VERSION ""

NS_ :

BS_:

BU_: Airbag Allrad EPS Teves_MK60_ESP LWS LWR Teves_MK70_MABS Waehlhebel EPB TRW_ESP ACC_Radar AFS Magne_Ride RKA_Plus Selespeed Waehlhebel_Sele PDC_PLA Lenkhilfe_APA VAQ Daempfer Hybrid_BMS Hybrid_PWR Hybrid_DQ200 EKlimakomp SWA HCA ACC_Lidar Lenkhilfe_ZF_3G FLA AG6 DQ Hybrid_MSG Diesel Otto Gateway_PQ35_A Gateway_PQ46_A Vector_XXX Fzg_CAN

BO_ 648 mMotor_2: 8 Hybrid_MSG
 SG_ MO2_CAN_Vers m0 : 0|6@1+ (1,0) [0|63] ""  AG6,Gateway_PQ46_A,DQ,TRW_ESP,ACC_Radar,Gateway_PQ35_A,Hybrid_DQ200,Selespeed,ACC_Lidar
 SG_ MO2_Mp_Code M : 6|2@1+ (1,0) [0|3] ""  AG6,Gateway_PQ46_A,Allrad,Teves_MK60_ESP,Teves_MK70_MABS,DQ,TRW_ESP,ACC_Radar,Gateway_PQ35_A,RKA_Plus,Hybrid_DQ200,Selespeed,EPB,ACC_Lidar
 SG_ MO2_Kuehlm_T : 8|8@1+ (0.75,-48) [-47.25|142.5] "°C"  AG6,Gateway_PQ46_A,DQ,TRW_ESP,Gateway_PQ35_A,Magne_Ride,RKA_Plus,Hybrid_DQ200,Selespeed,Hybrid_PWR
 SG_ MO2_BTS : 17|1@1+ (1,0) [0|1] ""  AG6,Gateway_PQ46_A,Allrad,DQ,EPB,TRW_ESP,ACC_Radar,Gateway_PQ35_A,Magne_Ride,Hybrid_DQ200,Selespeed,ACC_Lidar
 SG_ MO2_BLS : 16|1@1+ (1,0) [0|1] ""  AG6,Gateway_PQ46_A,Allrad,DQ,EPB,TRW_ESP,ACC_Radar,Gateway_PQ35_A,Magne_Ride,Daempfer,Hybrid_DQ200,Selespeed,ACC_Lidar
 SG_ MO2_Sta_No_Bet : 20|1@1+ (1,0) [0|1] ""  Gateway_PQ46_A,Teves_MK60_ESP,Teves_MK70_MABS,TRW_ESP,Gateway_PQ35_A
 SG_ MO2_Sta_Klima : 19|1@1+ (1,0) [0|1] ""  AG6,Gateway_PQ46_A,DQ,TRW_ESP,Gateway_PQ35_A,Hybrid_DQ200
 SG_ MO2_Status_TSK : 21|1@1+ (1,0) [0|1] ""  Gateway_PQ46_A,TRW_ESP,Gateway_PQ35_A,ACC_Radar,ACC_Lidar
 SG_ MO2_Sta_GRA : 22|2@1+ (1,0) [0|3] ""  AG6,Gateway_PQ46_A,DQ,TRW_ESP,ACC_Radar,Gateway_PQ35_A,RKA_Plus,Hybrid_DQ200,Selespeed,ACC_Lidar
 SG_ MO2_Sta_Kuehlm : 18|1@1+ (1,0) [0|1] ""  AG6,Gateway_PQ46_A,DQ,TRW_ESP,Gateway_PQ35_A,Hybrid_DQ200,Hybrid_PWR
 SG_ MO2_LL_Solldz : 40|8@1+ (10,0) [0|2540] "1/min"  AG6,Gateway_PQ46_A,DQ,TRW_ESP,Gateway_PQ35_A,Hybrid_DQ200,Selespeed
 SG_ MO2_Sport_Error : 27|1@1+ (1,0) [0|1] ""  Gateway_PQ46_A,Gateway_PQ35_A,TRW_ESP
 SG_ MO2_Motor_Code m1 : 0|6@1+ (1,0) [0|63] ""  AG6,Gateway_PQ46_A,DQ,TRW_ESP,ACC_Radar,Gateway_PQ35_A,Hybrid_DQ200,Selespeed,EPB,ACC_Lidar,Teves_MK60_ESP,Teves_MK70_MABS
 SG_ MO2_Mo_ZWR : 56|8@1+ (0.39,0) [0|99.06] "%MDI"  AG6,Gateway_PQ46_A,DQ,TRW_ESP,Gateway_PQ35_A,Hybrid_DQ200
 SG_ MO2_Begr_Mo : 48|8@1+ (0.39,0) [0|99.06] "%MDI"  AG6,Gateway_PQ46_A,DQ,TRW_ESP,Gateway_PQ35_A,Hybrid_DQ200
 SG_ MO2_Getr_Code m2 : 0|6@1+ (1,0) [0|63] ""  AG6,Gateway_PQ46_A,Teves_MK60_ESP,Teves_MK70_MABS,DQ,TRW_ESP,Gateway_PQ35_A,RKA_Plus,Hybrid_DQ200,Selespeed,EPB
 SG_ MO2_max_Mo m3 : 0|6@1+ (10,0) [0|630] "Nm"  AG6,Gateway_PQ46_A,Allrad,DQ,TRW_ESP,Gateway_PQ35_A,RKA_Plus,Hybrid_DQ200,Selespeed,EPB
 SG_ MO2_Sta_Limiter : 24|2@1+ (1,0) [0|3] ""  Gateway_PQ46_A,Gateway_PQ35_A,TRW_ESP
 SG_ MO2_RME_Gehalt : 29|3@1+ (12.5,0) [0|75] "%"  Gateway_PQ46_A,Gateway_PQ35_A,TRW_ESP
 SG_ MO2_GRAregelt : 26|1@1+ (1,0) [0|1] ""  Gateway_PQ46_A,DQ,TRW_ESP,Gateway_PQ35_A,Hybrid_DQ200
 SG_ MO2_OffRoad : 28|1@1+ (1,0) [0|1] ""  AG6,Gateway_PQ46_A,TRW_ESP,Gateway_PQ35_A
 SG_ MO2_GRA_Soll : 32|8@1+ (1.28,0) [0|325.12] "km/h"  AG6,Gateway_PQ46_A,DQ,TRW_ESP,Gateway_PQ35_A,Hybrid_DQ200

BO_ 1416 mMotor_7: 8 Hybrid_MSG
 SG_ MO7_Sta_VBegr : 2|1@1+ (1,0) [0|1] ""  Gateway_PQ46_A,Gateway_PQ35_A
 SG_ MO7_Fehlereintr : 3|1@1+ (1,0) [0|1] ""  Gateway_PQ46_A,Gateway_PQ35_A
 SG_ MO7_DFM : 8|8@1+ (0.4,0) [0|101.6] "%"  Gateway_PQ46_A,Gateway_PQ35_A
 SG_ MO7_Sta_PTC : 5|3@1+ (1,0) [0|7] ""  Gateway_PQ46_A,Gateway_PQ35_A
 SG_ MO7_Fehler_VBegr : 1|1@1+ (1,0) [0|1] ""  Gateway_PQ46_A,Gateway_PQ35_A
 SG_ MO7_StaOeltemp : 4|1@1+ (1,0) [0|1] ""  Gateway_PQ46_A,Gateway_PQ35_A
 SG_ MO7_LL_Solldz : 0|1@1+ (1,0) [0|1] ""  Gateway_PQ46_A,Gateway_PQ35_A
 SG_ MO7_Gradient_Dz : 24|7@1+ (1,0) [0|126] "1/min"  Gateway_PQ46_A,Gateway_PQ35_A
 SG_ MO7_GradientVorz : 31|1@1+ (1,0) [0|1] ""  Gateway_PQ46_A,Gateway_PQ35_A
 SG_ MO7_Hoeheninfo : 16|8@1+ (0.0078125,0) [0|1.984375] ""  Gateway_PQ46_A,DQ,Gateway_PQ35_A,Selespeed,Teves_MK60_ESP,Teves_MK70_MABS,TRW_ESP
 SG_ MO7_RueckLLDz : 47|1@1+ (1,0) [0|1] ""  Gateway_PQ46_A,Gateway_PQ35_A
 SG_ MO7_Oeltemp : 56|8@1+ (1,-60) [-58|194] "°C"  Gateway_PQ46_A,Gateway_PQ35_A,Selespeed
 SG_ MO7_PTC_bereit : 42|2@1+ (1,0) [0|3] ""  Gateway_PQ46_A,Gateway_PQ35_A
 SG_ MO7_Gen_ein : 50|1@1+ (1,0) [0|1] ""  Gateway_PQ46_A,Gateway_PQ35_A
 SG_ MO7_Lastabwurf : 48|2@1+ (1,0) [0|3] ""  Gateway_PQ46_A,Gateway_PQ35_A
 SG_ MO7_StaGluehk : 52|4@1+ (8,0) [0|112] "%"  Gateway_PQ46_A,Gateway_PQ35_A
 SG_ MO7_Lastabw_Heiz : 51|1@1+ (1,0) [0|1] ""  Gateway_PQ46_A,Gateway_PQ35_A
 SG_ MO7_GenLdResp : 40|2@1+ (3,0) [0|9] "s"  Gateway_PQ46_A,Gateway_PQ35_A
 SG_ MO7_SleepInd : 46|1@1+ (1,0) [0|1] ""  Gateway_PQ46_A,Gateway_PQ35_A
 SG_ MO7_Zus_Kuehl : 45|1@1+ (1,0) [0|1] ""  Gateway_PQ46_A,Gateway_PQ35_A
 SG_ MO7_Mot_weckfaehig : 44|1@1+ (1,0) [0|1] ""  Gateway_PQ46_A,Gateway_PQ35_A
 SG_ MO7_Ladedruckneu : 32|8@1+ (0.02,0) [0|5.08] "bar"  Gateway_PQ35_A,Gateway_PQ46_A

BO_ 1408 mMotor_Flexia_neu: 8 Hybrid_MSG
 SG_ MFN_Offset_Nachf m1 : 52|6@1+ (10,0) [0|630] "ml"  Gateway_PQ46_A,Gateway_PQ35_A,TRW_ESP
 SG_ MFN_Ansaugsys m0 : 63|1@1+ (1,0) [0|1] ""  Gateway_PQ46_A,TRW_ESP,Gateway_PQ35_A
 SG_ MFN_Tol_Oelwarn m1 : 58|6@1+ (10,0) [0|630] "ml"  Gateway_PQ46_A,Gateway_PQ35_A,TRW_ESP
 SG_ MFN_AnzMitOel m1 : 40|4@1+ (100,0) [0|1500] ""  Gateway_PQ46_A,Gateway_PQ35_A,TRW_ESP
 SG_ MFN_max_Moment m0 : 32|8@1+ (10,0) [0|2550] "Nm"  Gateway_PQ46_A,Gateway_PQ35_A,TRW_ESP
 SG_ MFN_Motorleistung m0 : 40|9@1+ (1,0) [0|511] "kW"  Gateway_PQ46_A,TRW_ESP,ACC_Radar,Gateway_PQ35_A,EPB,ACC_Lidar
 SG_ MFN_Drz_max_Mo m0 : 24|8@1+ (100,0) [0|25500] "1/min"  Gateway_PQ46_A,Gateway_PQ35_A,TRW_ESP
 SG_ MFN_Hubraum m0 : 56|7@1+ (0.1,0) [0|12.7] "l"  Gateway_PQ46_A,TRW_ESP,Gateway_PQ35_A,EPB
 SG_ MFN_Max_Offset m1 : 44|4@1+ (50,0) [0|750] "ml"  Gateway_PQ46_A,Gateway_PQ35_A,TRW_ESP
 SG_ MFN_KurzzeitMW m1 : 24|8@1+ (15,-1905) [-1890|1905] "ml"  Gateway_PQ46_A,Gateway_PQ35_A,TRW_ESP
 SG_ MFN_Russindex m0 : 8|16@1+ (2E-008,0) [0|0.00131068] ""  Gateway_PQ46_A,Gateway_PQ35_A,TRW_ESP
 SG_ MFN_NormedTrip : 6|1@1+ (1,0) [0|1] ""  Gateway_PQ46_A,Gateway_PQ35_A,TRW_ESP,AG6,DQ
 SG_ MFN_Oelstand m1 : 32|6@1+ (1,0) [0|63] ""  Gateway_PQ46_A,Gateway_PQ35_A,TRW_ESP
 SG_ MFN_Zylinder m0 : 52|4@1+ (1,0) [0|15] ""  Gateway_PQ46_A,Gateway_PQ35_A,TRW_ESP
 SG_ MFN_Zaehler M : 0|2@1+ (1,0) [0|3] ""  Gateway_PQ46_A,TRW_ESP,ACC_Radar,Gateway_PQ35_A,EPB,ACC_Lidar
 SG_ MFN_Verbrenn_Typ : 7|1@1+ (1,0) [0|1] ""  Gateway_PQ46_A,TRW_ESP,Gateway_PQ35_A,EPB
 SG_ MFN_Warmup_Cycle : 5|1@1+ (1,0) [0|1] ""  Gateway_PQ46_A,TRW_ESP,Gateway_PQ35_A,Selespeed,AG6,DQ,Hybrid_BMS,Hybrid_PWR
 SG_ MFN_Verschl m1 : 8|16@1+ (2E-008,0) [0|0.00131068] ""  Gateway_PQ46_A,Gateway_PQ35_A,TRW_ESP
 SG_ MFN_Ventile m0 : 49|3@1+ (1,0) [0|7] ""  Gateway_PQ46_A,Gateway_PQ35_A,TRW_ESP
 SG_ MFN_Drive_Cycle : 4|1@1+ (1,0) [0|1] ""  Gateway_PQ46_A,Gateway_PQ35_A,TRW_ESP,AG6,DQ,Selespeed,Hybrid_BMS,Hybrid_PWR
 SG_ MFN_Anz_Mittel m3 : 44|4@1+ (500,0) [500|7500] ""  Gateway_PQ46_A,Gateway_PQ35_A,TRW_ESP
 SG_ MFN_Oelwarnung m1 : 38|1@1+ (1,0) [0|1] ""  Gateway_PQ46_A,Gateway_PQ35_A,TRW_ESP
 SG_ MFN_Interv_tmax m3 : 54|6@1+ (1,0) [0|63] "Monate"  Gateway_PQ46_A,Gateway_PQ35_A,TRW_ESP
 SG_ MFN_Interv_Wmax m3 : 32|7@1+ (1000,0) [0|127000] "km"  Gateway_PQ46_A,Gateway_PQ35_A,TRW_ESP
 SG_ MFN_Sensorwarn m1 : 39|1@1+ (1,0) [0|1] ""  Gateway_PQ46_A,Gateway_PQ35_A,TRW_ESP
 SG_ MFN_MaxOelst m3 : 39|5@1+ (100,0) [0|3100] "ml"  Gateway_PQ46_A,Gateway_PQ35_A,TRW_ESP
 SG_ MFN_Interv_Wmin m3 : 24|7@1+ (1000,0) [0|127000] "km"  Gateway_PQ46_A,Gateway_PQ35_A,TRW_ESP
 SG_ MFN_Drz_max_Mo_ m2 : 24|8@1+ (100,0) [0|25500] "1/min"  Gateway_PQ46_A,Gateway_PQ35_A,TRW_ESP
 SG_ MFN_Interv_tmin m3 : 48|6@1+ (1,0) [0|63] "Monate"  Gateway_PQ46_A,Gateway_PQ35_A,TRW_ESP
 SG_ MFN_Str_Mittel m3 : 60|4@1+ (25,0) [25|375] "km"  Gateway_PQ46_A,Gateway_PQ35_A,TRW_ESP
 SG_ MFN_Fuell_Erk m3 : 31|1@1+ (1,0) [0|1] ""  Gateway_PQ46_A,Gateway_PQ35_A,TRW_ESP
 SG_ MFN_Hubraum_ m2 : 56|7@1+ (0.1,0) [0|12.7] "l"  Gateway_PQ46_A,TRW_ESP,Gateway_PQ35_A,EPB
 SG_ MFN_Ansaugsys_ m2 : 63|1@1+ (1,0) [0|1] ""  Gateway_PQ46_A,TRW_ESP,Gateway_PQ35_A
 SG_ MFN_max_Moment_ m2 : 32|8@1+ (10,0) [0|2550] "Nm"  Gateway_PQ46_A,Gateway_PQ35_A,TRW_ESP
 SG_ MFN_Motorleistung_ m2 : 40|9@1+ (1,0) [0|511] "kW"  Gateway_PQ46_A,TRW_ESP,ACC_Radar,Gateway_PQ35_A,EPB,ACC_Lidar
 SG_ MFN_Zylinder_ m2 : 52|4@1+ (1,0) [0|15] ""  Gateway_PQ46_A,Gateway_PQ35_A,TRW_ESP
 SG_ MFN_Ventile_ m2 : 49|3@1+ (1,0) [0|7] ""  Gateway_PQ46_A,Gateway_PQ35_A,TRW_ESP
 SG_ MFN_Russindex_ m2 : 8|16@1+ (2E-008,0) [0|0.00131068] ""  Gateway_PQ46_A,Gateway_PQ35_A,TRW_ESP
 SG_ MFN_Fuell_Hyst m1 : 48|4@1+ (50,0) [0|750] "ml"  Gateway_PQ46_A,Gateway_PQ35_A,TRW_ESP
 SG_ MFN_Zaehler_ : 2|2@1+ (1,0) [0|3] ""  Gateway_PQ46_A,TRW_ESP,Gateway_PQ35_A,EPB
 SG_ MFN_Verschl_ m3 : 8|16@1+ (2E-008,0) [0|0.00131068] ""  Gateway_PQ46_A,Gateway_PQ35_A,TRW_ESP

BO_ 1160 mMotor_6: 8 Hybrid_MSG
 SG_ MO6_Hoeheninfo : 24|8@1+ (0.0078125,0) [0|1.984375] ""  DQ,Hybrid_DQ200
 SG_ MO6_SollM_Getr : 8|8@1+ (0.39,0) [0|99.06] "%MDI"  Selespeed
 SG_ MO6_Checksum : 0|8@1+ (1,0) [0|255] "" Vector__XXX
 SG_ MO6_GRA_Soll : 32|8@1+ (0.024,-3.984) [-3.984|2.112] "m/s²"  AG6,DQ,Hybrid_DQ200
 SG_ MO6_MomIntGeEing : 40|8@1+ (0.39215686275,0) [0|100] "%"  DQ,Hybrid_DQ200
 SG_ MO6_Freigabe_GRA : 56|1@1+ (1,0) [0|1] "" Vector__XXX
 SG_ MO6_Schutz_Toel : 57|1@1+ (1,0) [0|1] "" Vector__XXX
 SG_ MO6_Ist_Moment : 16|8@1+ (0.39,0) [0|99.06] "%MDI"  AG6,DQ,Hybrid_DQ200,Selespeed,Gateway_PQ35_A,Gateway_PQ46_A
 SG_ MO6_RegPartikel : 59|1@1+ (1,0) [0|1] ""  AG6,DQ,Hybrid_DQ200
 SG_ MO6_Luftpfad_akt : 58|1@1+ (1,0) [0|1] "" Vector__XXX
 SG_ MO6_FF_Mux00 m0 : 48|8@1+ (0.39215686275,0) [0|100] "%"  Selespeed,Hybrid_PWR
 SG_ MO6_FF_Mux01 m1 : 48|8@1+ (0.39215686275,0) [0|100] "%"  Selespeed,Hybrid_PWR
 SG_ MO6_FF_Mux02 m2 : 48|8@1+ (1,-40) [-40|215] "°C"  Selespeed,Hybrid_PWR
 SG_ MO6_FF_Mux03 m3 : 48|8@1+ (3.137254902,0) [0|800] "%"  Selespeed,Hybrid_PWR
 SG_ MO6_Zaehler M : 60|4@1+ (1,0) [0|15] ""  DQ,Hybrid_DQ200,Selespeed,Hybrid_PWR
 SG_ MO6_FF_Mux05 m5 : 48|8@1+ (1,0) [0|255] ""  Selespeed
 SG_ MO6_FF_Mux06 m6 : 48|8@1+ (1,0) [0|255] ""  Selespeed
 SG_ MO6_FF_Mux04 m4 : 48|8@1+ (0.39215686275,0) [0|100] "%"  Selespeed,Hybrid_PWR
 SG_ MO6_FF_Mux08 m8 : 48|8@1+ (1,0) [0|255] ""  Selespeed
 SG_ MO6_FF_Mux07 m7 : 48|8@1+ (1,0) [0|255] ""  Selespeed
 SG_ MO6_FF_Mux09 m9 : 48|8@1+ (1,0) [0|255] ""  Selespeed
 SG_ MO6_FF_Mux10 m10 : 48|8@1+ (1,0) [0|255] ""  Selespeed
 SG_ MO6_FF_Mux11 m11 : 48|8@1+ (1,0) [0|255] ""  Selespeed
 SG_ MO6_FF_Mux12 m12 : 48|8@1+ (1,0) [0|255] ""  Selespeed
 SG_ MO6_FF_Mux14 m14 : 48|8@1+ (1,0) [0|255] ""  Selespeed
 SG_ MO6_FF_Mux13 m13 : 48|8@1+ (1,0) [0|255] ""  Selespeed
 SG_ MO6_FF_Mux15 m15 : 48|8@1+ (1,0) [0|255] ""  Selespeed

BO_ 1152 mMotor_5: 8 Hybrid_MSG
 SG_ MO5_max_Moment m0 : 0|6@1+ (10,0) [0|630] "Nm"  Gateway_PQ46_A,Gateway_PQ35_A,Teves_MK60_ESP,Teves_MK70_MABS
 SG_ MO5_res_08 : 8|1@1+ (1,0) [0|1] ""  Gateway_PQ46_A,Gateway_PQ35_A,Teves_MK70_MABS,Teves_MK60_ESP
 SG_ MO5_Mp_Code M : 6|2@1+ (1,0) [0|3] ""  Gateway_PQ46_A,Allrad,Teves_MK60_ESP,Gateway_PQ35_A,Teves_MK70_MABS
 SG_ MO5_Vorgluehen : 9|1@1+ (1,0) [0|1] ""  Gateway_PQ46_A,Gateway_PQ35_A,Teves_MK60_ESP,Teves_MK70_MABS
 SG_ MO5_E_Gas : 10|1@1+ (1,0) [0|1] ""  Gateway_PQ46_A,Gateway_PQ35_A,Teves_MK60_ESP,Teves_MK70_MABS
 SG_ MO5_OBD_2 : 11|1@1+ (1,0) [0|1] ""  Gateway_PQ46_A,Gateway_PQ35_A,Teves_MK60_ESP,Teves_MK70_MABS
 SG_ MO5_KliKo_Red : 15|1@1+ (1,0) [0|1] ""  Gateway_PQ46_A,Gateway_PQ35_A,Teves_MK60_ESP,Teves_MK70_MABS
 SG_ MO5_Heissl : 12|1@1+ (1,0) [0|1] ""  Gateway_PQ46_A,Gateway_PQ35_A,Teves_MK60_ESP,Teves_MK70_MABS
 SG_ MO5_KlimaKompr : 13|1@1+ (1,0) [0|1] ""  Gateway_PQ46_A,Gateway_PQ35_A,Teves_MK60_ESP,Teves_MK70_MABS,EKlimakomp
 SG_ MO5_Feld_kuehl : 14|1@1+ (1,0) [0|1] ""  Gateway_PQ46_A,Gateway_PQ35_A,Teves_MK60_ESP,Teves_MK70_MABS
 SG_ MO5_Verbrauch : 16|15@1+ (1,0) [0|32767] "µl"  Gateway_PQ46_A,Gateway_PQ35_A,Teves_MK60_ESP,Teves_MK70_MABS
 SG_ MO5_UeberlVerb : 31|1@1+ (1,0) [0|1] ""  Gateway_PQ46_A,Gateway_PQ35_A,Teves_MK60_ESP,Teves_MK70_MABS
 SG_ MO5_Momente : 51|1@1+ (1,0) [0|1] ""  AG6,Gateway_PQ46_A,Teves_MK60_ESP,Teves_MK70_MABS,Gateway_PQ35_A,Selespeed,RKA_Plus,DQ
 SG_ MO5_Luefter : 32|8@1+ (0.4,0) [0|101.6] "%"  Gateway_PQ46_A,Gateway_PQ35_A,Teves_MK60_ESP,Teves_MK70_MABS,DQ
 SG_ MO5_Checksumme : 56|8@1+ (1,0) [0|255] ""  Gateway_PQ46_A,Gateway_PQ35_A,Teves_MK60_ESP,Teves_MK70_MABS
 SG_ MO5_Start : 48|1@1+ (1,0) [0|1] ""  Gateway_PQ46_A,Gateway_PQ35_A,Teves_MK60_ESP,Teves_MK70_MABS
 SG_ MO5_HLeuchte : 40|1@1+ (1,0) [0|1] ""  Gateway_PQ46_A,Gateway_PQ35_A,Teves_MK60_ESP,Teves_MK70_MABS
 SG_ MO5_Anlasser : 49|1@1+ (1,0) [0|1] ""  Gateway_PQ46_A,Gateway_PQ35_A,Teves_MK60_ESP,Teves_MK70_MABS
 SG_ MO5_Motortext1 : 52|1@1+ (1,0) [0|1] ""  Gateway_PQ46_A,Gateway_PQ35_A,Teves_MK60_ESP,Teves_MK70_MABS
 SG_ MO5_GRA_Hauptsch : 50|1@1+ (1,0) [0|1] ""  Gateway_PQ46_A,ACC_Radar,Gateway_PQ35_A,ACC_Lidar,Teves_MK60_ESP,Teves_MK70_MABS
 SG_ MO5_Interlock : 47|1@1+ (1,0) [0|1] ""  Gateway_PQ46_A,Gateway_PQ35_A,Teves_MK60_ESP,Teves_MK70_MABS
 SG_ MO5_Motortyp m2 : 0|6@1+ (1,0) [0|63] ""  Gateway_PQ46_A,Allrad,Gateway_PQ35_A,Teves_MK60_ESP,Teves_MK70_MABS
 SG_ MO5_Sta_BKU : 42|1@1+ (1,0) [0|1] ""  Gateway_PQ46_A,Gateway_PQ35_A,Teves_MK70_MABS,Teves_MK60_ESP
 SG_ MO5_Drehzahl m1 : 0|6@1+ (100,0) [0|6300] "1/min"  Gateway_PQ46_A,Gateway_PQ35_A,Teves_MK60_ESP,Teves_MK70_MABS
 SG_ MO5_TypStartSteu : 43|1@1+ (1,0) [0|1] ""  Gateway_PQ46_A,Gateway_PQ35_A,Teves_MK60_ESP,Teves_MK70_MABS
 SG_ MO5_PartikelLamp : 41|1@1+ (1,0) [0|1] ""  Gateway_PQ46_A,Gateway_PQ35_A,Teves_MK60_ESP,Teves_MK70_MABS
 SG_ MO5_Motortext4 : 55|1@1+ (1,0) [0|1] ""  Gateway_PQ46_A,Gateway_PQ35_A,Teves_MK60_ESP,Teves_MK70_MABS
 SG_ MO5_TDE_Text : 45|1@1+ (1,0) [0|1] ""  Gateway_PQ46_A,Gateway_PQ35_A,Teves_MK60_ESP,Teves_MK70_MABS
 SG_ MO5_Motortext3 : 54|1@1+ (1,0) [0|1] ""  Gateway_PQ46_A,Gateway_PQ35_A,Teves_MK60_ESP,Teves_MK70_MABS
 SG_ MO5_Motortext2 : 53|1@1+ (1,0) [0|1] ""  Gateway_PQ46_A,Gateway_PQ35_A,Teves_MK70_MABS,Teves_MK60_ESP
 SG_ MO5_Abgastyp2 m3 : 1|1@1+ (1,0) [0|1] ""  Gateway_PQ46_A,Gateway_PQ35_A,Teves_MK60_ESP,Teves_MK70_MABS
 SG_ MO5_TDE_Lampe : 44|1@1+ (1,0) [0|1] ""  Gateway_PQ46_A,Gateway_PQ35_A,Teves_MK60_ESP,Teves_MK70_MABS
 SG_ MO5_Abgastyp m3 : 0|1@1+ (1,0) [0|1] ""  Gateway_PQ46_A,Gateway_PQ35_A
 SG_ MO5_DZM_Daempf : 46|1@1+ (1,0) [0|1] ""  Gateway_PQ46_A,Gateway_PQ35_A,Teves_MK60_ESP,Teves_MK70_MABS
 SG_ MO5_Abgastyp3 m3 : 2|1@1+ (1,0) [0|1] ""  Gateway_PQ35_A,Gateway_PQ46_A,Teves_MK60_ESP,Teves_MK70_MABS
 SG_ MO5_DPF_reg m3 : 5|1@1+ (1,0) [0|1] ""  Gateway_PQ35_A,Gateway_PQ46_A,Teves_MK60_ESP,Teves_MK70_MABS

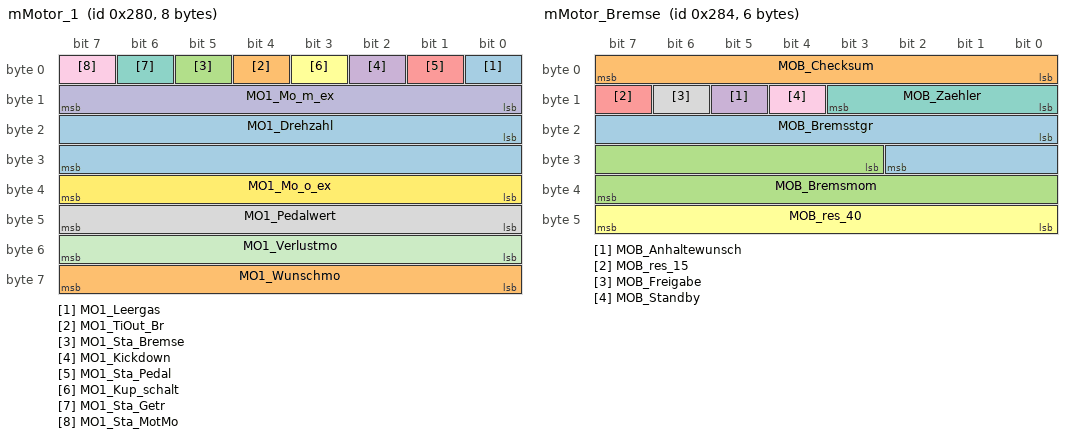
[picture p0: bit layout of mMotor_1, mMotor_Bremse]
BO_ 640 mMotor_1: 8 Hybrid_MSG
 SG_ MO1_Leergas : 0|1@1+ (1,0) [0|1] ""  AG6,Gateway_PQ46_A,Teves_MK60_ESP,Teves_MK70_MABS,DQ,TRW_ESP,Gateway_PQ35_A,Hybrid_DQ200
 SG_ MO1_TiOut_Br : 4|1@1+ (1,0) [0|1] ""  Gateway_PQ46_A,Gateway_PQ35_A,TRW_ESP
 SG_ MO1_Sta_Bremse : 5|1@1+ (1,0) [0|1] ""  Gateway_PQ46_A,Teves_MK60_ESP,Teves_MK70_MABS,TRW_ESP,Gateway_PQ35_A,EPB
 SG_ MO1_Kickdown : 2|1@1+ (1,0) [0|1] ""  AG6,Gateway_PQ46_A,DQ,TRW_ESP,Gateway_PQ35_A,Hybrid_DQ200,Selespeed
 SG_ MO1_Sta_Pedal : 1|1@1+ (1,0) [0|1] ""  AG6,Gateway_PQ46_A,Teves_MK60_ESP,Teves_MK70_MABS,TRW_ESP,Gateway_PQ35_A,Lenkhilfe_APA
 SG_ MO1_Kup_schalt : 3|1@1+ (1,0) [0|1] ""  Gateway_PQ46_A,Allrad,Teves_MK60_ESP,Teves_MK70_MABS,EPB,TRW_ESP,ACC_Radar,Gateway_PQ35_A,RKA_Plus,ACC_Lidar
 SG_ MO1_Sta_Getr : 6|1@1+ (1,0) [0|1] ""  AG6,Gateway_PQ46_A,DQ,TRW_ESP,Gateway_PQ35_A,Hybrid_DQ200
 SG_ MO1_Pedalwert : 40|8@1+ (0.4,0) [0|101.6] "%"  AG6,Gateway_PQ46_A,Allrad,Teves_MK60_ESP,LWR,Teves_MK70_MABS,DQ,TRW_ESP,ACC_Radar,AFS,Gateway_PQ35_A,Hybrid_DQ200,Selespeed,ACC_Lidar,Lenkhilfe_APA,Lenkhilfe_ZF_3G,EPS
 SG_ MO1_Sta_MotMo : 7|1@1+ (1,0) [0|1] ""  AG6,Gateway_PQ46_A,Teves_MK60_ESP,Teves_MK70_MABS,DQ,TRW_ESP,Gateway_PQ35_A,RKA_Plus,Hybrid_DQ200,Selespeed
 SG_ MO1_Mo_m_ex : 8|8@1+ (0.39,0) [0|99.06] "%MDI"  AG6,Gateway_PQ46_A,Allrad,Teves_MK60_ESP,Teves_MK70_MABS,DQ,TRW_ESP,Gateway_PQ35_A,Magne_Ride,RKA_Plus,Hybrid_DQ200,Selespeed
 SG_ MO1_Verlustmo : 48|8@1+ (0.39,0) [0|99.06] "%MDI"  AG6,Gateway_PQ46_A,Allrad,Teves_MK60_ESP,Teves_MK70_MABS,DQ,TRW_ESP,Gateway_PQ35_A,Magne_Ride,RKA_Plus,Hybrid_DQ200,Selespeed
 SG_ MO1_Mo_o_ex : 32|8@1+ (0.39,0) [0|99.06] "%MDI"  AG6,Gateway_PQ46_A,Teves_MK60_ESP,Teves_MK70_MABS,DQ,TRW_ESP,Gateway_PQ35_A,Hybrid_DQ200
 SG_ MO1_Drehzahl : 16|16@1+ (0.25,0) [0|16256] "1/min"  AG6,Gateway_PQ46_A,Allrad,EPS,Teves_MK60_ESP,LWR,Teves_MK70_MABS,DQ,EPB,TRW_ESP,ACC_Radar,AFS,Gateway_PQ35_A,Magne_Ride,RKA_Plus,Lenkhilfe_APA,Hybrid_DQ200,HCA,Selespeed,ACC_Lidar,Lenkhilfe_ZF_3G,Hybrid_PWR,Airbag
 SG_ MO1_Wunschmo : 56|8@1+ (0.39,0) [0|99.06] "%MDI"  Gateway_PQ46_A,Teves_MK60_ESP,Teves_MK70_MABS,DQ,TRW_ESP,Gateway_PQ35_A,Magne_Ride,Daempfer,Hybrid_DQ200,Selespeed,Allrad

BO_ 1154 mMotor_Hybrid_1: 8 Hybrid_MSG
 SG_ MH1_VM_Mom_oE : 0|8@1+ (0.8,-100) [-100|103.2] "%MDI"  Hybrid_DQ200
 SG_ MH1_IstStatusK0 : 8|2@1+ (1,0) [0|3] ""  Hybrid_DQ200
 SG_ MH1_Startmodus_PQ35 : 10|1@1+ (1,0) [0|1] ""  Hybrid_DQ200
 SG_ MH1_VM_aktiv : 11|1@1+ (1,0) [0|1] ""  Hybrid_DQ200
 SG_ MH1_Zielzustand_Hybrid : 12|3@1+ (1,0) [0|7] ""  Hybrid_DQ200
 SG_ MH1_VerlParam_Msum m1 : 16|2@1+ (1,0) [0|3] ""  Hybrid_DQ200
 SG_ MH1_E_Faktor m0 : 20|4@1+ (1,0) [0|15] ""  Hybrid_DQ200
 SG_ MH1_Drehzahl_VM : 24|16@1+ (0.25,0) [0|16256] "1/min"  Hybrid_DQ200
 SG_ MH1_Schaltverh : 15|1@1+ (1,0) [0|1] ""  Hybrid_DQ200
 SG_ MH1_max_ind_VM_Mom : 40|8@1+ (0.39,0) [0|99.06] "%MDI" Vector__XXX
 SG_ MH1_Startmodus_PL71 : 48|3@1+ (1,0) [0|7] "" Vector__XXX
 SG_ MH1_ACCGRA_aktiv M : 52|1@1+ (1,0) [0|1] ""  Hybrid_DQ200
 SG_ MH1_LowSpeedModus : 51|1@1+ (1,0) [0|1] ""  Hybrid_DQ200
 SG_ MH1_Bremspedalwert : 56|8@1+ (0.4,0) [0|100] "%" Vector__XXX
 SG_ MH1_QB_Bremspedalwert : 55|1@1+ (1,0) [0|1] "" Vector__XXX
 SG_ MH1_res_52 : 53|2@1+ (1,0) [0|3] "" Vector__XXX
 SG_ MH1_MomVerlauf_EM m1 : 18|6@1+ (5,0) [0|315] "Nm"  Hybrid_DQ200

BO_ 1657 BAP_HYB: 8 Hybrid_MSG
 SG_ BAP_Data_HYB : 0|16@1+ (1,0) [0|65535] ""  Gateway_PQ46_A,Gateway_PQ35_A
 SG_ BAP_var_HYB : 16|48@1+ (1,0) [0|2.8147497671E+014] ""  Gateway_PQ46_A,Gateway_PQ35_A

BO_ 2024 ISO_MO_01_Resp: 8 Hybrid_MSG
 SG_ ISO_MO_01_Resp_Data : 0|64@1+ (1,0) [0|1.8446744074E+019] ""  Gateway_PQ35_A,Gateway_PQ46_A

BO_ 644 mMotor_Bremse: 6 Diesel
 SG_ MOB_Bremsstgr : 16|11@1+ (0.048851978505,0) [0|100] "%"  TRW_ESP,Teves_MK60_ESP
 SG_ MOB_Checksum : 0|8@1+ (1,0) [0|255] ""  TRW_ESP,Teves_MK60_ESP
 SG_ MOB_Bremsmom : 27|13@1+ (4,0) [0|32760] "Nm"  TRW_ESP,Teves_MK60_ESP
 SG_ MOB_Anhaltewunsch : 13|1@1+ (1,0) [0|1] ""  TRW_ESP,Teves_MK60_ESP,DQ
 SG_ MOB_res_15 : 15|1@1+ (1,0) [0|1] ""  TRW_ESP,Teves_MK60_ESP
 SG_ MOB_res_40 : 40|8@1+ (1,0) [0|255] ""  TRW_ESP,Teves_MK60_ESP
 SG_ MOB_Zaehler : 8|4@1+ (1,0) [0|15] ""  TRW_ESP,Teves_MK60_ESP
 SG_ MOB_Freigabe : 14|1@1+ (1,0) [0|1] ""  Gateway_PQ46_A,TRW_ESP,Gateway_PQ35_A,Teves_MK60_ESP
 SG_ MOB_Standby : 12|1@1+ (1,0) [0|1] ""  TRW_ESP,Teves_MK60_ESP

BO_ 1162 mMotor_8: 8 Diesel
 SG_ MO8_LampeDZBegr : 24|1@1+ (1,0) [0|1] ""  Gateway_PQ35_A
 SG_ MO8_Zaehler : 60|4@1+ (1,0) [0|15] ""  Gateway_PQ35_A,Magne_Ride
 SG_ MO8_Checksumme : 0|8@1+ (1,0) [0|255] ""  Gateway_PQ35_A,Magne_Ride
 SG_ MO8_res_20 : 20|1@1+ (1,0) [0|1] ""  Gateway_PQ35_A
 SG_ MO8_Spoiler_ausf : 22|1@1+ (1,0) [0|1] ""  Gateway_PQ35_A
 SG_ MO8_AnzeigeDZ : 8|12@1+ (3,0) [0|12282] "rpm"  Gateway_PQ35_A
 SG_ MO8_SGT_Soundakt : 21|1@1+ (1,0) [0|1] ""  Gateway_PQ35_A
 SG_ MO8_Enable_Oeldr_Motor : 25|1@1+ (1,0) [0|1] ""  Gateway_PQ35_A
 SG_ MO8_Sportschalter : 23|1@1+ (1,0) [0|1] ""  Gateway_PQ35_A,Selespeed,Magne_Ride
 SG_ MO8_res_30 : 30|1@1+ (1,0) [0|1] ""  Gateway_PQ35_A
 SG_ MO8_Oeldr_Warn_Motor : 26|1@1+ (1,0) [0|1] ""  Gateway_PQ35_A
 SG_ MO8_res_29 : 29|1@1+ (1,0) [0|1] ""  Gateway_PQ35_A
 SG_ MO8_GRA_v_Wunsch : 32|9@1+ (1,0) [0|511] "km/h"  Gateway_PQ35_A
 SG_ MO8_Avus_Motorschutz : 27|2@1+ (1,0) [0|1] ""  Gateway_PQ35_A
 SG_ MO8_Nachlauf_ZWP : 42|6@1+ (15,0) [0|945] "s"  Gateway_PQ35_A
 SG_ MO8_res_41 : 41|1@1+ (1,0) [0|1] ""  Gateway_PQ35_A
 SG_ MO8_res_31 : 31|1@1+ (1,0) [0|1] ""  Gateway_PQ35_A
 SG_ MO8_res_48 : 48|8@1+ (1,0) [0|255] ""  Gateway_PQ35_A
 SG_ MO8_res_56 : 56|1@1+ (1,0) [0|1] ""  Gateway_PQ35_A
 SG_ MO8_res_58 : 58|1@1+ (1,0) [0|1] ""  Gateway_PQ35_A
 SG_ MO8_res_57 : 57|1@1+ (1,0) [0|1] ""  Gateway_PQ35_A
 SG_ MO8_res_59 : 59|1@1+ (1,0) [0|1] ""  Gateway_PQ35_A

BO_TX_BU_ 648 : Otto,Diesel,Hybrid_MSG;
BO_TX_BU_ 1416 : Otto,Diesel,Hybrid_MSG;
BO_TX_BU_ 1408 : Otto,Diesel,Hybrid_MSG;
BO_TX_BU_ 1160 : Otto,Diesel,Hybrid_MSG;
BO_TX_BU_ 1152 : Otto,Diesel,Hybrid_MSG;
BO_TX_BU_ 640 : Otto,Diesel,Hybrid_MSG;
BO_TX_BU_ 2024 : Otto,Diesel,Hybrid_MSG;
BO_TX_BU_ 644 : Otto,Diesel;
BO_TX_BU_ 1162 : Otto,Diesel;
CM_ SG_ 648 MO2_CAN_Vers "Multiplex-Info (CAN-Version)
CAN-Version";
CM_ SG_ 648 MO2_Mp_Code "Multiplex-Code
Multiplex-Code und Multiplex-Info sind verkettet; der Multiplex-Code wird nach 4 Übertragungen weitergeschaltet; dieser Mechanismus wiederholt sich somit nach 4 x 4 = 16 Umlaufzeiten;";
CM_ SG_ 648 MO2_Kuehlm_T "Kühlmitteltemperatur (Motor 2)
Motor-Kühlmitteltemperatur oder ErsatzwertInitwert 0 ist außerhalb des Wertebereichs";
CM_ SG_ 648 MO2_BTS "Bremstestschalter
Ein Empfänger kann BLS und BTS miteinander plausibilisieren (0 für nicht verbaut)Fzg. ohne BTS (z.B. PQ46): Bit aus Bremse 1, Byte 2, Bit 3 Bremsdruckschwelle überschritten wird gespiegeltTouareg GP: siehe ´Spezifikation Schnittstelle und Verhalten bei Fahrerbremsung für Motorsteuergerät und Bremsensteuergerät im Touareg GP´, Autor M. Williges";
CM_ SG_ 648 MO2_BLS "Bremslichtschalter
Ungefiltertes Rohsignal (Fzg. ohne BLS (z. B. Touareg GP): siehe ´Spezifikation Schnittstelle und Verhalten bei Fahrerbremsung für Motorsteuergerät und Bremsensteuergerät im Touareg GP´, Autor M. Williges)";
CM_ SG_ 648 MO2_Sta_No_Bet "Status Normalbetrieb
Normalbetrieb steht für Klemme 15 ein, Initialisierungsphase abgeschlossen und kein Motorstartvorgang (aus Sicht des Motorsteuergerätes)";
CM_ SG_ 648 MO2_Sta_Klima "Ansteuerung Klima
Zustand des Klimakompressors, d.h. Rückmeldung der bidirektionalen Schnittstelle (konventionell Oder CAN)";
CM_ SG_ 648 MO2_Status_TSK "Status Triebstrangkoordinator
Status Triebstrangkoordinator (gültig ab Antrieb-CAN-Version 5.1.x)(Info: war OBD2 freeze frame)";
CM_ SG_ 648 MO2_Sta_GRA "GRA-Status
00 steht auch für nicht verbaut und ADR nicht zulässig; 01 bedeutet eingeschaltet, GRA vom Fahrer aktiviert und z.Zt. im Regelbetrieb oder ADR erlaubt; 10 Fahrer gibt mehr Gas als der Regler; 11 Fehler in Motorsteuerung  oder Time out oder CS-Fehler in Botschaft ADR1  oder Anforderung des ADR trotz 00 in diesen beiden Bits ";
CM_ SG_ 648 MO2_Sta_Kuehlm "Fehlerstatus Kühlmitteltemperatur (Motor 2)
n i.O. steht für Ersatzwert oder Fehlerwert in Byte 2";
CM_ SG_ 648 MO2_LL_Solldz "Leerlaufsolldrehzahl (Motor 2)
statischer Vorgabewert für CVT GetriebeHybrid PQ35 und Hybrid PL71:Verbrennungsmotor-LL-Soll-DZ soll bei KL15 ein immer gesendet werden.";
CM_ SG_ 648 MO2_Sport_Error "Sport Error
Bit wird gesetzt, wenn die Funktion ´Sport´ durch das Motor SG nicht realisiert werden kann (nur Otto im Porsche Cayenne)(Info: Byte 4 war Fahrzeuggeschwindigkeit teilw. noch im PQ24,T5GP)";
CM_ SG_ 648 MO2_Motor_Code "Multiplex-Info (Motor-Kodierinfo)
Motor-Kodierinfo";
CM_ SG_ 648 MO2_Mo_ZWR "Min. Motormoment bei Zündwinkelrücknahme
nur bei Otto-Motoren (Diesel setzt Byte auf 0)Hybrid:Ist ein indiziertes Moment.Eingriffe auf das Kurbelwellenmoment sind auch mittels E-Maschine möglich, jedoch nur im Rahmen des ind. Momentes oE aus Motor_1, => Größe kann nur >=0 sein.";
CM_ SG_ 648 MO2_Begr_Mo "Begrenzungsmoment
inneres maximal mögliches Moment bei einer Drehzahl (z.B. Rauch-begrenzung oder Fehlerfall)Hybrid (Signal Max. mögl. ind. Moment):Ist ein indiziertes Moment.Max. mögliches positives E-Maschinen-Moment muss hier aufaddiert werden.Größe kann nur >= 0 sein.";
CM_ SG_ 648 MO2_Getr_Code "Multiplex-Info (Getriebe-Kodierinfo)
Getriebe-Kodierinfo";
CM_ SG_ 648 MO2_max_Mo "Multiplex-Info (maximales Moment)
maximales Moment (Normierwert MDI)";
CM_ SG_ 648 MO2_Sta_Limiter "Status Speedlimiter
Kombi schaltet bei <>0 auf Limiter-Anzeige um (z. Zt. kein Einsatz geplant)(Info: Byte 4 war Fahrzeuggeschwindigkeit teilw. noch im PQ25,T5GP)";
CM_ SG_ 648 MO2_RME_Gehalt "RME-Gehalt
Rapsölmethylester-Gehalt (Diesel) (wird z. Zt. nicht bedient)(Info: Byte 4 war Fahrzeuggeschwindigkeit teilw. noch im PQ25,T5GP)";
CM_ SG_ 648 MO2_GRAregelt "GRA regelt auf angezeigte Geschwindigkeit
GRA regelt auf die im Kombi angezeigte Geschwindigkeit: 'GRA High Funktion' (z.Zt. nur in Fahrzeugen mit neuer Konzern-GRA, z.B. PQ46)(Info: Byte 4 war Fahrzeuggeschwindigkeit teilw. noch im PQ25,T5GP)";
CM_ SG_ 648 MO2_OffRoad "OffRoad-Modus aktiv
OffRoad-Modus aktiv (nur VW416)Zuschaltung folgender Funktionen: Anfahrhilfe, flache Fahrpedalkennung, AQ Gangstufenvorwahl, Hill Descent Control(Info: Byte 4 war Fahrzeuggeschwindigkeit teilw. noch im PQ25,T5GP)";
CM_ SG_ 648 MO2_GRA_Soll "Soll-Geschwindigkeit bei GRA-Betrieb
eingestellte GRA-SollgeschwindigkeitAchtung: Nicht für neue Projekte verwenden, nachdem neue GRA implementiert ist!Entfall/Umdefinition geplant. Alternative Größe in Botschaft ACC_GRA_Anzeige.";
CM_ SG_ 1416 MO7_Sta_VBegr "Statusbit Geschwindigkeitsbegrenzung aktiv
Motor begrenzt aktuell die Geschwindigkeit des Fahrzeugs; Reaktion auf externe oder interne Anforderung";
CM_ SG_ 1416 MO7_Fehlereintr "Fehlerspeichereintrag (Motor 7)
Bei gesetztem Bit ist mindestens ein Kundendienstfehler eingetragen";
CM_ SG_ 1416 MO7_DFM "Klemme_DFM
Meßwert Tastverhältnis DFM-Signal (Nicht Audi D3 / C6!) (bei umgesetzter neuer Generatorschnittstelle wird das Signal im Colorado GP, D1GP/BY61x und Phaeton ab MJ07 nicht mehr bedient (abhängig vom Motor-Projekt))";
CM_ SG_ 1416 MO7_Sta_PTC "PTC/Glühstifte ausgeschaltet
Rückmeldung für das Lastmanagement, daß die PTC / Glühstifte ausgeschaltet wurden; z. Zt nur beim Diesel gefordert  (nur VW)";
CM_ SG_ 1416 MO7_Fehler_VBegr "Geschwindigkeitsbegrenzung aktivierbar
Fehlerbit wird vom Motor-SG gesetzt, wenn dieses nicht in die Geschwindigkeits-begrenzung gehen kann, ein Fehler während der v-Begrenzung auftritt oder v > v(begr.) - v(delta)";
CM_ SG_ 1416 MO7_StaOeltemp "Fehlerstatus Öltemperatur
n.i.O. steht für Fehlerwert, außerhalb des Meßbereichs (ungenau), nicht verbaut oder noch kein aktueller Wert; Info aus Aufbereitung der TOG-Botschaft (nicht VW D1/Colorado, aber im Touareg GP/ D1 GP)* Initwert 1 bei nicht verbautem Sensor oder nicht verfügbarer Sensorinformation aus TOG-Botschaft";
CM_ SG_ 1416 MO7_LL_Solldz "Rückmeldung Leerlauf-Solldrehzahl 1 für Lastmanagement
Leerlauf-Solldrehzahl wurde angehoben, weil BSG_Last, Byte 2, Bit 0 oder Energiemananager 1, Byte 1, Bit 0 gesetzt war oder eine Klimaanforderung vorlag";
CM_ SG_ 1416 MO7_Gradient_Dz "Motordrehzahlgradient
Differenz der Motordrehzahlen n(t) - n(t-20msec) aus der CAN-Botschaft 'Motor 1'";
CM_ SG_ 1416 MO7_GradientVorz "Vorzeichen Motordrehzahlgradient
Positiv steht für steigende Drehzahl; Negativ für fallende Drehzahl";
CM_ SG_ 1416 MO7_Hoeheninfo "Höheninfo (Motor 7)
Korrekturfaktor Höhe (1 entspricht 1013 mbar; 0,9 entspricht 1000m; 0,8 entspricht 2000m; 1,1 entspricht 1000m), verlegt aus Motor 6 Botschaft!";
CM_ SG_ 1416 MO7_RueckLLDz "Rueckmeldung_Leerlauf-Solldrehzahl 2
Leerlauf-Solldrehzahl wurde aufgrund einer Lastmanagement-Anforderung (BSG_Last Byte 1, Bit 5 oder Energiemanager 1, Byte 1, Bit 1) auf die zweite Stufe angehoben(nicht VW D1/Colorado)";
CM_ SG_ 1416 MO7_Oeltemp "Öltemperatur
realer Meßbereich ca. -40..150 Grad; 0 für nicht verbaut;Info aus Aufbereitung der TOG-Botschaft(nicht VW D1/Colorado, aber im Touareg GP/D1 GP)";
CM_ SG_ 1416 MO7_PTC_bereit "Bereitschaft PTC-Heizung
Bereitschaft dreistufiges PTC !!! (im AU716 und C6 ab 22/08)";
CM_ SG_ 1416 MO7_Gen_ein "Einschalten-Generator
Einschalten des Generators nach Motorstart. Einschalten evtl. mit Load-Response.Anmerkung: Solange der Generator ausgeschaltet ist, bleiben auch die Hochleistungsheizsysteme deaktiviert. Spätestens 5 s nach Motorstart wird der Generator  zugeschaltet unabhängig vom Einschaltsignal!(im AU716 und C6 ab 22/08, nicht VW D1/Colorado außer V6 TDI, nicht PQ35/46)";
CM_ SG_ 1416 MO7_Lastabwurf "Lastabwurf (nur Generatorspannung)
Anforderung eines Lastabwurfs (für Notlauf):Stufe 0: Keine Reduktion der GeneratorspannungStufe 1: Generatorspannung = 13,3VStufe 2: Generatorspannung = 12,6VStufe 3: Generatorspannung = 11,8VAnmerkung: Stufe 3 nur für äußersten Notfall!Schaltaktionen erfolgen seitens BEM mit Load-Response.Solange die Generatorspannung reduziert ist, bleiben auch die Hochleistungsheizsysteme (Frontscheiben-heizung und PTC-Heizung) ausgeschaltet. Die Reduktion der Generatorspannung auf St";
CM_ SG_ 1416 MO7_StaGluehk "Gluehkerzen_Brennraum
Einschaltzustand der Gluehkerzenheizung in Prozent (nicht VW D1/Colorado)";
CM_ SG_ 1416 MO7_Lastabw_Heiz "Lastabwurf-Heizsysteme
Lastabwurf der Hochleistungsheizsysteme (z.B. Abschaltung von Frontscheibenheizung, PTC-Heizung und Heckscheibenheizung nach Motorstart und im Notfall). Anmerkung: Der Lastabwurf der Hochleistungs-heizsysteme wird auch bei reduzierter Generator-spannung durchgeführt (siehe Byte 7 Bit 1,0).(nicht VW D1/Colorado, außer V6 TDI, nicht PQ35/46)";
CM_ SG_ 1416 MO7_GenLdResp "Generator_Load_Response_Motor
Dient der Vermeidung der vom Generator erzeugten, mechanischen Lastsprüngen und Leerlauf-schwankungen durch trägere Ausregelung. Diese Massnahme darf nur kurzfristig bzw. als Notlauf wirksam sein (nicht VW D1/Colorado und PQ35/46).";
CM_ SG_ 1416 MO7_SleepInd "Sleep Indication
Die Sleep-Bereitschaft wird nach Klemme 15 aus durch Setzen dieses Bits signalisiertNMHigh-Teilnehmer der PQ35/46 müssen das Signal nach Kl.-15 aus weiterhin bedienen oder dauerhaft auf 1 = Sleep bereit setzen!";
CM_ SG_ 1416 MO7_Zus_Kuehl "Zusätzliche Kühlung
Zur Unterstützung der Motorkühlung fordert Motor von Klima oder Zusatzheizung die Schaltung des Heizwasserkreislauf-Bypasses an (z. Zt. nur im Colorado V10 TDI)";
CM_ SG_ 1416 MO7_Mot_weckfaehig "Motor weckfähig über CAN
Anhand dieses Signals lernt das BSG, ob es zukünftig bei bestimmten Ereignissen (Türkontakt, Anforderung Standheizung) über das Gateway das Wecken des Antriebs-CANs initieren soll. (nicht Audi)";
CM_ SG_ 1416 MO7_Ladedruckneu "Ladedruck
Zur Anzeige im Kombi (z.Zt. nur Porsche Colorado, PQ35 Bi-Turbo, Audi RS6)Kombi im PQ35-Bi-Turbo und Audi RS6 interpretiert die normierten CAN-Werte (0-254) als 0-100% der Anzeigeskala(Änderung Wertebereich für PQ35/46 mit V5.1.6 und Neuprojekte ohne Empfänger)";
CM_ SG_ 1408 MFN_Offset_Nachf "Ölwarnschwellen-Offset
Byte 1 Bit 0 = 1 und Bit 1 = 0, d.h. bei Zählerstand 1,5,9,13 Wiederholrate 4 sec    Offset für Nachfüllerkennung";
CM_ SG_ 1408 MFN_Ansaugsys "Ansaugsystem
Byte 1 Bit 0 = 0, d.h. bei Zählerstand 0,2,4,6,8,10,12,14 Wiederholrate 2 sec  Ansaugsystem";
CM_ SG_ 1408 MFN_Tol_Oelwarn "Ölwarnschwellen-Toleranz
Byte 1 Bit 0 = 1 und Bit 1 = 0, d.h. bei Zählerstand 1,5,9,13 Wiederholrate 4 sec    Toleranz für Ölwarnschwelle bei geringer Restlaufstrecke ";
CM_ SG_ 1408 MFN_AnzMitOel "Anzahl Mittelung schneller Ölstands-Mittelwert
Byte 1 Bit 0 = 1 und Bit 1 = 0, d.h. bei Zählerstand 1,5,9,13 Wiederholrate 4 sec  Geforderte Anzahl Ölstandsdifferenzen für die Auswertung des schnellen Ölfüllstandsmittelwertes (nur für WIV 3.1 im Audi C6)";
CM_ SG_ 1408 MFN_max_Moment "Max_Drehmoment
Byte 1 Bit 0 = 0, d.h. bei Zählerstand 0,2,4,6,8,10,12,14 Wiederholrate 2 sec  Maximales Drehmoment";
CM_ SG_ 1408 MFN_Motorleistung "Motorleistung
Byte 1 Bit 0 = 0, d.h. bei Zählerstand 0,2,4,6,8,10,12,14 Wiederholrate 2 sec  maximale Motorleistung (Byte 6 + MSB in Byte 7 Bit 0)";
CM_ SG_ 1408 MFN_Drz_max_Mo "Drehzahl_MaxMom
Byte 1 Bit 0 = 0, d.h. bei Zählerstand 0,2,4,6,8,10,12,14 Wiederholrate 2 sec  Drehzahl für maximales Moment";
CM_ SG_ 1408 MFN_Hubraum "Hubraum
Byte 1 Bit 0 = 0, d.h. bei Zählerstand 0,2,4,6,8,10,12,14 Wiederholrate 2 sec  Hubraum";
CM_ SG_ 1408 MFN_Max_Offset "Maximum-Offset
Byte 1 Bit 0 = 1 und Bit 1 = 0, d.h. bei Zählerstand 1,5,9,13 Wiederholrate 4 sec  Offset auf den Maximum-Ölstand, ab dem Überfüllung erkannt werden soll (nur für WIV 3.1 im Audi C6)";
CM_ SG_ 1408 MFN_KurzzeitMW "Kurzzeitmittelwert
Byte 1 Bit 0 = 1 und Bit 1 = 0, d.h. bei Zählerstand 1,5,9,13 Wiederholrate 4 sec   gemittelte Ölstandsdifferenz (Differenz aus aktuellen Füllstandswerte und kompensierter Ölniveauschwelle) bezogen auf Ölwarnschwelle";
CM_ SG_ 1408 MFN_Russindex "Rußäquivalent
Byte 1 Bit 0 = 0, d.h. bei Zählerstand 0,2,4,6,8,10,12,14 Wiederholrate 2 sec  Ist beim Dieselmotor ein von Motordrehzahl und der Einspritzmenge abhängiger Rußwert, beim Ottomotor ist der Wert 00000H    Motor ausFFFFH .. unplausibler/fehlerhafter Wert";
CM_ SG_ 1408 MFN_NormedTrip "Normed Trip
gesetzlich definierte 'Normed Condition' erfüllt; 'General Denominator' darf erhöht werden";
CM_ SG_ 1408 MFN_Oelstand "Ölstandszähler
Byte 1 Bit 0 = 1 und Bit 1 = 0, d.h. bei Zählerstand 1,5,9,13 Wiederholrate 4 sec   Anzahl der in die gemittelte Ölstandsdifferenz eingeflossenen Differenzen";
CM_ SG_ 1408 MFN_Zylinder "Anzahl Zylinder
Byte 1 Bit 0 = 0, d.h. bei Zählerstand 0,2,4,6,8,10,12,14 Wiederholrate 2 sec  Anzahl der Zylinder (1xWert bis 12 Zyl.,13 = 15 Zyl., 14 = 16 Zyl., 15 = 18 Zyl.)";
CM_ SG_ 1408 MFN_Zaehler "Zähler (Motor_Flexia)
überlaufender Botschaftszähler, die Bits 0 und 1 werden zum Multiplexen der Bytes 2..8 benutzt(Hinweis: Im dbc-File nur wg. Nutzung als Multiplexor auf zwei Signale aufgetrennt, Bit 3..0 ist aber als ein Signal (Zähler) umzusetzen)";
CM_ SG_ 1408 MFN_Verbrenn_Typ "Verbrennungsart
Unterscheidung otto oder dieselspezifische Größen";
CM_ SG_ 1408 MFN_Warmup_Cycle "Warm up Cycle
Mit dem WarmUp Cycle wird der Verlernzähler im Gateway inkrementiert";
CM_ SG_ 1408 MFN_Verschl "Verschleiß- bzw. Verbrauchsäquivalent
Byte 1 Bit 0 = 1, d.h. bei Zählerstand 1,3,5,7,9,11,13,15 Wiederholrate 2 sec  Ist beim Dieselmotor ein von der Motordrehzahl und der Öltemperatur abhängiger Verschleißwert, beim  Ottomotor ein Verbrauchsäquivalent , das von der Öltemperatur, dem Füllstand und dem Verbrauch abhängt0000H    Motor ausFFFFH . unplausibler/fehlerhafter Wert";
CM_ SG_ 1408 MFN_Ventile "Anzahl Ventile
Byte 1 Bit 0 = 0, d.h. bei Zählerstand 0,2,4,6,8,10,12,14 Wiederholrate 2 sec  Anzahl der Ventile pro Zylinder";
CM_ SG_ 1408 MFN_Drive_Cycle "Driving Cycle
 ";
CM_ SG_ 1408 MFN_Anz_Mittel "Anzahl Mittelung / Anzahl Mittelung genauer Ölstandsmittelwert
Byte 1 Bit 0 = 1 und Bit 1 = 1, d.h. bei Zählerstand 3,7,11,15 Wiederholrate 4 sec   Minimale geforderte Anzahl der Ölstandsdifferenzen für Auswertung";
CM_ SG_ 1408 MFN_Oelwarnung "Ölwarnung
Byte 1 Bit 0 = 1 und Bit 1 = 0, d.h. bei Zählerstand 1,5,9,13 Wiederholrate 4 sec   aktive Warnmöglichkeit vom Motor (Vorhalt)";
CM_ SG_ 1408 MFN_Interv_tmax "Intervall tmax
Byte 1 Bit 0 = 1 und Bit 1 = 1, d.h. bei Zählerstand 3,7,11,15 Wiederholrate 4 sec   Maximales Zeitintervall bis zum Service";
CM_ SG_ 1408 MFN_Interv_Wmax "Intervall Wmax
Byte 1 Bit 0 = 1 und Bit 1 = 1, d.h. bei Zählerstand 3,7,11,15 Wiederholrate 4 sec   Maximale Kilometeranzahl bis zum Service";
CM_ SG_ 1408 MFN_Sensorwarn "Sensorwarnung
Byte 1 Bit 0 = 1 und Bit 1 = 0, d.h. bei Zählerstand 1,5,9,13 Wiederholrate 4 sec   Sensorwarnung bei unplausiblen oder fehlendem Signal";
CM_ SG_ 1408 MFN_MaxOelst "Schwellwert für Maximum-Ölstand
Byte 1 Bit 0 = 1 und Bit 1 = 1, d.h. bei Zählerstand 3,7,11,15 Wiederholrate 4 sec   Schwellwert für Maximum-Ölstand (entspricht der oberen Markierung am Peilstab) (nur für WIV 3.1 im Audi C6)";
CM_ SG_ 1408 MFN_Interv_Wmin "Intervall Wmin
Byte 1 Bit 0 = 1 und Bit 1 = 1, d.h. bei Zählerstand 3,7,11,15 Wiederholrate 4 sec   Minimale Kilometeranzahl bis zum Service";
CM_ SG_ 1408 MFN_Drz_max_Mo_ "Drehzahl_MaxMom
Byte 1 Bit 0 = 0, d.h. bei Zählerstand 0,2,4,6,8,10,12,14 Wiederholrate 2 sec  Drehzahl für maximales Moment";
CM_ SG_ 1408 MFN_Interv_tmin "Intervall tmin
Byte 1 Bit 0 = 1 und Bit 1 = 1, d.h. bei Zählerstand 3,7,11,15 Wiederholrate 4 sec   Minimales Zeitintervall bis zum Service";
CM_ SG_ 1408 MFN_Str_Mittel "Strecke Mittelung
Byte 1 Bit 0 = 1 und Bit 1 = 1, d.h. bei Zählerstand 3,7,11,15 Wiederholrate 4 sec   Minimal geforderte Fahrstrecke für Ölstandsauswertung";
CM_ SG_ 1408 MFN_Fuell_Erk "Überfüllungserkennung aktiv
Überfüllungserkennung aktiviert nur für WIV 3.1 im Audi C6";
CM_ SG_ 1408 MFN_Hubraum_ "Hubraum
Byte 1 Bit 0 = 0, d.h. bei Zählerstand 0,2,4,6,8,10,12,14 Wiederholrate 2 sec  Hubraum";
CM_ SG_ 1408 MFN_Ansaugsys_ "Ansaugsystem
Byte 1 Bit 0 = 0, d.h. bei Zählerstand 0,2,4,6,8,10,12,14 Wiederholrate 2 sec  Ansaugsystem";
CM_ SG_ 1408 MFN_max_Moment_ "Max_Drehmoment
Byte 1 Bit 0 = 0, d.h. bei Zählerstand 0,2,4,6,8,10,12,14 Wiederholrate 2 sec  Maximales Drehmoment";
CM_ SG_ 1408 MFN_Motorleistung_ "Motorleistung
Byte 1 Bit 0 = 0, d.h. bei Zählerstand 0,2,4,6,8,10,12,14 Wiederholrate 2 sec  maximale Motorleistung (Byte 6 + MSB in Byte 7 Bit 0)";
CM_ SG_ 1408 MFN_Zylinder_ "Anzahl Zylinder
Byte 1 Bit 0 = 0, d.h. bei Zählerstand 0,2,4,6,8,10,12,14 Wiederholrate 2 sec  Anzahl der Zylinder (1xWert bis 12 Zyl.,13 = 15 Zyl., 14 = 16 Zyl., 15 = 18 Zyl.)";
CM_ SG_ 1408 MFN_Ventile_ "Anzahl Ventile
Byte 1 Bit 0 = 0, d.h. bei Zählerstand 0,2,4,6,8,10,12,14 Wiederholrate 2 sec  Anzahl der Ventile pro Zylinder";
CM_ SG_ 1408 MFN_Russindex_ "Rußäquivalent
Byte 1 Bit 0 = 0, d.h. bei Zählerstand 0,2,4,6,8,10,12,14 Wiederholrate 2 sec  Ist beim Dieselmotor ein von Motordrehzahl und der Einspritzmenge abhängiger Rußwert, beim Ottomotor ist der Wert 00000H    Motor ausFFFFH .. unplausibler/fehlerhafter Wert";
CM_ SG_ 1408 MFN_Fuell_Hyst "Überfüllungsschwellen-Hysterese
Byte 1 Bit 0 = 1 und Bit 1 = 0, d.h. bei Zählerstand 1,5,9,13 Wiederholrate 4 sec  Nach erfolgter Überfüllungserkennung muß der nachfolgende Ölstand-Kurzzeitmittelwert  diese Hysterese unterschreiten, damit das Überfüllungsbit zurückgesetzt wird (nur für WIV 3.1 im Audi C6)";
CM_ SG_ 1408 MFN_Zaehler_ "Zähler (Motor_Flexia)
überlaufender Botschaftszähler, die Bits 0 und 1 werden zum Multiplexen der Bytes 2..8 benutzt(Hinweis: Im dbc-File nur wg. Nutzung als Multiplexor auf zwei Signale aufgetrennt, Bit 3..0 ist aber als ein Signal (Zähler) umzusetzen)";
CM_ SG_ 1408 MFN_Verschl_ "Verschleiß- bzw. Verbrauchsäquivalent
Byte 1 Bit 0 = 1, d.h. bei Zählerstand 1,3,5,7,9,11,13,15 Wiederholrate 2 sec  Ist beim Dieselmotor ein von der Motordrehzahl und der Öltemperatur abhängiger Verschleißwert, beim  Ottomotor ein Verbrauchsäquivalent , das von der Öltemperatur, dem Füllstand und dem Verbrauch abhängt0000H    Motor ausFFFFH . unplausibler/fehlerhafter Wert";
CM_ SG_ 1160 MO6_Hoeheninfo "Höheninfo (Motor 6)
Korrekturfaktor Höhe (1 entspricht 1013 mbar)";
CM_ SG_ 1160 MO6_SollM_Getr "Sollmoment für Getriebe
Sollmoment ohne P und D Anteil des Leerlaufreglers, ohne Antiruckelfunktion und ohne Getriebeeingriff(nicht PL71-Hybrid)";
CM_ SG_ 1160 MO6_Checksum "Checksumme (Motor 6)
Prüfsumme, Definition im CAN-Lastenheft";
CM_ SG_ 1160 MO6_GRA_Soll "GRA Sollbeschleunigung
Die im Motor-SG integrierte GRA gibt hier eine 'gesteuerte' Soll-Beschleunigung ausFEH = GRA ausFFH = nicht erlaubt";
CM_ SG_ 1160 MO6_MomIntGeEing "Rückmeldung Momentenintegral Getriebeeingriff
Nur für Getriebe mit 'alter' Momentenschnittstelle:100 %  entspricht volle Verfügbarkeit aktuell vorhanden.0 % entspricht Integral bis Limit gefüllt, erhöhender Eingriff kann aktuell nicht berücksichtigt werden oder erhöhender Eingriff ist in diesem Projekt nicht möglich (applikativ deaktiviert) oder aufgrund eines Fehlers nicht verfügbar.Hybrid:Überwachungsfunktion (E-Gassicherheit) muß um E-Maschinenanteile erweitert werden. Getriebe soll nur eine Tasse Die";
CM_ SG_ 1160 MO6_Freigabe_GRA "GRA-Bremseingriff-Freigabe
Sollbeschleunigung bzw. Bremseeingriff in Byte 5 freigegeben (zukünftig Entfall geplant)";
CM_ SG_ 1160 MO6_Schutz_Toel "Öltemperaturschutz / Übertemperaturschutz
Bei einer Töl > 150°C wird das Übertemperaturschutzbit dann gesetzt und das Getriebe schaltet vom 4. Gang in den 5. Gang bei Vmax. Bei einer Töl < 125°C wird dieses Bit zurück gesetzt und das Getriebe schaltet dann bei Vmax vom 5. Gang wieder in den 4. Gang zurück. (nur D2GP mit 2 MSG-Konzept)Bei einer Überschreitung der Kühlmitteltemperaturschwelle wird das Übertemperaturschutz-Bit als Hochschaltaufforderung an das Getriebe gesetzt(neu im D1/Colorado und PQ35/46)";
CM_ SG_ 1160 MO6_Ist_Moment "Istmoment für Getriebe
Istmoment ohne P und D Anteil des Leerlaufreglers, ohne Antiruckelfunktion und ohne GetriebeeingriffHybrid:EM-Momente müssen berücksichtigt werden. Soll bei kleiner Dynamik und Abwesenheit langfristiger Eingriffe identisch sein zu innerem Moment oE (Motor 1).Unterschiede existieren je nach Motorstand, ob langfristige Eingriffe enthalten sind";
CM_ SG_ 1160 MO6_RegPartikel "Getriebeeingriff Partikelfilterregeneration
Für die Partikelfilterregeneration wird das Getriebe aufgefordert, ein drehzahlintensiveres Schaltprogramm zu aktivieren (Nur EDC16C Audi D3 / Audi C6!) / VW D1/Colorado/ PQ35/46)(Z. Zt.: Mindestdrehzahl im Getriebe appliziert;Zuk. geplant: Übertragung der Mindestdrehzahl in Motor 3, Byte 7)";
CM_ SG_ 1160 MO6_Luftpfad_akt "Luftpfad aktiv
Getriebeeingriff wird zusätzlich zum Zündungspfad auch über den Luftpfad umgesetzt (nur VW D1)";
CM_ SG_ 1160 MO6_FF_Mux00 "Calculated Load Value (PID $04)
Übertragung von Meßgrößen an das Getriebesteuergerät für Freeze Frame Abspeicherung bei Getriebefehlern (nur NAR)";
CM_ SG_ 1160 MO6_FF_Mux01 "Absolute Throttle Position (PID $11)
Übertragung von Meßgrößen an das Getriebesteuergerät für Freeze Frame Abspeicherung bei Getriebefehlern (nur NAR)";
CM_ SG_ 1160 MO6_FF_Mux02 "Engine Coolant Temperature (PID $05)
Übertragung von Meßgrößen an das Getriebesteuergerät für Freeze Frame Abspeicherung bei Getriebefehlern (nur NAR)";
CM_ SG_ 1160 MO6_FF_Mux03 "Absolute Load Value (PID $43)
Übertragung von Meßgrößen an das Getriebesteuergerät für Freeze Frame Abspeicherung bei Getriebefehlern (nur NAR)";
CM_ SG_ 1160 MO6_Zaehler "Botschaftszähler (Motor 6)
Botschaftszähler zur Erkennung fehlender und veraltetet Botschaften, Definition im CAN-Lastenheft";
CM_ SG_ 1160 MO6_FF_Mux05 " 
Übertragung von Meßgrößen an das Getriebesteuergerät für Freeze Frame Abspeicherung bei Getriebefehlern (nur NAR)";
CM_ SG_ 1160 MO6_FF_Mux06 " 
Übertragung von Meßgrößen an das Getriebesteuergerät für Freeze Frame Abspeicherung bei Getriebefehlern (nur NAR)";
CM_ SG_ 1160 MO6_FF_Mux04 "Accelerator Pedal Position D (PID $49)
Übertragung von Meßgrößen an das Getriebesteuergerät für Freeze Frame Abspeicherung bei Getriebefehlern (nur NAR)";
CM_ SG_ 1160 MO6_FF_Mux08 " 
Übertragung von Meßgrößen an das Getriebesteuergerät für Freeze Frame Abspeicherung bei Getriebefehlern (nur NAR)";
CM_ SG_ 1160 MO6_FF_Mux07 " 
Übertragung von Meßgrößen an das Getriebesteuergerät für Freeze Frame Abspeicherung bei Getriebefehlern (nur NAR)";
CM_ SG_ 1160 MO6_FF_Mux09 " 
Übertragung von Meßgrößen an das Getriebesteuergerät für Freeze Frame Abspeicherung bei Getriebefehlern (nur NAR)";
CM_ SG_ 1160 MO6_FF_Mux10 " 
Übertragung von Meßgrößen an das Getriebesteuergerät für Freeze Frame Abspeicherung bei Getriebefehlern (nur NAR)";
CM_ SG_ 1160 MO6_FF_Mux11 " 
Übertragung von Meßgrößen an das Getriebesteuergerät für Freeze Frame Abspeicherung bei Getriebefehlern (nur NAR)";
CM_ SG_ 1160 MO6_FF_Mux12 " 
Übertragung von Meßgrößen an das Getriebesteuergerät für Freeze Frame Abspeicherung bei Getriebefehlern (nur NAR)";
CM_ SG_ 1160 MO6_FF_Mux14 " 
Übertragung von Meßgrößen an das Getriebesteuergerät für Freeze Frame Abspeicherung bei Getriebefehlern (nur NAR)";
CM_ SG_ 1160 MO6_FF_Mux13 " 
Übertragung von Meßgrößen an das Getriebesteuergerät für Freeze Frame Abspeicherung bei Getriebefehlern (nur NAR)";
CM_ SG_ 1160 MO6_FF_Mux15 " 
Übertragung von Meßgrößen an das Getriebesteuergerät für Freeze Frame Abspeicherung bei Getriebefehlern (nur NAR)";
CM_ SG_ 1152 MO5_max_Moment "Motor Multiplex-Info (maximales Drehmoment)
Maximales Drehmoment (Code 00)";
CM_ SG_ 1152 MO5_res_08 " 
(war Generator-Ladekontroll-Lampe)";
CM_ SG_ 1152 MO5_Mp_Code "Motor Multiplex-Code
Motor Multiplex-Code und Multiplex-Info sind verkettet; der Multiplex-Code wird nach 4 Übertragungen weitergeschaltet; dieser Mechanismus wiederholt sich somit nach 4 x 4 = 16 Umlaufzeiten";
CM_ SG_ 1152 MO5_Vorgluehen "Vorglühlampe (Motor 5)
Diesel-Vorglühlampe und Diesel-Systemlampe";
CM_ SG_ 1152 MO5_E_Gas "E-Gas-Lampe
E-Gas Systemlampe (z.Zt. nur Otto-Motoren)";
CM_ SG_ 1152 MO5_OBD_2 "OBD2 Lampe
OBD bzw MIL Lampe wird vom Motorsteuergerät angesteuert, die Information in der Getriebe 1 Botschaft (Byte 6, Bit 7..4) wird vom Motorsteuergerät an das Kombi weitergereicht";
CM_ SG_ 1152 MO5_KliKo_Red "Klimakompressor Leistungsreduzierung
Klimakompressor-Leistungsreduzierung (im PQ35/46 z. Zt. nicht genutzt)";
CM_ SG_ 1152 MO5_Heissl "Heißleuchte
Ansteuerung der Kühlwassertemperatur-Heißleuchte (Sensor nur noch am Motorsteuergerät): Temperatur-Schaltschwellen mit Hysterese (bei VW D1/Colorado Kombi derzeit noch nicht genutzt)";
CM_ SG_ 1152 MO5_KlimaKompr "Klimakompressor aus (Motor 5)
Motor-Steuergerät schaltet Klimakompressor aus";
CM_ SG_ 1152 MO5_Feld_kuehl "Kennfeldkühlung
Die Kennfeldkühlung ist in diesem Fahrzeug verbaut und hat keinen Systemfehler";
CM_ SG_ 1152 MO5_Verbrauch "Kraftstoff-Verbrauchssignal
Low Byte 3; High Byte 4; Motor-Steuergerät interner Verbrauchszähler, der vom Kombi zyklisch ausgelesen wird, um die Einspritzmenge zur Verbrauchsberechnung aufzusummieren; aus diesem Zählerstand werden Momentan- und Durchschnitts-verbrauch berechnet; das Überlauf-Bit (Byte 4, Bit 7) ist zu berücksichtigenHinweis Erdgas-Projekt: Bei Erdgasbetrieb wird die Gas-Verbrauchsmenge in Einheit mg ausgegeben.";
CM_ SG_ 1152 MO5_UeberlVerb "Verbrauch-Überlauf
Der Motor-Steuergerät interne Verbrauchszähler ist mindestens einmal übergelaufen. Dieses Bit wird genutzt, um erkennen zu können, das das Motorsteuergerät aus dem Reset-Zustand hochläuft";
CM_ SG_ 1152 MO5_Momente "Doppelte Momente
Normwert MDI wird verdoppelt";
CM_ SG_ 1152 MO5_Luefter "Kühlerlüfteransteuerung (Motor 5)
Istzustand der Kühlerlüfteransteuerung über die PWM Schnittstelle; Lüfterstufen (z.B. 14) werden in Prozente umgerechnet; Werte > 100% sind unzulässig (Mittelwert bei zwei Lüftern)";
CM_ SG_ 1152 MO5_Checksumme "Checksumme (Motor 5)
Prüfsumme, Definition im CAN-Lastenheft";
CM_ SG_ 1152 MO5_Start "Anlasser Freigabe
Bit wird gesetzt, wenn der Motor beim Automatikstart (nur im VW D1/Colorado Otto; nicht bei sonstigen Audi) gestartet werden darf (Motorstillstand, Emissionsmaßnahmen sind erfüllt,..)";
CM_ SG_ 1152 MO5_HLeuchte "Heißleuchtenvorwarnung
Klimaanlage mußte aufgrund einer Übertemperaturerkennung abgeschaltet werden (Schwelle entspricht der Heißleuchtenvorwarnschwelle)";
CM_ SG_ 1152 MO5_Anlasser "Anlasser Ausspuren
Bit wird gesetzt, wenn der Motorhochlauf ohne Anlasserunterstützung beendet werden kann oder ein Start-Time Out erreicht wurde (nur im VW D1/Colorado Otto und PQ35/46; nicht bei sonstigen Audi)";
CM_ SG_ 1152 MO5_Motortext1 "Motortext 1
Text 1: Motorstrg Werkstatt";
CM_ SG_ 1152 MO5_GRA_Hauptsch "GRA-Hauptschalter/ GRA-Bereitschaft
z.Zt. bei VW (nicht bei Audi): Schalter gerastet ein (bei Taster der Ausgang des Status Flipflops)Porsche: Anforderungen GRA-Bereitschafts-Lampe an/aus";
CM_ SG_ 1152 MO5_Interlock "Interlock-Schalter
Interlockschalter muß beim Handschalter betätigt sein, damit ein Motorstart erlaubt ist (z.Zt. bei Audi-Handschalter mit Automatikstart und VW mit Automatikstart)Bei Stufenautomaten (Audi) wird pauschal der Initwert gesendet.Bei Stufenautomaten (VW) wird Bit abhängig von PN gesetzt.";
CM_ SG_ 1152 MO5_Motortyp "Motor Multiplex-Info (Motortyp)
Tabelle der Motortypen (Code 10)Bit 3...0: Zweizylinder 2 Dreizylinder 3 Vierzylinder 4 Fuenfzylinder 5 Sechszylinder 6 Achtzylinder 8 Zehnzylnder 10 Zwoelfzylinder 12 Fuenfzehnzylinder 13 Sechzehnzylinder 14 Achtzehnzylinder 15Bit 4: Turbo_Motor 0 Saug_Motor 1Bit 5: Otto_Motor 0 Diesel_Motor 1";
CM_ SG_ 1152 MO5_Sta_BKU "Fehlerstatus Bremskraftunterstützungspumpe
Der Defekt der elektrischen Pumpe zur Verbesserung der Unterdruckversorgung wird angezeigt (nur Porsche Colorado)";
CM_ SG_ 1152 MO5_Drehzahl "Motor Multiplex-Info (Drehzahl bei max. Drehmoment)
Drehzahl bei maximalem Drehmoment (Code 01)";
CM_ SG_ 1152 MO5_TypStartSteu "Typ Startersteuerung
Automatikstart wird gesetzt, wenn das Motorsteuergerät den  Motorstart automatisch steuert";
CM_ SG_ 1152 MO5_PartikelLamp "Partikelfilter Lampe
Partikelfilter-Lampe wird eingeschaltet";
CM_ SG_ 1152 MO5_Motortext4 "Motortext 4
Text 4: Partikelfilter benötigt Regeneration";
CM_ SG_ 1152 MO5_TDE_Text "Motortext-Bit Tankdeckelwarnung
Anzeige im Kombiinstrument, dass Tankdeckel offen sein könnte (nur Ottomotoren)";
CM_ SG_ 1152 MO5_Motortext3 "Motortext 3
Text 3: Fehler im Kraftstoffsystem";
CM_ SG_ 1152 MO5_Motortext2 "Motortext 2
Text 2: Abgas Werkstatt (wg. Gesetzesbestimmungen nicht mehr verwenden)";
CM_ SG_ 1152 MO5_Abgastyp2 "Motor Multiplex-Info (Abgastyp)
Tabelle Abgastyp (Code 11)(Info: war normierter Verbrauch teilw. noch im PQ25, T5GP)";
CM_ SG_ 1152 MO5_TDE_Lampe "Lampe Tankdeckelwarnung
Ansteuerung Tankdeckel-Warnlampe Kombiinstrument (nur Ottomotoren)";
CM_ SG_ 1152 MO5_Abgastyp "Motor Multiplex-Info (Abgastyp)
Tabelle Abgastyp (Code 11)(Info: war normierter Verbrauch teilw. noch im PQ25, T5GP)";
CM_ SG_ 1152 MO5_DZM_Daempf "Drehzahlmesserdämpfung
Dämpfungskonstanten des Drehzahlmessers im Kombi können umgeschaltet werden";
CM_ SG_ 1152 MO5_Abgastyp3 "Motor Multiplex-Info (Abgastyp)
Tabelle Abgastyp (Code 11)(Info: war normierter Verbrauch teilw. noch im PQ25, T5GP)";
CM_ SG_ 1152 MO5_DPF_reg "Motor Multiplex-Info (Abgastyp)
Tabelle Abgastyp (Code 11)(Info: war normierter Verbrauch teilw. noch im PQ25, T5GP)";
CM_ SG_ 640 MO1_Leergas "Leergasinformation
Fahrpedal-Leergasschalter, Leergasinfo aus Fahrpedalwert oder Leerlaufschalter bei Drosselklappe (wird zur Freigabe der MSR-Funktion im ABS verwendet)";
CM_ SG_ 640 MO1_TiOut_Br "Time Out Bremsen-Botschaft
500 msec Time Out auf Bremsen-Botschaft ist >= 1 mal aufgelaufen, Löschen des Bits nach Neustart (Kl.15)";
CM_ SG_ 640 MO1_Sta_Bremse "Fehlerstatus Brems-Momenteneingriff
Eingriffswunsch (ASR oder MSR) vom Bremsen-Steuergerät (ABS) kann nicht ausgeführt werden, weil im Motorsteuergerät ein statischer Fehler vorliegt oder die Funktion durch die Applikation abgeschaltet ist";
CM_ SG_ 640 MO1_Kickdown "Kickdownschalter
0 kann für nicht verbaut stehen, bei Doppelanalogpedalwertgeber ggfs. errechneter Wert";
CM_ SG_ 640 MO1_Sta_Pedal "Fahrpedalwert ungenau (Motor 1)
Ersatzwert aus Modellrechnung oder Fehlerwert in Byte 6, Leergas- oder Kickdown-Info können betroffen sein";
CM_ SG_ 640 MO1_Kup_schalt "Kupplungsschalter
nur Handschalter; aktiv, wenn Schalter verbaut; sonst konstant auf 0 gesetzt; Bit wird gesetzt, wenn Kupplungspedal nicht betätigt wird (Kupplungsschalter hoch), Triebstrang kann noch eingekuppelt sein";
CM_ SG_ 640 MO1_Sta_Getr "Fehlerstatus Getriebe-Momenteneingriff
Eingriffswunsch vom Getriebe-Steuergerät kann ggfs. nicht oder nicht vollständig ausgeführt werden, weil entweder im Motorsteuergerät ein statischer (!) Fehler vorliegt oder die Momentenanforderung des Getriebe-Steuergerätes aus Sicht des Motorsteuergerätes nicht erfüllt werden darf (z. B. Leerlaufregler fordert höheres Moment) (im Colorado) (im PQ35/46 für alle Getriebe)";
CM_ SG_ 640 MO1_Pedalwert "Fahrpedalwert oder Drosselklappenpoti
Bei E-Gas wird hier der Fahrpedalwert ausgegeben; Maximum aus Rohsignal, gefiltertem Wert (TDI) und virtuellem Wert aus Kennfeld (bei aktiver integrierter GRA), Wert wird bei Doppelpotis auch bei einer defekten Poti-Spur ausgegeben, genutzter Wertebereich 0..100%Bei aktivem Winterfahrprogramm wird das Signal nach unten Korrigiert und entspricht dann nicht mehr dem physikalischen Wert.";
CM_ SG_ 640 MO1_Sta_MotMo "Momentenangaben ungenau
ungenaue Momentenangaben, weil die Momente aus Ersatzwerten berechnet wurden (z.B. HFM ausgefallen)";
CM_ SG_ 640 MO1_Mo_m_ex "inneres Motor-Moment
indiziertes Motormoment, d.h. idealisiertes berechnetes Moment ohne mechanische Verluste, aber mit externen EingriffenHybrid:Es sind drei Fälle zu unterscheiden:1. offene K0: von positiven EM-Momenten (egal ob Eingriffs- oder Fahrmoment) werden negative EM-Eingriffsmomente abgezogen.2. schlupfende K0: von positiven EM-Momenten (egal ob Eingriffs- oder Fahrmoment) werden negative EM-Eingriffsmomente abgezogen; zusätzlich wird, falls das Vorzeichen der DZ-Differenz von VM und EM posit";
CM_ SG_ 640 MO1_Verlustmo "mechanisches Motor-Verlustmoment
beinhaltet z. Zt Reibung vom Motor und Klimakompressor, beim TDI z.T. auch die GeneratorverlusteHybrid (Signal Summe negative Momente):negative Fahr-EM-Momente (Rekuperationsanteil) sowie ein negativer Momentenbeitrag durch negativ schlupfende K0 (s.o.) werden hier addiert.Diese Zeile ändert sich bei Momenteneingriffen nicht, so dass sie gleichermaßen für die Berechnung von mE- und oE - Kurbelwellenmomenten nutzbar ist.";
CM_ SG_ 640 MO1_Mo_o_ex "inneres Motor-Moment ohne externe Eingriffe
indiziertes Motormoment ohne externe Eingriffe (ASR, MSR, Getriebe,..), aber inklusive integrierter GRAHybrid:Es sind drei Fälle zu unterscheiden:1. offene K0: positive EM-Momente (nur Fahrmomente)2. schlupfende K0: zu positiven EM-Momenten (nur Fahrmomente) wird, falls das Vorzeichen der DZ-Differenz von VM und EM positiv ist, die momentane Kapazität der K0 addiert.3. geschlossene K0: Zum indizierten VM-Moment oE wird ein positives EM-Moment (nur Fahrmoment) ad";
CM_ SG_ 640 MO1_Drehzahl "Motordrehzahl
Low Byte 3, High Byte 4; es wird der letzte aktuelle Meßwert gesendet, d.h. die Zeit für das letzte Arbeitsspiel (180 Grad KW beim 4 Zylinder) wird herangezogen; der Fehlerwert wird gesendet, wenn das Motor-steuergerät keine plausible Drehzahlinformation hat, aber trotzdem noch funktionsfähig ist. 0xFF in Byte 4: FehlerHybrid (Signal E-Motordrehzahl):E-Maschinendrehzahl, Verwendung als Antriebs-DZ in GSG.";
CM_ SG_ 640 MO1_Wunschmo "Fahrerwunschmoment
Moment vor Filter, nutzbar zur Zug- / Schuberkennung beim Getriebe (beim Diesel identisch mit innerem Moment, ohne externe Eingriffe)Hybrid:Moment vor Filter inkl. K0-Beitrag bei negativ schlupfender K0.Zur Verwendung in Schaltstrategie: Fahrerwunsch sollte nicht durch zB Rauchkennfeld (Diesel) o.Ä. begrenzt werden.";
CM_ SG_ 1154 MH1_VM_Mom_oE "Verbrenner-Moment ohne Eingriff
Verbrenner-Fahrmoment abzüglich Verbrenner-Verlustmoment. Vorzeichenbehaftet.Für Benutzung in Getriebe-Schaltstrategie";
CM_ SG_ 1154 MH1_IstStatusK0 "Ist-Status K0
Status 'offen' muss eine voll geöffnete Kupplung sicherstellen.";
CM_ SG_ 1154 MH1_Startmodus_PQ35 "Startmodus Impuls / Direkt PQ35
Hybridsteuerung (MSG) zeigt an, auf welche Weise gestartet werden soll (nur PQ35 Hybrid)";
CM_ SG_ 1154 MH1_VM_aktiv "Verbrennungsmotor aktiv
0 = VMotor wird nicht aktiv gehalten (nVM < n_min und keine LL-Regelung aktiv)1 = VMotor aktiv (ab der ersten Einspritzung; gilt auch für Schubbetrieb, wenn VMotor spätestens durch LL-Regelung befeuert würde)Verwendung zur Bestimmung des Ist-Zustandes";
CM_ SG_ 1154 MH1_Zielzustand_Hybrid "Zielzustand Hybrid
Ziel - Hybrid-Betriebszustände";
CM_ SG_ 1154 MH1_VerlParam_Msum "Selektor Momentenverlauf EM
Wenn Byte 7, Bit 4 = 1 (GRA/ACC aktiv), erhalten in Abhängigkeit von den Bits 1, 0 (Byte 3) die Bits 7..2 (Byte 3) folgende Bedeutung:Bit 1,0 =00: max. umsetzbares langfr. Rekup-MomentBit 1,0 =01: Knickdrehzahl d. langfr. Rekup-KurveBit 1,0 =10: max. verfügbares langfr. pos. EM-MomentBit 1,0 =11: Knickdrehzahl d. langfristigen pos. EM-Kurve";
CM_ SG_ 1154 MH1_E_Faktor "E-Faktor
Wenn Byte 7, Bit 4 = 0 (GRA/ACC nicht aktiv): E-Faktor.Signed Nibble (Zweierkomplement),verwendet vom GSG zur Interpolation zwischen VM-Kennfeld und dem Rekuperations-Grenzkennfeld (negative Werte des E-Faktors) bzw. dem Boost-Grenzkennfeld(positive Werte des E-Faktors).0000 = VM-Kennfeld (keine Interpolation)0001..0111 = dez +1..+7 Interpolation zwischen VM-Kennfeld und Boost-Kennfeld1000..1111 = dez -8..-1 Interpolation zwischen VM-Kennfeld und Rekup.-Kennfeld";
CM_ SG_ 1154 MH1_Drehzahl_VM "Drehzahl Verbrennungsmotor
für OBD freeze frame";
CM_ SG_ 1154 MH1_Schaltverh "Schaltverhinderung
Schaltungen werden an den DZ-Grenzen (Nullgas-Schaltdrehzahl und Kickdown-Schaltdrehzahl) ausgeführt";
CM_ SG_ 1154 MH1_max_ind_VM_Mom "Max. mögliches indiziertes VM-Moment
inneres maximal mögliches VM-Moment bei einer Drehzahl (z. B. Rauchbegrenzung oder Fehlerfall).Verwendet von GSG bei GRA/ACC-Betrieb";
CM_ SG_ 1154 MH1_Startmodus_PL71 "Startmodus PL71
Hybridsteuerung (MSG) zeigt an, auf welche Weise gestartet werden soll. (nur PL71 Hybrid)";
CM_ SG_ 1154 MH1_ACCGRA_aktiv "GRA/ACC aktiv
Zeigt an, ob GRA/ACC aktiv ist.Wird zusammen mit Byte 3 / Bits 1..0 als Selektor für die Bedeutung der Bits 7..2 (Byte 3) benutzt";
CM_ SG_ 1154 MH1_LowSpeedModus "Low-Speed-Modus
MSG legt fest:0 = klassisches Ausrollen/Anfahren mit N_mot >= N_Leerlauf_VM1 = elektr. Ausrollen/Anfahren mit geschl. Triebstrang mit N_mot < N_Leerlauf_VM";
CM_ SG_ 1154 MH1_Bremspedalwert "Bremspedalwert
Bremspedalwegsensor vom Motor eingelesen (Vorhalt für ACC nur im Q7)";
CM_ SG_ 1154 MH1_QB_Bremspedalwert "Qualifizierungsbit Bremspedalwert
Qualifizierungsbit nach CAN-LH";
CM_ SG_ 1154 MH1_res_52 " 
Reservebits: Vorhalt für Status schneller Eingriff EM und Soft-Stop vs Dynamik-Stop";
CM_ SG_ 1154 MH1_MomVerlauf_EM "Momentenverlauf EM
Wenn Byte 7, Bit 4 = 1 (GRA/ACC aktiv):MomentenverlaufsinformationUmrechnung:M = 315/63 * i Nm (i = unsigned int der 6 Bits), wenn Byte 3, Bit 1,0 = 0 oder 2N = 3150/63 * i min-1 (i = unsigned int der 6 Bits) , wenn Byte 3, Bit 1,0 = 1 oder 3";
CM_ SG_ 1657 BAP_Data_HYB " 
 ";
CM_ SG_ 1657 BAP_var_HYB " 
 ";
CM_ SG_ 2024 ISO_MO_01_Resp_Data "ISO Response Kanal
 ";
CM_ SG_ 644 MOB_Bremsstgr "Anforderung Bremsstellgröße
Byte 3 LSB, Byte 4(2..0) MSB ; Angeforderte (normierte) radbremsmomenten-proportionale Stellgröße (im PQ46)";
CM_ SG_ 644 MOB_Checksum "Checksumme (Motor_Bremse)
Prüfsumme, Definition im CAN Lastenheft";
CM_ SG_ 644 MOB_Bremsmom "Anforderung Summenradbremsmoment
13 Bit, in Byte 4 stehen die niederwertigsten 5 Bit, in Byte 5 die höherwertigen BitsAlternativ zu Bremsdruckanforderung. Ältere Systeme hören nur auf Bremsdruck, neue Systeme auf Radbremsmoment (im Touareg GP, D1GP, Golf GP, T5GP)";
CM_ SG_ 644 MOB_Anhaltewunsch "Anhaltewunsch
Erweiterung für ACC Follow to Stop";
CM_ SG_ 644 MOB_res_15 " 
 ";
CM_ SG_ 644 MOB_res_40 " 
 ";
CM_ SG_ 644 MOB_Zaehler "Zähler (Motor_Bremse)
Freilaufender Botschaftszähler gem. CAN-Lastenheft";
CM_ SG_ 644 MOB_Freigabe "Freigabe Bremsanforderung
Anforderung Bremsstellgröße (Byte 4,3) bzw. Summenradbremsmoment (Byte 5,4) wird freigegeben (Vorhalt)Bremslicht wird angesteuert";
CM_ SG_ 644 MOB_Standby "Standby
Veranlaßt Bremsbooster / die Bremse den Leerweg zu überfahren, bevor Bremsdruck erzeugt wird.";
CM_ SG_ 1162 MO8_LampeDZBegr "Lampe Drehzahlbegrenzung
Im Audi RS/4 und AU714";
CM_ SG_ 1162 MO8_Zaehler "Botschaftszähler
Definition nach CAN-Lastenheft";
CM_ SG_ 1162 MO8_Checksumme "Checksumme
Definition nach CAN-Lastenheft";
CM_ SG_ 1162 MO8_res_20 " 
 ";
CM_ SG_ 1162 MO8_Spoiler_ausf "Spoiler ausfahren
Spoiler ausfahren";
CM_ SG_ 1162 MO8_AnzeigeDZ "Optimierte Anzeigedrehzahl
 ";
CM_ SG_ 1162 MO8_SGT_Soundakt "Stellgliedtest Soundaktuator
Ansteuerung des Stellgliedtest Soundaktuator (AU716, TTNF)";
CM_ SG_ 1162 MO8_Enable_Oeldr_Motor "Enable_Oeldr_Motor
Schaltet die interne Öldruckauswertung im Kombiinstrument ab und aktiviert die Auswertung des Bits ´Oeldr_Warn_Motor´ (Audi C6, D3, AU716, AU350, TTNF, AU714, Touareg GP)";
CM_ SG_ 1162 MO8_Sportschalter "Sportschalter
nur AU714";
CM_ SG_ 1162 MO8_res_30 " 
 ";
CM_ SG_ 1162 MO8_Oeldr_Warn_Motor "Oeldr_Warn_Motor
Löst im Kombiinstrument die rote Prio1-Öldruckwarnung (inkl. 3xBeep) aus; die Warnauslösung erfolgt nur bei gleichzeitig gesetztem ´Enable_Oeldr_Motor´ (Audi C6, D3, AU716, AU350, TTNF, AU714, Touareg GP)";
CM_ SG_ 1162 MO8_res_29 " 
 ";
CM_ SG_ 1162 MO8_GRA_v_Wunsch "GRA Wunschgeschwindigkeit
Wunschgeschwindigkeit GRA vom Motor an Kombi zur Anzeige im Mitteldisplay (nicht AU714)";
CM_ SG_ 1162 MO8_Avus_Motorschutz "Avus_Motorschutz
Warntexte zum Kombi für den Fall des Avus-Notlauf. Priowarnung, kann parallel mit anderen Warnungen im Mitteldisplay angezeigt werden. (Audi C6, D3, AU716, AU350, TTNF, AU714, Touareg GP)";
CM_ SG_ 1162 MO8_Nachlauf_ZWP "Nachlauf Zusatzwasserpumpe
Die Zusatzwasserpumpe soll bei Kl. 15 aus (Nachlauf) die erhöhte Temperatur im Motorraum bei Bedarf noch abführen können. (nur Audi)";
CM_ SG_ 1162 MO8_res_41 " 
 ";
CM_ SG_ 1162 MO8_res_31 " 
 ";
CM_ SG_ 1162 MO8_res_48 " 
reserviert für Öldruckanzeige Lamborghini";
CM_ SG_ 1162 MO8_res_56 " 
 ";
CM_ SG_ 1162 MO8_res_58 " 
 ";
CM_ SG_ 1162 MO8_res_57 " 
 ";
CM_ SG_ 1162 MO8_res_59 " 
 ";
BA_DEF_ BO_  "VAGTP20_API" HEX 0 255;
BA_DEF_ BO_  "VAGTP20_StatConnection" ENUM  "No","Yes";
BA_DEF_ BO_  "VAGTP20_DynConnection" ENUM  "No","Yes";
BA_DEF_ BO_  "VAGTP20_DynSetup" ENUM  "No","Yes";
BA_DEF_ BO_  "NmMessage" ENUM  "No","Yes";
BA_DEF_ BO_  "NmhMessage" ENUM  "No","Yes";
BA_DEF_ BO_  "GenMsgCycleTime" INT 0 65535;
BA_DEF_ BO_  "GenMsgSendType" ENUM  "cyclicX","spontanX","cyclicIfActiveX","spontanWithDelay","cyclicAndSpontanX","cyclicAndSpontanWithDelay","spontanWithRepitition","cyclicIfActiveAndSpontanWD","NoMsgSendType","cyclicWithRepeatOnDemand";
BA_DEF_ BO_  "GenMsgCycleTimeFast" INT 0 65535;
BA_DEF_ BO_  "GenMsgNrOfRepetition" INT 0 255;
BA_DEF_ BO_  "GenMsgDelayTime" INT 0 100000;
BA_DEF_ BO_  "GenMsgILSupport" ENUM  "No","Yes";
BA_DEF_ BO_  "GenMsgTimeoutTime" INT 0 100000;
BA_DEF_ BO_  "GenMsgAutoGenDsp" ENUM  "No","Yes";
BA_DEF_ BO_  "GenMsgAutoGenSnd" ENUM  "No","Yes";
BA_DEF_ BO_  "DiagRequest" ENUM  "No","Yes";
BA_DEF_ BO_  "DiagResponse" ENUM  "No","Yes";
BA_DEF_ BO_  "DiagState" ENUM  "No","Yes";
BA_DEF_ SG_  "GenSigSendType" ENUM  "Cyclic","OnWrite","OnWriteWithRepetition","OnChange","OnChangeWithRepetition","IfActive","IfActiveWithRepetition","NoSigSendType";
BA_DEF_ SG_  "GenSigStartValue" INT 0 4294967295;
BA_DEF_ SG_  "GenSigInactiveValue" INT 0 2147483647;
BA_DEF_ SG_  "GenSigAutoGenDsp" ENUM  "No","Yes";
BA_DEF_ SG_  "GenSigAutoGenSnd" ENUM  "No","Yes";
BA_DEF_ SG_  "GenSigEnvVarType" STRING ;
BA_DEF_ SG_  "GenSigFuncType" ENUM  "NoFunction","MsgCounter","CRC-8","XOR","XOR-2","DatedBit","SW-Kl15","CHK","Constant","Protokoll";
BA_DEF_ SG_  "NWM-WakeUpAllowed" ENUM  "No","Yes";
BA_DEF_ SG_  "INIT" STRING ;
BA_DEF_ SG_  "GenSigTimeoutMsg_Airbag" HEX 0 2047;
BA_DEF_ SG_  "GenSigTimeoutTime_Airbag" INT 0 65535;
BA_DEF_ SG_  "GenSigTimeoutMsg_Allrad" HEX 0 2047;
BA_DEF_ SG_  "GenSigTimeoutTime_Allrad" INT 0 65535;
BA_DEF_ SG_  "GenSigTimeoutMsg_Lenkhilfe_ZF_2" HEX 0 2047;
BA_DEF_ SG_  "GenSigTimeoutTime_Lenkhilfe_ZF_2" INT 0 65535;
BA_DEF_ SG_  "GenSigTimeoutMsg_Teves_MK60_ESP" HEX 0 2047;
BA_DEF_ SG_  "GenSigTimeoutTime_Teves_MK60_ESP" INT 0 65535;
BA_DEF_ SG_  "GenSigTimeoutMsg_LWS" HEX 0 2047;
BA_DEF_ SG_  "GenSigTimeoutTime_LWS" INT 0 65535;
BA_DEF_ SG_  "GenSigTimeoutMsg_LWR" HEX 0 2047;
BA_DEF_ SG_  "GenSigTimeoutTime_LWR" INT 0 65535;
BA_DEF_ SG_  "GenSigTimeoutMsg_Teves_MK70_MAB" HEX 0 2047;
BA_DEF_ SG_  "GenSigTimeoutTime_Teves_MK70_MAB" INT 0 65535;
BA_DEF_ SG_  "GenSigTimeoutMsg_Waehlhebel" HEX 0 2047;
BA_DEF_ SG_  "GenSigTimeoutTime_Waehlhebel" INT 0 65535;
BA_DEF_ SG_  "GenSigTimeoutMsg_EPB" HEX 0 2047;
BA_DEF_ SG_  "GenSigTimeoutTime_EPB" INT 0 65535;
BA_DEF_ SG_  "GenSigTimeoutMsg_TRW_ESP" HEX 0 2047;
BA_DEF_ SG_  "GenSigTimeoutTime_TRW_ESP" INT 0 65535;
BA_DEF_ SG_  "GenSigTimeoutMsg_ACC_Radar" HEX 0 2047;
BA_DEF_ SG_  "GenSigTimeoutTime_ACC_Radar" INT 0 65535;
BA_DEF_ SG_  "GenSigTimeoutMsg_AFS" HEX 0 2047;
BA_DEF_ SG_  "GenSigTimeoutTime_AFS" INT 0 65535;
BA_DEF_ SG_  "GenSigTimeoutMsg_Magne_Ride" HEX 0 2047;
BA_DEF_ SG_  "GenSigTimeoutTime_Magne_Ride" INT 0 65535;
BA_DEF_ SG_  "GenSigTimeoutMsg_RKA_Plus" HEX 0 2047;
BA_DEF_ SG_  "GenSigTimeoutTime_RKA_Plus" INT 0 65535;
BA_DEF_ SG_  "GenSigTimeoutMsg_Selespeed" HEX 0 2047;
BA_DEF_ SG_  "GenSigTimeoutTime_Selespeed" INT 0 65535;
BA_DEF_ SG_  "GenSigTimeoutMsg_Waehlhebel_Sel" HEX 0 2047;
BA_DEF_ SG_  "GenSigTimeoutTime_Waehlhebel_Sel" INT 0 65535;
BA_DEF_ SG_  "GenSigTimeoutMsg_PDC_PLA" HEX 0 2047;
BA_DEF_ SG_  "GenSigTimeoutTime_PDC_PLA" INT 0 65535;
BA_DEF_ SG_  "GenSigTimeoutMsg_Lenkhilfe_APA" HEX 0 2047;
BA_DEF_ SG_  "GenSigTimeoutTime_Lenkhilfe_APA" INT 0 65535;
BA_DEF_ SG_  "GenSigTimeoutMsg_VAQ" HEX 0 2047;
BA_DEF_ SG_  "GenSigTimeoutTime_VAQ" INT 0 65535;
BA_DEF_ SG_  "GenSigTimeoutMsg_Daempfer" HEX 0 2047;
BA_DEF_ SG_  "GenSigTimeoutTime_Daempfer" INT 0 65535;
BA_DEF_ SG_  "GenSigTimeoutMsg_Hybrid_BMS" HEX 0 2047;
BA_DEF_ SG_  "GenSigTimeoutTime_Hybrid_BMS" INT 0 65535;
BA_DEF_ SG_  "GenSigTimeoutMsg_Hybrid_PWR" HEX 0 2047;
BA_DEF_ SG_  "GenSigTimeoutTime_Hybrid_PWR" INT 0 65535;
BA_DEF_ SG_  "GenSigTimeoutMsg_Hybrid_DQ200" HEX 0 2047;
BA_DEF_ SG_  "GenSigTimeoutTime_Hybrid_DQ200" INT 0 65535;
BA_DEF_ SG_  "GenSigTimeoutMsg_EKlimakomp" HEX 0 2047;
BA_DEF_ SG_  "GenSigTimeoutTime_EKlimakomp" INT 0 65535;
BA_DEF_ SG_  "GenSigTimeoutMsg_SWA" HEX 0 2047;
BA_DEF_ SG_  "GenSigTimeoutTime_SWA" INT 0 65535;
BA_DEF_ SG_  "GenSigTimeoutMsg_HCA" HEX 0 2047;
BA_DEF_ SG_  "GenSigTimeoutTime_HCA" INT 0 65535;
BA_DEF_ SG_  "GenSigTimeoutMsg_ACC_Lidar" HEX 0 2047;
BA_DEF_ SG_  "GenSigTimeoutTime_ACC_Lidar" INT 0 65535;
BA_DEF_ SG_  "GenSigTimeoutMsg_Lenkhilfe_ZF_3" HEX 0 2047;
BA_DEF_ SG_  "GenSigTimeoutTime_Lenkhilfe_ZF_3" INT 0 65535;
BA_DEF_ SG_  "GenSigTimeoutMsg_FLA" HEX 0 2047;
BA_DEF_ SG_  "GenSigTimeoutTime_FLA" INT 0 65535;
BA_DEF_ SG_  "GenSigTimeoutMsg_AG6" HEX 0 2047;
BA_DEF_ SG_  "GenSigTimeoutTime_AG6" INT 0 65535;
BA_DEF_ SG_  "GenSigTimeoutMsg_DQ" HEX 0 2047;
BA_DEF_ SG_  "GenSigTimeoutTime_DQ" INT 0 65535;
BA_DEF_ SG_  "GenSigTimeoutMsg_Hybrid_MSG" HEX 0 2047;
BA_DEF_ SG_  "GenSigTimeoutTime_Hybrid_MSG" INT 0 65535;
BA_DEF_ SG_  "GenSigTimeoutMsg_Diesel" HEX 0 2047;
BA_DEF_ SG_  "GenSigTimeoutTime_Diesel" INT 0 65535;
BA_DEF_ SG_  "GenSigTimeoutMsg_Otto" HEX 0 2047;
BA_DEF_ SG_  "GenSigTimeoutTime_Otto" INT 0 65535;
BA_DEF_ SG_  "GenSigTimeoutMsg_Gateway_PQ35_A" HEX 0 2047;
BA_DEF_ SG_  "GenSigTimeoutTime_Gateway_PQ35_A" INT 0 65535;
BA_DEF_ SG_  "GenSigTimeoutMsg_Gateway_PQ46_A" HEX 0 2047;
BA_DEF_ SG_  "GenSigTimeoutTime_Gateway_PQ46_A" INT 0 65535;
BA_DEF_DEF_  "VAGTP20_API" 0;
BA_DEF_DEF_  "VAGTP20_StatConnection" "No";
BA_DEF_DEF_  "VAGTP20_DynConnection" "No";
BA_DEF_DEF_  "VAGTP20_DynSetup" "No";
BA_DEF_DEF_  "NmMessage" "No";
BA_DEF_DEF_  "NmhMessage" "No";
BA_DEF_DEF_  "GenMsgCycleTime" 0;
BA_DEF_DEF_  "GenMsgSendType" "NoMsgSendType";
BA_DEF_DEF_  "GenMsgCycleTimeFast" 0;
BA_DEF_DEF_  "GenMsgNrOfRepetition" 0;
BA_DEF_DEF_  "GenMsgDelayTime" 0;
BA_DEF_DEF_  "GenMsgILSupport" "No";
BA_DEF_DEF_  "GenMsgTimeoutTime" 0;
BA_DEF_DEF_  "GenMsgAutoGenDsp" "Yes";
BA_DEF_DEF_  "GenMsgAutoGenSnd" "Yes";
BA_DEF_DEF_  "DiagRequest" "No";
BA_DEF_DEF_  "DiagResponse" "No";
BA_DEF_DEF_  "DiagState" "No";
BA_DEF_DEF_  "GenSigSendType" "NoSigSendType";
BA_DEF_DEF_  "GenSigStartValue" 0;
BA_DEF_DEF_  "GenSigInactiveValue" 0;
BA_DEF_DEF_  "GenSigAutoGenDsp" "Yes";
BA_DEF_DEF_  "GenSigAutoGenSnd" "Yes";
BA_DEF_DEF_  "GenSigEnvVarType" "Undef";
BA_DEF_DEF_  "GenSigFuncType" "NoFunction";
BA_DEF_DEF_  "NWM-WakeUpAllowed" "No";
BA_DEF_DEF_  "INIT" "";
BA_DEF_DEF_  "GenSigTimeoutMsg_Airbag" 0;
BA_DEF_DEF_  "GenSigTimeoutTime_Airbag" 0;
BA_DEF_DEF_  "GenSigTimeoutMsg_Allrad" 0;
BA_DEF_DEF_  "GenSigTimeoutTime_Allrad" 0;
BA_DEF_DEF_  "GenSigTimeoutMsg_Lenkhilfe_ZF_2" 0;
BA_DEF_DEF_  "GenSigTimeoutTime_Lenkhilfe_ZF_2" 0;
BA_DEF_DEF_  "GenSigTimeoutMsg_Teves_MK60_ESP" 0;
BA_DEF_DEF_  "GenSigTimeoutTime_Teves_MK60_ESP" 0;
BA_DEF_DEF_  "GenSigTimeoutMsg_LWS" 0;
BA_DEF_DEF_  "GenSigTimeoutTime_LWS" 0;
BA_DEF_DEF_  "GenSigTimeoutMsg_LWR" 0;
BA_DEF_DEF_  "GenSigTimeoutTime_LWR" 0;
BA_DEF_DEF_  "GenSigTimeoutMsg_Teves_MK70_MAB" 0;
BA_DEF_DEF_  "GenSigTimeoutTime_Teves_MK70_MAB" 0;
BA_DEF_DEF_  "GenSigTimeoutMsg_Waehlhebel" 0;
BA_DEF_DEF_  "GenSigTimeoutTime_Waehlhebel" 0;
BA_DEF_DEF_  "GenSigTimeoutMsg_EPB" 0;
BA_DEF_DEF_  "GenSigTimeoutTime_EPB" 0;
BA_DEF_DEF_  "GenSigTimeoutMsg_TRW_ESP" 0;
BA_DEF_DEF_  "GenSigTimeoutTime_TRW_ESP" 0;
BA_DEF_DEF_  "GenSigTimeoutMsg_ACC_Radar" 0;
BA_DEF_DEF_  "GenSigTimeoutTime_ACC_Radar" 0;
BA_DEF_DEF_  "GenSigTimeoutMsg_AFS" 0;
BA_DEF_DEF_  "GenSigTimeoutTime_AFS" 0;
BA_DEF_DEF_  "GenSigTimeoutMsg_Magne_Ride" 0;
BA_DEF_DEF_  "GenSigTimeoutTime_Magne_Ride" 0;
BA_DEF_DEF_  "GenSigTimeoutMsg_RKA_Plus" 0;
BA_DEF_DEF_  "GenSigTimeoutTime_RKA_Plus" 0;
BA_DEF_DEF_  "GenSigTimeoutMsg_Selespeed" 0;
BA_DEF_DEF_  "GenSigTimeoutTime_Selespeed" 0;
BA_DEF_DEF_  "GenSigTimeoutMsg_Waehlhebel_Sel" 0;
BA_DEF_DEF_  "GenSigTimeoutTime_Waehlhebel_Sel" 0;
BA_DEF_DEF_  "GenSigTimeoutMsg_PDC_PLA" 0;
BA_DEF_DEF_  "GenSigTimeoutTime_PDC_PLA" 0;
BA_DEF_DEF_  "GenSigTimeoutMsg_Lenkhilfe_APA" 0;
BA_DEF_DEF_  "GenSigTimeoutTime_Lenkhilfe_APA" 0;
BA_DEF_DEF_  "GenSigTimeoutMsg_VAQ" 0;
BA_DEF_DEF_  "GenSigTimeoutTime_VAQ" 0;
BA_DEF_DEF_  "GenSigTimeoutMsg_Daempfer" 0;
BA_DEF_DEF_  "GenSigTimeoutTime_Daempfer" 0;
BA_DEF_DEF_  "GenSigTimeoutMsg_Hybrid_BMS" 0;
BA_DEF_DEF_  "GenSigTimeoutTime_Hybrid_BMS" 0;
BA_DEF_DEF_  "GenSigTimeoutMsg_Hybrid_PWR" 0;
BA_DEF_DEF_  "GenSigTimeoutTime_Hybrid_PWR" 0;
BA_DEF_DEF_  "GenSigTimeoutMsg_Hybrid_DQ200" 0;
BA_DEF_DEF_  "GenSigTimeoutTime_Hybrid_DQ200" 0;
BA_DEF_DEF_  "GenSigTimeoutMsg_EKlimakomp" 0;
BA_DEF_DEF_  "GenSigTimeoutTime_EKlimakomp" 0;
BA_DEF_DEF_  "GenSigTimeoutMsg_SWA" 0;
BA_DEF_DEF_  "GenSigTimeoutTime_SWA" 0;
BA_DEF_DEF_  "GenSigTimeoutMsg_HCA" 0;
BA_DEF_DEF_  "GenSigTimeoutTime_HCA" 0;
BA_DEF_DEF_  "GenSigTimeoutMsg_ACC_Lidar" 0;
BA_DEF_DEF_  "GenSigTimeoutTime_ACC_Lidar" 0;
BA_DEF_DEF_  "GenSigTimeoutMsg_Lenkhilfe_ZF_3" 0;
BA_DEF_DEF_  "GenSigTimeoutTime_Lenkhilfe_ZF_3" 0;
BA_DEF_DEF_  "GenSigTimeoutMsg_FLA" 0;
BA_DEF_DEF_  "GenSigTimeoutTime_FLA" 0;
BA_DEF_DEF_  "GenSigTimeoutMsg_AG6" 0;
BA_DEF_DEF_  "GenSigTimeoutTime_AG6" 0;
BA_DEF_DEF_  "GenSigTimeoutMsg_DQ" 0;
BA_DEF_DEF_  "GenSigTimeoutTime_DQ" 0;
BA_DEF_DEF_  "GenSigTimeoutMsg_Hybrid_MSG" 0;
BA_DEF_DEF_  "GenSigTimeoutTime_Hybrid_MSG" 0;
BA_DEF_DEF_  "GenSigTimeoutMsg_Diesel" 0;
BA_DEF_DEF_  "GenSigTimeoutTime_Diesel" 0;
BA_DEF_DEF_  "GenSigTimeoutMsg_Otto" 0;
BA_DEF_DEF_  "GenSigTimeoutTime_Otto" 0;
BA_DEF_DEF_  "GenSigTimeoutMsg_Gateway_PQ35_A" 0;
BA_DEF_DEF_  "GenSigTimeoutTime_Gateway_PQ35_A" 0;
BA_DEF_DEF_  "GenSigTimeoutMsg_Gateway_PQ46_A" 0;
BA_DEF_DEF_  "GenSigTimeoutTime_Gateway_PQ46_A" 0;
BA_ "GenMsgTimeoutTime" BO_ 648 500;
BA_ "GenMsgSendType" BO_ 648 0;
BA_ "GenMsgCycleTime" BO_ 648 20;
BA_ "GenMsgTimeoutTime" BO_ 1416 500;
BA_ "GenMsgSendType" BO_ 1416 0;
BA_ "GenMsgCycleTime" BO_ 1416 20;
BA_ "GenMsgTimeoutTime" BO_ 1408 5000;
BA_ "GenMsgSendType" BO_ 1408 0;
BA_ "GenMsgCycleTime" BO_ 1408 1000;
BA_ "GenMsgTimeoutTime" BO_ 1160 500;
BA_ "GenMsgSendType" BO_ 1160 0;
BA_ "GenMsgCycleTime" BO_ 1160 10;
BA_ "GenMsgTimeoutTime" BO_ 1152 500;
BA_ "GenMsgSendType" BO_ 1152 0;
BA_ "GenMsgCycleTime" BO_ 1152 20;
BA_ "GenMsgTimeoutTime" BO_ 640 500;
BA_ "GenMsgSendType" BO_ 640 0;
BA_ "GenMsgCycleTime" BO_ 640 10;
BA_ "GenMsgTimeoutTime" BO_ 1154 500;
BA_ "GenMsgSendType" BO_ 1154 0;
BA_ "GenMsgCycleTime" BO_ 1154 10;
BA_ "GenMsgSendType" BO_ 1657 1;
BA_ "DiagResponse" BO_ 2024 1;
BA_ "GenMsgSendType" BO_ 2024 1;
BA_ "GenMsgTimeoutTime" BO_ 644 500;
BA_ "GenMsgSendType" BO_ 644 0;
BA_ "GenMsgCycleTime" BO_ 644 20;
BA_ "GenMsgTimeoutTime" BO_ 1162 500;
BA_ "GenMsgSendType" BO_ 1162 0;
BA_ "GenMsgCycleTime" BO_ 1162 20;
BA_ "GenSigTimeoutTime_ACC_Lidar" SG_ 648 MO2_CAN_Vers 500;
BA_ "GenSigTimeoutMsg_ACC_Lidar" SG_ 648 MO2_CAN_Vers 648;
BA_ "GenSigTimeoutTime_Selespeed" SG_ 648 MO2_CAN_Vers 500;
BA_ "GenSigTimeoutMsg_Selespeed" SG_ 648 MO2_CAN_Vers 648;
BA_ "GenSigTimeoutTime_Hybrid_DQ200" SG_ 648 MO2_CAN_Vers 500;
BA_ "GenSigTimeoutMsg_Hybrid_DQ200" SG_ 648 MO2_CAN_Vers 648;
BA_ "GenSigTimeoutTime_Gateway_PQ35_A" SG_ 648 MO2_CAN_Vers 500;
BA_ "GenSigTimeoutMsg_Gateway_PQ35_A" SG_ 648 MO2_CAN_Vers 648;
BA_ "GenSigTimeoutTime_ACC_Radar" SG_ 648 MO2_CAN_Vers 500;
BA_ "GenSigTimeoutMsg_ACC_Radar" SG_ 648 MO2_CAN_Vers 648;
BA_ "GenSigTimeoutTime_TRW_ESP" SG_ 648 MO2_CAN_Vers 500;
BA_ "GenSigTimeoutMsg_TRW_ESP" SG_ 648 MO2_CAN_Vers 648;
BA_ "GenSigTimeoutTime_DQ" SG_ 648 MO2_CAN_Vers 500;
BA_ "GenSigTimeoutMsg_DQ" SG_ 648 MO2_CAN_Vers 648;
BA_ "GenSigTimeoutTime_Gateway_PQ46_A" SG_ 648 MO2_CAN_Vers 500;
BA_ "GenSigTimeoutMsg_Gateway_PQ46_A" SG_ 648 MO2_CAN_Vers 648;
BA_ "GenSigTimeoutTime_AG6" SG_ 648 MO2_CAN_Vers 500;
BA_ "GenSigTimeoutMsg_AG6" SG_ 648 MO2_CAN_Vers 648;
BA_ "GenSigSendType" SG_ 648 MO2_CAN_Vers 0;
BA_ "INIT" SG_ 648 MO2_CAN_Vers "const";
BA_ "GenSigTimeoutTime_ACC_Lidar" SG_ 648 MO2_Mp_Code 500;
BA_ "GenSigTimeoutMsg_ACC_Lidar" SG_ 648 MO2_Mp_Code 648;
BA_ "GenSigTimeoutTime_EPB" SG_ 648 MO2_Mp_Code 500;
BA_ "GenSigTimeoutMsg_EPB" SG_ 648 MO2_Mp_Code 648;
BA_ "GenSigTimeoutTime_Selespeed" SG_ 648 MO2_Mp_Code 500;
BA_ "GenSigTimeoutMsg_Selespeed" SG_ 648 MO2_Mp_Code 648;
BA_ "GenSigTimeoutTime_Hybrid_DQ200" SG_ 648 MO2_Mp_Code 500;
BA_ "GenSigTimeoutMsg_Hybrid_DQ200" SG_ 648 MO2_Mp_Code 648;
BA_ "GenSigTimeoutTime_RKA_Plus" SG_ 648 MO2_Mp_Code 500;
BA_ "GenSigTimeoutMsg_RKA_Plus" SG_ 648 MO2_Mp_Code 648;
BA_ "GenSigTimeoutTime_Gateway_PQ35_A" SG_ 648 MO2_Mp_Code 500;
BA_ "GenSigTimeoutMsg_Gateway_PQ35_A" SG_ 648 MO2_Mp_Code 648;
BA_ "GenSigTimeoutTime_ACC_Radar" SG_ 648 MO2_Mp_Code 500;
BA_ "GenSigTimeoutMsg_ACC_Radar" SG_ 648 MO2_Mp_Code 648;
BA_ "GenSigTimeoutTime_TRW_ESP" SG_ 648 MO2_Mp_Code 500;
BA_ "GenSigTimeoutMsg_TRW_ESP" SG_ 648 MO2_Mp_Code 648;
BA_ "GenSigTimeoutTime_DQ" SG_ 648 MO2_Mp_Code 500;
BA_ "GenSigTimeoutMsg_DQ" SG_ 648 MO2_Mp_Code 648;
BA_ "GenSigTimeoutTime_Teves_MK70_MAB" SG_ 648 MO2_Mp_Code 500;
BA_ "GenSigTimeoutMsg_Teves_MK70_MAB" SG_ 648 MO2_Mp_Code 648;
BA_ "GenSigTimeoutTime_Teves_MK60_ESP" SG_ 648 MO2_Mp_Code 500;
BA_ "GenSigTimeoutMsg_Teves_MK60_ESP" SG_ 648 MO2_Mp_Code 648;
BA_ "GenSigTimeoutTime_Allrad" SG_ 648 MO2_Mp_Code 500;
BA_ "GenSigTimeoutMsg_Allrad" SG_ 648 MO2_Mp_Code 648;
BA_ "GenSigTimeoutTime_Gateway_PQ46_A" SG_ 648 MO2_Mp_Code 500;
BA_ "GenSigTimeoutMsg_Gateway_PQ46_A" SG_ 648 MO2_Mp_Code 648;
BA_ "GenSigTimeoutTime_AG6" SG_ 648 MO2_Mp_Code 500;
BA_ "GenSigTimeoutMsg_AG6" SG_ 648 MO2_Mp_Code 648;
BA_ "GenSigSendType" SG_ 648 MO2_Mp_Code 0;
BA_ "GenSigTimeoutTime_Hybrid_PWR" SG_ 648 MO2_Kuehlm_T 500;
BA_ "GenSigTimeoutMsg_Hybrid_PWR" SG_ 648 MO2_Kuehlm_T 648;
BA_ "GenSigTimeoutTime_Selespeed" SG_ 648 MO2_Kuehlm_T 500;
BA_ "GenSigTimeoutMsg_Selespeed" SG_ 648 MO2_Kuehlm_T 648;
BA_ "GenSigTimeoutTime_Hybrid_DQ200" SG_ 648 MO2_Kuehlm_T 500;
BA_ "GenSigTimeoutMsg_Hybrid_DQ200" SG_ 648 MO2_Kuehlm_T 648;
BA_ "GenSigTimeoutTime_RKA_Plus" SG_ 648 MO2_Kuehlm_T 500;
BA_ "GenSigTimeoutMsg_RKA_Plus" SG_ 648 MO2_Kuehlm_T 648;
BA_ "GenSigTimeoutTime_Magne_Ride" SG_ 648 MO2_Kuehlm_T 500;
BA_ "GenSigTimeoutMsg_Magne_Ride" SG_ 648 MO2_Kuehlm_T 648;
BA_ "GenSigTimeoutTime_Gateway_PQ35_A" SG_ 648 MO2_Kuehlm_T 500;
BA_ "GenSigTimeoutMsg_Gateway_PQ35_A" SG_ 648 MO2_Kuehlm_T 648;
BA_ "GenSigTimeoutTime_TRW_ESP" SG_ 648 MO2_Kuehlm_T 500;
BA_ "GenSigTimeoutMsg_TRW_ESP" SG_ 648 MO2_Kuehlm_T 648;
BA_ "GenSigTimeoutTime_DQ" SG_ 648 MO2_Kuehlm_T 500;
BA_ "GenSigTimeoutMsg_DQ" SG_ 648 MO2_Kuehlm_T 648;
BA_ "GenSigTimeoutTime_Gateway_PQ46_A" SG_ 648 MO2_Kuehlm_T 500;
BA_ "GenSigTimeoutMsg_Gateway_PQ46_A" SG_ 648 MO2_Kuehlm_T 648;
BA_ "GenSigTimeoutTime_AG6" SG_ 648 MO2_Kuehlm_T 500;
BA_ "GenSigTimeoutMsg_AG6" SG_ 648 MO2_Kuehlm_T 648;
BA_ "GenSigSendType" SG_ 648 MO2_Kuehlm_T 0;
BA_ "GenSigTimeoutTime_ACC_Lidar" SG_ 648 MO2_BTS 500;
BA_ "GenSigTimeoutMsg_ACC_Lidar" SG_ 648 MO2_BTS 648;
BA_ "GenSigTimeoutTime_Selespeed" SG_ 648 MO2_BTS 500;
BA_ "GenSigTimeoutMsg_Selespeed" SG_ 648 MO2_BTS 648;
BA_ "GenSigTimeoutTime_Hybrid_DQ200" SG_ 648 MO2_BTS 500;
BA_ "GenSigTimeoutMsg_Hybrid_DQ200" SG_ 648 MO2_BTS 648;
BA_ "GenSigTimeoutTime_Magne_Ride" SG_ 648 MO2_BTS 500;
BA_ "GenSigTimeoutMsg_Magne_Ride" SG_ 648 MO2_BTS 648;
BA_ "GenSigTimeoutTime_Gateway_PQ35_A" SG_ 648 MO2_BTS 500;
BA_ "GenSigTimeoutMsg_Gateway_PQ35_A" SG_ 648 MO2_BTS 648;
BA_ "GenSigTimeoutTime_ACC_Radar" SG_ 648 MO2_BTS 500;
BA_ "GenSigTimeoutMsg_ACC_Radar" SG_ 648 MO2_BTS 648;
BA_ "GenSigTimeoutTime_TRW_ESP" SG_ 648 MO2_BTS 500;
BA_ "GenSigTimeoutMsg_TRW_ESP" SG_ 648 MO2_BTS 648;
BA_ "GenSigTimeoutTime_EPB" SG_ 648 MO2_BTS 500;
BA_ "GenSigTimeoutMsg_EPB" SG_ 648 MO2_BTS 648;
BA_ "GenSigTimeoutTime_DQ" SG_ 648 MO2_BTS 500;
BA_ "GenSigTimeoutMsg_DQ" SG_ 648 MO2_BTS 648;
BA_ "GenSigTimeoutTime_Allrad" SG_ 648 MO2_BTS 500;
BA_ "GenSigTimeoutMsg_Allrad" SG_ 648 MO2_BTS 648;
BA_ "GenSigTimeoutTime_Gateway_PQ46_A" SG_ 648 MO2_BTS 500;
BA_ "GenSigTimeoutMsg_Gateway_PQ46_A" SG_ 648 MO2_BTS 648;
BA_ "GenSigTimeoutTime_AG6" SG_ 648 MO2_BTS 500;
BA_ "GenSigTimeoutMsg_AG6" SG_ 648 MO2_BTS 648;
BA_ "GenSigSendType" SG_ 648 MO2_BTS 0;
BA_ "GenSigTimeoutTime_ACC_Lidar" SG_ 648 MO2_BLS 500;
BA_ "GenSigTimeoutMsg_ACC_Lidar" SG_ 648 MO2_BLS 648;
BA_ "GenSigTimeoutTime_Selespeed" SG_ 648 MO2_BLS 500;
BA_ "GenSigTimeoutMsg_Selespeed" SG_ 648 MO2_BLS 648;
BA_ "GenSigTimeoutTime_Hybrid_DQ200" SG_ 648 MO2_BLS 500;
BA_ "GenSigTimeoutMsg_Hybrid_DQ200" SG_ 648 MO2_BLS 648;
BA_ "GenSigTimeoutTime_Daempfer" SG_ 648 MO2_BLS 500;
BA_ "GenSigTimeoutMsg_Daempfer" SG_ 648 MO2_BLS 648;
BA_ "GenSigTimeoutTime_Magne_Ride" SG_ 648 MO2_BLS 500;
BA_ "GenSigTimeoutMsg_Magne_Ride" SG_ 648 MO2_BLS 648;
BA_ "GenSigTimeoutTime_Gateway_PQ35_A" SG_ 648 MO2_BLS 500;
BA_ "GenSigTimeoutMsg_Gateway_PQ35_A" SG_ 648 MO2_BLS 648;
BA_ "GenSigTimeoutTime_ACC_Radar" SG_ 648 MO2_BLS 500;
BA_ "GenSigTimeoutMsg_ACC_Radar" SG_ 648 MO2_BLS 648;
BA_ "GenSigTimeoutTime_TRW_ESP" SG_ 648 MO2_BLS 500;
BA_ "GenSigTimeoutMsg_TRW_ESP" SG_ 648 MO2_BLS 648;
BA_ "GenSigTimeoutTime_EPB" SG_ 648 MO2_BLS 500;
BA_ "GenSigTimeoutMsg_EPB" SG_ 648 MO2_BLS 648;
BA_ "GenSigTimeoutTime_DQ" SG_ 648 MO2_BLS 500;
BA_ "GenSigTimeoutMsg_DQ" SG_ 648 MO2_BLS 648;
BA_ "GenSigTimeoutTime_Allrad" SG_ 648 MO2_BLS 500;
BA_ "GenSigTimeoutMsg_Allrad" SG_ 648 MO2_BLS 648;
BA_ "GenSigTimeoutTime_Gateway_PQ46_A" SG_ 648 MO2_BLS 500;
BA_ "GenSigTimeoutMsg_Gateway_PQ46_A" SG_ 648 MO2_BLS 648;
BA_ "GenSigTimeoutTime_AG6" SG_ 648 MO2_BLS 500;
BA_ "GenSigTimeoutMsg_AG6" SG_ 648 MO2_BLS 648;
BA_ "GenSigSendType" SG_ 648 MO2_BLS 0;
BA_ "GenSigTimeoutTime_Gateway_PQ35_A" SG_ 648 MO2_Sta_No_Bet 500;
BA_ "GenSigTimeoutMsg_Gateway_PQ35_A" SG_ 648 MO2_Sta_No_Bet 648;
BA_ "GenSigTimeoutTime_TRW_ESP" SG_ 648 MO2_Sta_No_Bet 500;
BA_ "GenSigTimeoutMsg_TRW_ESP" SG_ 648 MO2_Sta_No_Bet 648;
BA_ "GenSigTimeoutTime_Teves_MK70_MAB" SG_ 648 MO2_Sta_No_Bet 500;
BA_ "GenSigTimeoutMsg_Teves_MK70_MAB" SG_ 648 MO2_Sta_No_Bet 648;
BA_ "GenSigTimeoutTime_Teves_MK60_ESP" SG_ 648 MO2_Sta_No_Bet 500;
BA_ "GenSigTimeoutMsg_Teves_MK60_ESP" SG_ 648 MO2_Sta_No_Bet 648;
BA_ "GenSigTimeoutTime_Gateway_PQ46_A" SG_ 648 MO2_Sta_No_Bet 500;
BA_ "GenSigTimeoutMsg_Gateway_PQ46_A" SG_ 648 MO2_Sta_No_Bet 648;
BA_ "GenSigSendType" SG_ 648 MO2_Sta_No_Bet 0;
BA_ "GenSigTimeoutTime_Hybrid_DQ200" SG_ 648 MO2_Sta_Klima 500;
BA_ "GenSigTimeoutMsg_Hybrid_DQ200" SG_ 648 MO2_Sta_Klima 648;
BA_ "GenSigTimeoutTime_Gateway_PQ35_A" SG_ 648 MO2_Sta_Klima 500;
BA_ "GenSigTimeoutMsg_Gateway_PQ35_A" SG_ 648 MO2_Sta_Klima 648;
BA_ "GenSigTimeoutTime_TRW_ESP" SG_ 648 MO2_Sta_Klima 500;
BA_ "GenSigTimeoutMsg_TRW_ESP" SG_ 648 MO2_Sta_Klima 648;
BA_ "GenSigTimeoutTime_DQ" SG_ 648 MO2_Sta_Klima 500;
BA_ "GenSigTimeoutMsg_DQ" SG_ 648 MO2_Sta_Klima 648;
BA_ "GenSigTimeoutTime_Gateway_PQ46_A" SG_ 648 MO2_Sta_Klima 500;
BA_ "GenSigTimeoutMsg_Gateway_PQ46_A" SG_ 648 MO2_Sta_Klima 648;
BA_ "GenSigTimeoutTime_AG6" SG_ 648 MO2_Sta_Klima 500;
BA_ "GenSigTimeoutMsg_AG6" SG_ 648 MO2_Sta_Klima 648;
BA_ "GenSigSendType" SG_ 648 MO2_Sta_Klima 0;
BA_ "GenSigTimeoutTime_ACC_Lidar" SG_ 648 MO2_Status_TSK 500;
BA_ "GenSigTimeoutMsg_ACC_Lidar" SG_ 648 MO2_Status_TSK 648;
BA_ "GenSigTimeoutTime_ACC_Radar" SG_ 648 MO2_Status_TSK 500;
BA_ "GenSigTimeoutMsg_ACC_Radar" SG_ 648 MO2_Status_TSK 648;
BA_ "GenSigTimeoutTime_Gateway_PQ35_A" SG_ 648 MO2_Status_TSK 500;
BA_ "GenSigTimeoutMsg_Gateway_PQ35_A" SG_ 648 MO2_Status_TSK 648;
BA_ "GenSigTimeoutTime_TRW_ESP" SG_ 648 MO2_Status_TSK 500;
BA_ "GenSigTimeoutMsg_TRW_ESP" SG_ 648 MO2_Status_TSK 648;
BA_ "GenSigTimeoutTime_Gateway_PQ46_A" SG_ 648 MO2_Status_TSK 500;
BA_ "GenSigTimeoutMsg_Gateway_PQ46_A" SG_ 648 MO2_Status_TSK 648;
BA_ "GenSigSendType" SG_ 648 MO2_Status_TSK 0;
BA_ "GenSigTimeoutTime_ACC_Lidar" SG_ 648 MO2_Sta_GRA 500;
BA_ "GenSigTimeoutMsg_ACC_Lidar" SG_ 648 MO2_Sta_GRA 648;
BA_ "GenSigTimeoutTime_Selespeed" SG_ 648 MO2_Sta_GRA 500;
BA_ "GenSigTimeoutMsg_Selespeed" SG_ 648 MO2_Sta_GRA 648;
BA_ "GenSigTimeoutTime_Hybrid_DQ200" SG_ 648 MO2_Sta_GRA 500;
BA_ "GenSigTimeoutMsg_Hybrid_DQ200" SG_ 648 MO2_Sta_GRA 648;
BA_ "GenSigTimeoutTime_RKA_Plus" SG_ 648 MO2_Sta_GRA 500;
BA_ "GenSigTimeoutMsg_RKA_Plus" SG_ 648 MO2_Sta_GRA 648;
BA_ "GenSigTimeoutTime_Gateway_PQ35_A" SG_ 648 MO2_Sta_GRA 500;
BA_ "GenSigTimeoutMsg_Gateway_PQ35_A" SG_ 648 MO2_Sta_GRA 648;
BA_ "GenSigTimeoutTime_ACC_Radar" SG_ 648 MO2_Sta_GRA 500;
BA_ "GenSigTimeoutMsg_ACC_Radar" SG_ 648 MO2_Sta_GRA 648;
BA_ "GenSigTimeoutTime_TRW_ESP" SG_ 648 MO2_Sta_GRA 500;
BA_ "GenSigTimeoutMsg_TRW_ESP" SG_ 648 MO2_Sta_GRA 648;
BA_ "GenSigTimeoutTime_DQ" SG_ 648 MO2_Sta_GRA 500;
BA_ "GenSigTimeoutMsg_DQ" SG_ 648 MO2_Sta_GRA 648;
BA_ "GenSigTimeoutTime_Gateway_PQ46_A" SG_ 648 MO2_Sta_GRA 500;
BA_ "GenSigTimeoutMsg_Gateway_PQ46_A" SG_ 648 MO2_Sta_GRA 648;
BA_ "GenSigTimeoutTime_AG6" SG_ 648 MO2_Sta_GRA 500;
BA_ "GenSigTimeoutMsg_AG6" SG_ 648 MO2_Sta_GRA 648;
BA_ "GenSigSendType" SG_ 648 MO2_Sta_GRA 0;
BA_ "GenSigTimeoutTime_Hybrid_PWR" SG_ 648 MO2_Sta_Kuehlm 500;
BA_ "GenSigTimeoutMsg_Hybrid_PWR" SG_ 648 MO2_Sta_Kuehlm 648;
BA_ "GenSigTimeoutTime_Hybrid_DQ200" SG_ 648 MO2_Sta_Kuehlm 500;
BA_ "GenSigTimeoutMsg_Hybrid_DQ200" SG_ 648 MO2_Sta_Kuehlm 648;
BA_ "GenSigTimeoutTime_Gateway_PQ35_A" SG_ 648 MO2_Sta_Kuehlm 500;
BA_ "GenSigTimeoutMsg_Gateway_PQ35_A" SG_ 648 MO2_Sta_Kuehlm 648;
BA_ "GenSigTimeoutTime_TRW_ESP" SG_ 648 MO2_Sta_Kuehlm 500;
BA_ "GenSigTimeoutMsg_TRW_ESP" SG_ 648 MO2_Sta_Kuehlm 648;
BA_ "GenSigTimeoutTime_DQ" SG_ 648 MO2_Sta_Kuehlm 500;
BA_ "GenSigTimeoutMsg_DQ" SG_ 648 MO2_Sta_Kuehlm 648;
BA_ "GenSigTimeoutTime_Gateway_PQ46_A" SG_ 648 MO2_Sta_Kuehlm 500;
BA_ "GenSigTimeoutMsg_Gateway_PQ46_A" SG_ 648 MO2_Sta_Kuehlm 648;
BA_ "GenSigTimeoutTime_AG6" SG_ 648 MO2_Sta_Kuehlm 500;
BA_ "GenSigTimeoutMsg_AG6" SG_ 648 MO2_Sta_Kuehlm 648;
BA_ "GenSigSendType" SG_ 648 MO2_Sta_Kuehlm 0;
BA_ "GenSigTimeoutTime_Selespeed" SG_ 648 MO2_LL_Solldz 500;
BA_ "GenSigTimeoutMsg_Selespeed" SG_ 648 MO2_LL_Solldz 648;
BA_ "GenSigTimeoutTime_Hybrid_DQ200" SG_ 648 MO2_LL_Solldz 500;
BA_ "GenSigTimeoutMsg_Hybrid_DQ200" SG_ 648 MO2_LL_Solldz 648;
BA_ "GenSigTimeoutTime_Gateway_PQ35_A" SG_ 648 MO2_LL_Solldz 500;
BA_ "GenSigTimeoutMsg_Gateway_PQ35_A" SG_ 648 MO2_LL_Solldz 648;
BA_ "GenSigTimeoutTime_TRW_ESP" SG_ 648 MO2_LL_Solldz 500;
BA_ "GenSigTimeoutMsg_TRW_ESP" SG_ 648 MO2_LL_Solldz 648;
BA_ "GenSigTimeoutTime_DQ" SG_ 648 MO2_LL_Solldz 500;
BA_ "GenSigTimeoutMsg_DQ" SG_ 648 MO2_LL_Solldz 648;
BA_ "GenSigTimeoutTime_Gateway_PQ46_A" SG_ 648 MO2_LL_Solldz 500;
BA_ "GenSigTimeoutMsg_Gateway_PQ46_A" SG_ 648 MO2_LL_Solldz 648;
BA_ "GenSigTimeoutTime_AG6" SG_ 648 MO2_LL_Solldz 500;
BA_ "GenSigTimeoutMsg_AG6" SG_ 648 MO2_LL_Solldz 648;
BA_ "GenSigSendType" SG_ 648 MO2_LL_Solldz 0;
BA_ "GenSigTimeoutTime_TRW_ESP" SG_ 648 MO2_Sport_Error 500;
BA_ "GenSigTimeoutMsg_TRW_ESP" SG_ 648 MO2_Sport_Error 648;
BA_ "GenSigTimeoutTime_Gateway_PQ35_A" SG_ 648 MO2_Sport_Error 500;
BA_ "GenSigTimeoutMsg_Gateway_PQ35_A" SG_ 648 MO2_Sport_Error 648;
BA_ "GenSigTimeoutTime_Gateway_PQ46_A" SG_ 648 MO2_Sport_Error 500;
BA_ "GenSigTimeoutMsg_Gateway_PQ46_A" SG_ 648 MO2_Sport_Error 648;
BA_ "GenSigSendType" SG_ 648 MO2_Sport_Error 0;
BA_ "GenSigTimeoutTime_Teves_MK70_MAB" SG_ 648 MO2_Motor_Code 500;
BA_ "GenSigTimeoutMsg_Teves_MK70_MAB" SG_ 648 MO2_Motor_Code 648;
BA_ "GenSigTimeoutTime_Teves_MK60_ESP" SG_ 648 MO2_Motor_Code 500;
BA_ "GenSigTimeoutMsg_Teves_MK60_ESP" SG_ 648 MO2_Motor_Code 648;
BA_ "GenSigTimeoutTime_ACC_Lidar" SG_ 648 MO2_Motor_Code 500;
BA_ "GenSigTimeoutMsg_ACC_Lidar" SG_ 648 MO2_Motor_Code 648;
BA_ "GenSigTimeoutTime_EPB" SG_ 648 MO2_Motor_Code 500;
BA_ "GenSigTimeoutMsg_EPB" SG_ 648 MO2_Motor_Code 648;
BA_ "GenSigTimeoutTime_Selespeed" SG_ 648 MO2_Motor_Code 500;
BA_ "GenSigTimeoutMsg_Selespeed" SG_ 648 MO2_Motor_Code 648;
BA_ "GenSigTimeoutTime_Hybrid_DQ200" SG_ 648 MO2_Motor_Code 500;
BA_ "GenSigTimeoutMsg_Hybrid_DQ200" SG_ 648 MO2_Motor_Code 648;
BA_ "GenSigTimeoutTime_Gateway_PQ35_A" SG_ 648 MO2_Motor_Code 500;
BA_ "GenSigTimeoutMsg_Gateway_PQ35_A" SG_ 648 MO2_Motor_Code 648;
BA_ "GenSigTimeoutTime_ACC_Radar" SG_ 648 MO2_Motor_Code 500;
BA_ "GenSigTimeoutMsg_ACC_Radar" SG_ 648 MO2_Motor_Code 648;
BA_ "GenSigTimeoutTime_TRW_ESP" SG_ 648 MO2_Motor_Code 500;
BA_ "GenSigTimeoutMsg_TRW_ESP" SG_ 648 MO2_Motor_Code 648;
BA_ "GenSigTimeoutTime_DQ" SG_ 648 MO2_Motor_Code 500;
BA_ "GenSigTimeoutMsg_DQ" SG_ 648 MO2_Motor_Code 648;
BA_ "GenSigTimeoutTime_Gateway_PQ46_A" SG_ 648 MO2_Motor_Code 500;
BA_ "GenSigTimeoutMsg_Gateway_PQ46_A" SG_ 648 MO2_Motor_Code 648;
BA_ "GenSigTimeoutTime_AG6" SG_ 648 MO2_Motor_Code 500;
BA_ "GenSigTimeoutMsg_AG6" SG_ 648 MO2_Motor_Code 648;
BA_ "GenSigSendType" SG_ 648 MO2_Motor_Code 0;
BA_ "INIT" SG_ 648 MO2_Motor_Code "const";
BA_ "GenSigTimeoutTime_Hybrid_DQ200" SG_ 648 MO2_Mo_ZWR 500;
BA_ "GenSigTimeoutMsg_Hybrid_DQ200" SG_ 648 MO2_Mo_ZWR 648;
BA_ "GenSigTimeoutTime_Gateway_PQ35_A" SG_ 648 MO2_Mo_ZWR 500;
BA_ "GenSigTimeoutMsg_Gateway_PQ35_A" SG_ 648 MO2_Mo_ZWR 648;
BA_ "GenSigTimeoutTime_TRW_ESP" SG_ 648 MO2_Mo_ZWR 500;
BA_ "GenSigTimeoutMsg_TRW_ESP" SG_ 648 MO2_Mo_ZWR 648;
BA_ "GenSigTimeoutTime_DQ" SG_ 648 MO2_Mo_ZWR 500;
BA_ "GenSigTimeoutMsg_DQ" SG_ 648 MO2_Mo_ZWR 648;
BA_ "GenSigTimeoutTime_Gateway_PQ46_A" SG_ 648 MO2_Mo_ZWR 500;
BA_ "GenSigTimeoutMsg_Gateway_PQ46_A" SG_ 648 MO2_Mo_ZWR 648;
BA_ "GenSigTimeoutTime_AG6" SG_ 648 MO2_Mo_ZWR 500;
BA_ "GenSigTimeoutMsg_AG6" SG_ 648 MO2_Mo_ZWR 648;
BA_ "GenSigSendType" SG_ 648 MO2_Mo_ZWR 0;
BA_ "GenSigTimeoutTime_Hybrid_DQ200" SG_ 648 MO2_Begr_Mo 500;
BA_ "GenSigTimeoutMsg_Hybrid_DQ200" SG_ 648 MO2_Begr_Mo 648;
BA_ "GenSigTimeoutTime_Gateway_PQ35_A" SG_ 648 MO2_Begr_Mo 500;
BA_ "GenSigTimeoutMsg_Gateway_PQ35_A" SG_ 648 MO2_Begr_Mo 648;
BA_ "GenSigTimeoutTime_TRW_ESP" SG_ 648 MO2_Begr_Mo 500;
BA_ "GenSigTimeoutMsg_TRW_ESP" SG_ 648 MO2_Begr_Mo 648;
BA_ "GenSigTimeoutTime_DQ" SG_ 648 MO2_Begr_Mo 500;
BA_ "GenSigTimeoutMsg_DQ" SG_ 648 MO2_Begr_Mo 648;
BA_ "GenSigTimeoutTime_Gateway_PQ46_A" SG_ 648 MO2_Begr_Mo 500;
BA_ "GenSigTimeoutMsg_Gateway_PQ46_A" SG_ 648 MO2_Begr_Mo 648;
BA_ "GenSigTimeoutTime_AG6" SG_ 648 MO2_Begr_Mo 500;
BA_ "GenSigTimeoutMsg_AG6" SG_ 648 MO2_Begr_Mo 648;
BA_ "GenSigSendType" SG_ 648 MO2_Begr_Mo 0;
BA_ "GenSigStartValue" SG_ 648 MO2_Begr_Mo 254;
BA_ "GenSigTimeoutTime_EPB" SG_ 648 MO2_Getr_Code 500;
BA_ "GenSigTimeoutMsg_EPB" SG_ 648 MO2_Getr_Code 648;
BA_ "GenSigTimeoutTime_Selespeed" SG_ 648 MO2_Getr_Code 500;
BA_ "GenSigTimeoutMsg_Selespeed" SG_ 648 MO2_Getr_Code 648;
BA_ "GenSigTimeoutTime_Hybrid_DQ200" SG_ 648 MO2_Getr_Code 500;
BA_ "GenSigTimeoutMsg_Hybrid_DQ200" SG_ 648 MO2_Getr_Code 648;
BA_ "GenSigTimeoutTime_RKA_Plus" SG_ 648 MO2_Getr_Code 500;
BA_ "GenSigTimeoutMsg_RKA_Plus" SG_ 648 MO2_Getr_Code 648;
BA_ "GenSigTimeoutTime_Gateway_PQ35_A" SG_ 648 MO2_Getr_Code 500;
BA_ "GenSigTimeoutMsg_Gateway_PQ35_A" SG_ 648 MO2_Getr_Code 648;
BA_ "GenSigTimeoutTime_TRW_ESP" SG_ 648 MO2_Getr_Code 500;
BA_ "GenSigTimeoutMsg_TRW_ESP" SG_ 648 MO2_Getr_Code 648;
BA_ "GenSigTimeoutTime_DQ" SG_ 648 MO2_Getr_Code 500;
BA_ "GenSigTimeoutMsg_DQ" SG_ 648 MO2_Getr_Code 648;
BA_ "GenSigTimeoutTime_Teves_MK70_MAB" SG_ 648 MO2_Getr_Code 500;
BA_ "GenSigTimeoutMsg_Teves_MK70_MAB" SG_ 648 MO2_Getr_Code 648;
BA_ "GenSigTimeoutTime_Teves_MK60_ESP" SG_ 648 MO2_Getr_Code 500;
BA_ "GenSigTimeoutMsg_Teves_MK60_ESP" SG_ 648 MO2_Getr_Code 648;
BA_ "GenSigTimeoutTime_Gateway_PQ46_A" SG_ 648 MO2_Getr_Code 500;
BA_ "GenSigTimeoutMsg_Gateway_PQ46_A" SG_ 648 MO2_Getr_Code 648;
BA_ "GenSigTimeoutTime_AG6" SG_ 648 MO2_Getr_Code 500;
BA_ "GenSigTimeoutMsg_AG6" SG_ 648 MO2_Getr_Code 648;
BA_ "GenSigSendType" SG_ 648 MO2_Getr_Code 0;
BA_ "INIT" SG_ 648 MO2_Getr_Code "const";
BA_ "GenSigTimeoutTime_EPB" SG_ 648 MO2_max_Mo 500;
BA_ "GenSigTimeoutMsg_EPB" SG_ 648 MO2_max_Mo 648;
BA_ "GenSigTimeoutTime_Selespeed" SG_ 648 MO2_max_Mo 500;
BA_ "GenSigTimeoutMsg_Selespeed" SG_ 648 MO2_max_Mo 648;
BA_ "GenSigTimeoutTime_Hybrid_DQ200" SG_ 648 MO2_max_Mo 500;
BA_ "GenSigTimeoutMsg_Hybrid_DQ200" SG_ 648 MO2_max_Mo 648;
BA_ "GenSigTimeoutTime_RKA_Plus" SG_ 648 MO2_max_Mo 500;
BA_ "GenSigTimeoutMsg_RKA_Plus" SG_ 648 MO2_max_Mo 648;
BA_ "GenSigTimeoutTime_Gateway_PQ35_A" SG_ 648 MO2_max_Mo 500;
BA_ "GenSigTimeoutMsg_Gateway_PQ35_A" SG_ 648 MO2_max_Mo 648;
BA_ "GenSigTimeoutTime_TRW_ESP" SG_ 648 MO2_max_Mo 500;
BA_ "GenSigTimeoutMsg_TRW_ESP" SG_ 648 MO2_max_Mo 648;
BA_ "GenSigTimeoutTime_DQ" SG_ 648 MO2_max_Mo 500;
BA_ "GenSigTimeoutMsg_DQ" SG_ 648 MO2_max_Mo 648;
BA_ "GenSigTimeoutTime_Allrad" SG_ 648 MO2_max_Mo 500;
BA_ "GenSigTimeoutMsg_Allrad" SG_ 648 MO2_max_Mo 648;
BA_ "GenSigTimeoutTime_Gateway_PQ46_A" SG_ 648 MO2_max_Mo 500;
BA_ "GenSigTimeoutMsg_Gateway_PQ46_A" SG_ 648 MO2_max_Mo 648;
BA_ "GenSigTimeoutTime_AG6" SG_ 648 MO2_max_Mo 500;
BA_ "GenSigTimeoutMsg_AG6" SG_ 648 MO2_max_Mo 648;
BA_ "GenSigSendType" SG_ 648 MO2_max_Mo 0;
BA_ "INIT" SG_ 648 MO2_max_Mo "const";
BA_ "GenSigTimeoutTime_TRW_ESP" SG_ 648 MO2_Sta_Limiter 500;
BA_ "GenSigTimeoutMsg_TRW_ESP" SG_ 648 MO2_Sta_Limiter 648;
BA_ "GenSigTimeoutTime_Gateway_PQ35_A" SG_ 648 MO2_Sta_Limiter 500;
BA_ "GenSigTimeoutMsg_Gateway_PQ35_A" SG_ 648 MO2_Sta_Limiter 648;
BA_ "GenSigTimeoutTime_Gateway_PQ46_A" SG_ 648 MO2_Sta_Limiter 500;
BA_ "GenSigTimeoutMsg_Gateway_PQ46_A" SG_ 648 MO2_Sta_Limiter 648;
BA_ "GenSigSendType" SG_ 648 MO2_Sta_Limiter 0;
BA_ "GenSigTimeoutTime_TRW_ESP" SG_ 648 MO2_RME_Gehalt 500;
BA_ "GenSigTimeoutMsg_TRW_ESP" SG_ 648 MO2_RME_Gehalt 648;
BA_ "GenSigTimeoutTime_Gateway_PQ35_A" SG_ 648 MO2_RME_Gehalt 500;
BA_ "GenSigTimeoutMsg_Gateway_PQ35_A" SG_ 648 MO2_RME_Gehalt 648;
BA_ "GenSigTimeoutTime_Gateway_PQ46_A" SG_ 648 MO2_RME_Gehalt 500;
BA_ "GenSigTimeoutMsg_Gateway_PQ46_A" SG_ 648 MO2_RME_Gehalt 648;
BA_ "GenSigSendType" SG_ 648 MO2_RME_Gehalt 0;
BA_ "GenSigTimeoutTime_Hybrid_DQ200" SG_ 648 MO2_GRAregelt 500;
BA_ "GenSigTimeoutMsg_Hybrid_DQ200" SG_ 648 MO2_GRAregelt 648;
BA_ "GenSigTimeoutTime_Gateway_PQ35_A" SG_ 648 MO2_GRAregelt 500;
BA_ "GenSigTimeoutMsg_Gateway_PQ35_A" SG_ 648 MO2_GRAregelt 648;
BA_ "GenSigTimeoutTime_TRW_ESP" SG_ 648 MO2_GRAregelt 500;
BA_ "GenSigTimeoutMsg_TRW_ESP" SG_ 648 MO2_GRAregelt 648;
BA_ "GenSigTimeoutTime_DQ" SG_ 648 MO2_GRAregelt 500;
BA_ "GenSigTimeoutMsg_DQ" SG_ 648 MO2_GRAregelt 648;
BA_ "GenSigTimeoutTime_Gateway_PQ46_A" SG_ 648 MO2_GRAregelt 500;
BA_ "GenSigTimeoutMsg_Gateway_PQ46_A" SG_ 648 MO2_GRAregelt 648;
BA_ "GenSigSendType" SG_ 648 MO2_GRAregelt 0;
BA_ "GenSigTimeoutTime_Gateway_PQ35_A" SG_ 648 MO2_OffRoad 500;
BA_ "GenSigTimeoutMsg_Gateway_PQ35_A" SG_ 648 MO2_OffRoad 648;
BA_ "GenSigTimeoutTime_TRW_ESP" SG_ 648 MO2_OffRoad 500;
BA_ "GenSigTimeoutMsg_TRW_ESP" SG_ 648 MO2_OffRoad 648;
BA_ "GenSigTimeoutTime_Gateway_PQ46_A" SG_ 648 MO2_OffRoad 500;
BA_ "GenSigTimeoutMsg_Gateway_PQ46_A" SG_ 648 MO2_OffRoad 648;
BA_ "GenSigTimeoutTime_AG6" SG_ 648 MO2_OffRoad 500;
BA_ "GenSigTimeoutMsg_AG6" SG_ 648 MO2_OffRoad 648;
BA_ "GenSigSendType" SG_ 648 MO2_OffRoad 0;
BA_ "GenSigTimeoutTime_Hybrid_DQ200" SG_ 648 MO2_GRA_Soll 500;
BA_ "GenSigTimeoutMsg_Hybrid_DQ200" SG_ 648 MO2_GRA_Soll 648;
BA_ "GenSigTimeoutTime_Gateway_PQ35_A" SG_ 648 MO2_GRA_Soll 500;
BA_ "GenSigTimeoutMsg_Gateway_PQ35_A" SG_ 648 MO2_GRA_Soll 648;
BA_ "GenSigTimeoutTime_TRW_ESP" SG_ 648 MO2_GRA_Soll 500;
BA_ "GenSigTimeoutMsg_TRW_ESP" SG_ 648 MO2_GRA_Soll 648;
BA_ "GenSigTimeoutTime_DQ" SG_ 648 MO2_GRA_Soll 500;
BA_ "GenSigTimeoutMsg_DQ" SG_ 648 MO2_GRA_Soll 648;
BA_ "GenSigTimeoutTime_Gateway_PQ46_A" SG_ 648 MO2_GRA_Soll 500;
BA_ "GenSigTimeoutMsg_Gateway_PQ46_A" SG_ 648 MO2_GRA_Soll 648;
BA_ "GenSigTimeoutTime_AG6" SG_ 648 MO2_GRA_Soll 500;
BA_ "GenSigTimeoutMsg_AG6" SG_ 648 MO2_GRA_Soll 648;
BA_ "GenSigSendType" SG_ 648 MO2_GRA_Soll 0;
BA_ "GenSigTimeoutTime_Gateway_PQ35_A" SG_ 1416 MO7_Sta_VBegr 500;
BA_ "GenSigTimeoutMsg_Gateway_PQ35_A" SG_ 1416 MO7_Sta_VBegr 1416;
BA_ "GenSigTimeoutTime_Gateway_PQ46_A" SG_ 1416 MO7_Sta_VBegr 500;
BA_ "GenSigTimeoutMsg_Gateway_PQ46_A" SG_ 1416 MO7_Sta_VBegr 1416;
BA_ "GenSigSendType" SG_ 1416 MO7_Sta_VBegr 0;
BA_ "GenSigTimeoutTime_Gateway_PQ35_A" SG_ 1416 MO7_Fehlereintr 500;
BA_ "GenSigTimeoutMsg_Gateway_PQ35_A" SG_ 1416 MO7_Fehlereintr 1416;
BA_ "GenSigTimeoutTime_Gateway_PQ46_A" SG_ 1416 MO7_Fehlereintr 500;
BA_ "GenSigTimeoutMsg_Gateway_PQ46_A" SG_ 1416 MO7_Fehlereintr 1416;
BA_ "GenSigSendType" SG_ 1416 MO7_Fehlereintr 0;
BA_ "GenSigTimeoutTime_Gateway_PQ35_A" SG_ 1416 MO7_DFM 500;
BA_ "GenSigTimeoutMsg_Gateway_PQ35_A" SG_ 1416 MO7_DFM 1416;
BA_ "GenSigTimeoutTime_Gateway_PQ46_A" SG_ 1416 MO7_DFM 500;
BA_ "GenSigTimeoutMsg_Gateway_PQ46_A" SG_ 1416 MO7_DFM 1416;
BA_ "GenSigSendType" SG_ 1416 MO7_DFM 0;
BA_ "GenSigTimeoutTime_Gateway_PQ35_A" SG_ 1416 MO7_Sta_PTC 500;
BA_ "GenSigTimeoutMsg_Gateway_PQ35_A" SG_ 1416 MO7_Sta_PTC 1416;
BA_ "GenSigTimeoutTime_Gateway_PQ46_A" SG_ 1416 MO7_Sta_PTC 500;
BA_ "GenSigTimeoutMsg_Gateway_PQ46_A" SG_ 1416 MO7_Sta_PTC 1416;
BA_ "GenSigSendType" SG_ 1416 MO7_Sta_PTC 0;
BA_ "GenSigStartValue" SG_ 1416 MO7_Sta_PTC 7;
BA_ "GenSigTimeoutTime_Gateway_PQ35_A" SG_ 1416 MO7_Fehler_VBegr 500;
BA_ "GenSigTimeoutMsg_Gateway_PQ35_A" SG_ 1416 MO7_Fehler_VBegr 1416;
BA_ "GenSigTimeoutTime_Gateway_PQ46_A" SG_ 1416 MO7_Fehler_VBegr 500;
BA_ "GenSigTimeoutMsg_Gateway_PQ46_A" SG_ 1416 MO7_Fehler_VBegr 1416;
BA_ "GenSigSendType" SG_ 1416 MO7_Fehler_VBegr 0;
BA_ "GenSigTimeoutTime_Gateway_PQ35_A" SG_ 1416 MO7_StaOeltemp 500;
BA_ "GenSigTimeoutMsg_Gateway_PQ35_A" SG_ 1416 MO7_StaOeltemp 1416;
BA_ "GenSigTimeoutTime_Gateway_PQ46_A" SG_ 1416 MO7_StaOeltemp 500;
BA_ "GenSigTimeoutMsg_Gateway_PQ46_A" SG_ 1416 MO7_StaOeltemp 1416;
BA_ "GenSigSendType" SG_ 1416 MO7_StaOeltemp 0;
BA_ "GenSigStartValue" SG_ 1416 MO7_StaOeltemp 1;
BA_ "GenSigTimeoutTime_Gateway_PQ35_A" SG_ 1416 MO7_LL_Solldz 500;
BA_ "GenSigTimeoutMsg_Gateway_PQ35_A" SG_ 1416 MO7_LL_Solldz 1416;
BA_ "GenSigTimeoutTime_Gateway_PQ46_A" SG_ 1416 MO7_LL_Solldz 500;
BA_ "GenSigTimeoutMsg_Gateway_PQ46_A" SG_ 1416 MO7_LL_Solldz 1416;
BA_ "GenSigSendType" SG_ 1416 MO7_LL_Solldz 0;
BA_ "GenSigTimeoutTime_Gateway_PQ35_A" SG_ 1416 MO7_Gradient_Dz 500;
BA_ "GenSigTimeoutMsg_Gateway_PQ35_A" SG_ 1416 MO7_Gradient_Dz 1416;
BA_ "GenSigTimeoutTime_Gateway_PQ46_A" SG_ 1416 MO7_Gradient_Dz 500;
BA_ "GenSigTimeoutMsg_Gateway_PQ46_A" SG_ 1416 MO7_Gradient_Dz 1416;
BA_ "GenSigSendType" SG_ 1416 MO7_Gradient_Dz 0;
BA_ "GenSigTimeoutTime_Gateway_PQ35_A" SG_ 1416 MO7_GradientVorz 500;
BA_ "GenSigTimeoutMsg_Gateway_PQ35_A" SG_ 1416 MO7_GradientVorz 1416;
BA_ "GenSigTimeoutTime_Gateway_PQ46_A" SG_ 1416 MO7_GradientVorz 500;
BA_ "GenSigTimeoutMsg_Gateway_PQ46_A" SG_ 1416 MO7_GradientVorz 1416;
BA_ "GenSigSendType" SG_ 1416 MO7_GradientVorz 0;
BA_ "GenSigTimeoutTime_TRW_ESP" SG_ 1416 MO7_Hoeheninfo 500;
BA_ "GenSigTimeoutMsg_TRW_ESP" SG_ 1416 MO7_Hoeheninfo 1416;
BA_ "GenSigTimeoutTime_Teves_MK70_MAB" SG_ 1416 MO7_Hoeheninfo 500;
BA_ "GenSigTimeoutMsg_Teves_MK70_MAB" SG_ 1416 MO7_Hoeheninfo 1416;
BA_ "GenSigTimeoutTime_Teves_MK60_ESP" SG_ 1416 MO7_Hoeheninfo 500;
BA_ "GenSigTimeoutMsg_Teves_MK60_ESP" SG_ 1416 MO7_Hoeheninfo 1416;
BA_ "GenSigTimeoutTime_Selespeed" SG_ 1416 MO7_Hoeheninfo 500;
BA_ "GenSigTimeoutMsg_Selespeed" SG_ 1416 MO7_Hoeheninfo 1416;
BA_ "GenSigTimeoutTime_Gateway_PQ35_A" SG_ 1416 MO7_Hoeheninfo 500;
BA_ "GenSigTimeoutMsg_Gateway_PQ35_A" SG_ 1416 MO7_Hoeheninfo 1416;
BA_ "GenSigTimeoutTime_DQ" SG_ 1416 MO7_Hoeheninfo 500;
BA_ "GenSigTimeoutMsg_DQ" SG_ 1416 MO7_Hoeheninfo 1416;
BA_ "GenSigTimeoutTime_Gateway_PQ46_A" SG_ 1416 MO7_Hoeheninfo 500;
BA_ "GenSigTimeoutMsg_Gateway_PQ46_A" SG_ 1416 MO7_Hoeheninfo 1416;
BA_ "GenSigSendType" SG_ 1416 MO7_Hoeheninfo 0;
BA_ "GenSigTimeoutTime_Gateway_PQ35_A" SG_ 1416 MO7_RueckLLDz 500;
BA_ "GenSigTimeoutMsg_Gateway_PQ35_A" SG_ 1416 MO7_RueckLLDz 1416;
BA_ "GenSigTimeoutTime_Gateway_PQ46_A" SG_ 1416 MO7_RueckLLDz 500;
BA_ "GenSigTimeoutMsg_Gateway_PQ46_A" SG_ 1416 MO7_RueckLLDz 1416;
BA_ "GenSigSendType" SG_ 1416 MO7_RueckLLDz 0;
BA_ "GenSigTimeoutTime_Selespeed" SG_ 1416 MO7_Oeltemp 500;
BA_ "GenSigTimeoutMsg_Selespeed" SG_ 1416 MO7_Oeltemp 1416;
BA_ "GenSigTimeoutTime_Gateway_PQ35_A" SG_ 1416 MO7_Oeltemp 500;
BA_ "GenSigTimeoutMsg_Gateway_PQ35_A" SG_ 1416 MO7_Oeltemp 1416;
BA_ "GenSigTimeoutTime_Gateway_PQ46_A" SG_ 1416 MO7_Oeltemp 500;
BA_ "GenSigTimeoutMsg_Gateway_PQ46_A" SG_ 1416 MO7_Oeltemp 1416;
BA_ "GenSigSendType" SG_ 1416 MO7_Oeltemp 0;
BA_ "GenSigStartValue" SG_ 1416 MO7_Oeltemp 1;
BA_ "GenSigTimeoutTime_Gateway_PQ35_A" SG_ 1416 MO7_PTC_bereit 500;
BA_ "GenSigTimeoutMsg_Gateway_PQ35_A" SG_ 1416 MO7_PTC_bereit 1416;
BA_ "GenSigTimeoutTime_Gateway_PQ46_A" SG_ 1416 MO7_PTC_bereit 500;
BA_ "GenSigTimeoutMsg_Gateway_PQ46_A" SG_ 1416 MO7_PTC_bereit 1416;
BA_ "GenSigSendType" SG_ 1416 MO7_PTC_bereit 0;
BA_ "GenSigTimeoutTime_Gateway_PQ35_A" SG_ 1416 MO7_Gen_ein 500;
BA_ "GenSigTimeoutMsg_Gateway_PQ35_A" SG_ 1416 MO7_Gen_ein 1416;
BA_ "GenSigTimeoutTime_Gateway_PQ46_A" SG_ 1416 MO7_Gen_ein 500;
BA_ "GenSigTimeoutMsg_Gateway_PQ46_A" SG_ 1416 MO7_Gen_ein 1416;
BA_ "GenSigSendType" SG_ 1416 MO7_Gen_ein 0;
BA_ "GenSigTimeoutTime_Gateway_PQ35_A" SG_ 1416 MO7_Lastabwurf 500;
BA_ "GenSigTimeoutMsg_Gateway_PQ35_A" SG_ 1416 MO7_Lastabwurf 1416;
BA_ "GenSigTimeoutTime_Gateway_PQ46_A" SG_ 1416 MO7_Lastabwurf 500;
BA_ "GenSigTimeoutMsg_Gateway_PQ46_A" SG_ 1416 MO7_Lastabwurf 1416;
BA_ "GenSigSendType" SG_ 1416 MO7_Lastabwurf 0;
BA_ "GenSigTimeoutTime_Gateway_PQ35_A" SG_ 1416 MO7_StaGluehk 500;
BA_ "GenSigTimeoutMsg_Gateway_PQ35_A" SG_ 1416 MO7_StaGluehk 1416;
BA_ "GenSigTimeoutTime_Gateway_PQ46_A" SG_ 1416 MO7_StaGluehk 500;
BA_ "GenSigTimeoutMsg_Gateway_PQ46_A" SG_ 1416 MO7_StaGluehk 1416;
BA_ "GenSigSendType" SG_ 1416 MO7_StaGluehk 0;
BA_ "GenSigTimeoutTime_Gateway_PQ35_A" SG_ 1416 MO7_Lastabw_Heiz 500;
BA_ "GenSigTimeoutMsg_Gateway_PQ35_A" SG_ 1416 MO7_Lastabw_Heiz 1416;
BA_ "GenSigTimeoutTime_Gateway_PQ46_A" SG_ 1416 MO7_Lastabw_Heiz 500;
BA_ "GenSigTimeoutMsg_Gateway_PQ46_A" SG_ 1416 MO7_Lastabw_Heiz 1416;
BA_ "GenSigSendType" SG_ 1416 MO7_Lastabw_Heiz 0;
BA_ "GenSigTimeoutTime_Gateway_PQ35_A" SG_ 1416 MO7_GenLdResp 500;
BA_ "GenSigTimeoutMsg_Gateway_PQ35_A" SG_ 1416 MO7_GenLdResp 1416;
BA_ "GenSigTimeoutTime_Gateway_PQ46_A" SG_ 1416 MO7_GenLdResp 500;
BA_ "GenSigTimeoutMsg_Gateway_PQ46_A" SG_ 1416 MO7_GenLdResp 1416;
BA_ "GenSigSendType" SG_ 1416 MO7_GenLdResp 0;
BA_ "GenSigTimeoutTime_Gateway_PQ35_A" SG_ 1416 MO7_SleepInd 500;
BA_ "GenSigTimeoutMsg_Gateway_PQ35_A" SG_ 1416 MO7_SleepInd 1416;
BA_ "GenSigTimeoutTime_Gateway_PQ46_A" SG_ 1416 MO7_SleepInd 500;
BA_ "GenSigTimeoutMsg_Gateway_PQ46_A" SG_ 1416 MO7_SleepInd 1416;
BA_ "GenSigSendType" SG_ 1416 MO7_SleepInd 0;
BA_ "GenSigTimeoutTime_Gateway_PQ35_A" SG_ 1416 MO7_Zus_Kuehl 500;
BA_ "GenSigTimeoutMsg_Gateway_PQ35_A" SG_ 1416 MO7_Zus_Kuehl 1416;
BA_ "GenSigTimeoutTime_Gateway_PQ46_A" SG_ 1416 MO7_Zus_Kuehl 500;
BA_ "GenSigTimeoutMsg_Gateway_PQ46_A" SG_ 1416 MO7_Zus_Kuehl 1416;
BA_ "GenSigSendType" SG_ 1416 MO7_Zus_Kuehl 0;
BA_ "GenSigTimeoutTime_Gateway_PQ35_A" SG_ 1416 MO7_Mot_weckfaehig 500;
BA_ "GenSigTimeoutMsg_Gateway_PQ35_A" SG_ 1416 MO7_Mot_weckfaehig 1416;
BA_ "GenSigTimeoutTime_Gateway_PQ46_A" SG_ 1416 MO7_Mot_weckfaehig 500;
BA_ "GenSigTimeoutMsg_Gateway_PQ46_A" SG_ 1416 MO7_Mot_weckfaehig 1416;
BA_ "GenSigSendType" SG_ 1416 MO7_Mot_weckfaehig 0;
BA_ "INIT" SG_ 1416 MO7_Mot_weckfaehig "const";
BA_ "GenSigTimeoutTime_Gateway_PQ46_A" SG_ 1416 MO7_Ladedruckneu 500;
BA_ "GenSigTimeoutMsg_Gateway_PQ46_A" SG_ 1416 MO7_Ladedruckneu 1416;
BA_ "GenSigTimeoutTime_Gateway_PQ35_A" SG_ 1416 MO7_Ladedruckneu 500;
BA_ "GenSigTimeoutMsg_Gateway_PQ35_A" SG_ 1416 MO7_Ladedruckneu 1416;
BA_ "GenSigSendType" SG_ 1416 MO7_Ladedruckneu 0;
BA_ "GenSigTimeoutTime_TRW_ESP" SG_ 1408 MFN_Offset_Nachf 5000;
BA_ "GenSigTimeoutMsg_TRW_ESP" SG_ 1408 MFN_Offset_Nachf 1408;
BA_ "GenSigTimeoutTime_Gateway_PQ35_A" SG_ 1408 MFN_Offset_Nachf 5000;
BA_ "GenSigTimeoutMsg_Gateway_PQ35_A" SG_ 1408 MFN_Offset_Nachf 1408;
BA_ "GenSigTimeoutTime_Gateway_PQ46_A" SG_ 1408 MFN_Offset_Nachf 5000;
BA_ "GenSigTimeoutMsg_Gateway_PQ46_A" SG_ 1408 MFN_Offset_Nachf 1408;
BA_ "GenSigSendType" SG_ 1408 MFN_Offset_Nachf 0;
BA_ "INIT" SG_ 1408 MFN_Offset_Nachf "const";
BA_ "GenSigTimeoutTime_Gateway_PQ35_A" SG_ 1408 MFN_Ansaugsys 5000;
BA_ "GenSigTimeoutMsg_Gateway_PQ35_A" SG_ 1408 MFN_Ansaugsys 1408;
BA_ "GenSigTimeoutTime_TRW_ESP" SG_ 1408 MFN_Ansaugsys 5000;
BA_ "GenSigTimeoutMsg_TRW_ESP" SG_ 1408 MFN_Ansaugsys 1408;
BA_ "GenSigTimeoutTime_Gateway_PQ46_A" SG_ 1408 MFN_Ansaugsys 5000;
BA_ "GenSigTimeoutMsg_Gateway_PQ46_A" SG_ 1408 MFN_Ansaugsys 1408;
BA_ "GenSigSendType" SG_ 1408 MFN_Ansaugsys 0;
BA_ "INIT" SG_ 1408 MFN_Ansaugsys "const";
BA_ "GenSigTimeoutTime_TRW_ESP" SG_ 1408 MFN_Tol_Oelwarn 5000;
BA_ "GenSigTimeoutMsg_TRW_ESP" SG_ 1408 MFN_Tol_Oelwarn 1408;
BA_ "GenSigTimeoutTime_Gateway_PQ35_A" SG_ 1408 MFN_Tol_Oelwarn 5000;
BA_ "GenSigTimeoutMsg_Gateway_PQ35_A" SG_ 1408 MFN_Tol_Oelwarn 1408;
BA_ "GenSigTimeoutTime_Gateway_PQ46_A" SG_ 1408 MFN_Tol_Oelwarn 5000;
BA_ "GenSigTimeoutMsg_Gateway_PQ46_A" SG_ 1408 MFN_Tol_Oelwarn 1408;
BA_ "GenSigSendType" SG_ 1408 MFN_Tol_Oelwarn 0;
BA_ "INIT" SG_ 1408 MFN_Tol_Oelwarn "const";
BA_ "GenSigTimeoutTime_TRW_ESP" SG_ 1408 MFN_AnzMitOel 5000;
BA_ "GenSigTimeoutMsg_TRW_ESP" SG_ 1408 MFN_AnzMitOel 1408;
BA_ "GenSigTimeoutTime_Gateway_PQ35_A" SG_ 1408 MFN_AnzMitOel 5000;
BA_ "GenSigTimeoutMsg_Gateway_PQ35_A" SG_ 1408 MFN_AnzMitOel 1408;
BA_ "GenSigTimeoutTime_Gateway_PQ46_A" SG_ 1408 MFN_AnzMitOel 5000;
BA_ "GenSigTimeoutMsg_Gateway_PQ46_A" SG_ 1408 MFN_AnzMitOel 1408;
BA_ "GenSigSendType" SG_ 1408 MFN_AnzMitOel 0;
BA_ "INIT" SG_ 1408 MFN_AnzMitOel "const";
BA_ "GenSigTimeoutTime_TRW_ESP" SG_ 1408 MFN_max_Moment 5000;
BA_ "GenSigTimeoutMsg_TRW_ESP" SG_ 1408 MFN_max_Moment 1408;
BA_ "GenSigTimeoutTime_Gateway_PQ35_A" SG_ 1408 MFN_max_Moment 5000;
BA_ "GenSigTimeoutMsg_Gateway_PQ35_A" SG_ 1408 MFN_max_Moment 1408;
BA_ "GenSigTimeoutTime_Gateway_PQ46_A" SG_ 1408 MFN_max_Moment 5000;
BA_ "GenSigTimeoutMsg_Gateway_PQ46_A" SG_ 1408 MFN_max_Moment 1408;
BA_ "GenSigSendType" SG_ 1408 MFN_max_Moment 0;
BA_ "INIT" SG_ 1408 MFN_max_Moment "const";
BA_ "GenSigTimeoutTime_ACC_Lidar" SG_ 1408 MFN_Motorleistung 5000;
BA_ "GenSigTimeoutMsg_ACC_Lidar" SG_ 1408 MFN_Motorleistung 1408;
BA_ "GenSigTimeoutTime_EPB" SG_ 1408 MFN_Motorleistung 5000;
BA_ "GenSigTimeoutMsg_EPB" SG_ 1408 MFN_Motorleistung 1408;
BA_ "GenSigTimeoutTime_Gateway_PQ35_A" SG_ 1408 MFN_Motorleistung 5000;
BA_ "GenSigTimeoutMsg_Gateway_PQ35_A" SG_ 1408 MFN_Motorleistung 1408;
BA_ "GenSigTimeoutTime_ACC_Radar" SG_ 1408 MFN_Motorleistung 5000;
BA_ "GenSigTimeoutMsg_ACC_Radar" SG_ 1408 MFN_Motorleistung 1408;
BA_ "GenSigTimeoutTime_TRW_ESP" SG_ 1408 MFN_Motorleistung 5000;
BA_ "GenSigTimeoutMsg_TRW_ESP" SG_ 1408 MFN_Motorleistung 1408;
BA_ "GenSigTimeoutTime_Gateway_PQ46_A" SG_ 1408 MFN_Motorleistung 5000;
BA_ "GenSigTimeoutMsg_Gateway_PQ46_A" SG_ 1408 MFN_Motorleistung 1408;
BA_ "GenSigSendType" SG_ 1408 MFN_Motorleistung 0;
BA_ "INIT" SG_ 1408 MFN_Motorleistung "const";
BA_ "GenSigTimeoutTime_TRW_ESP" SG_ 1408 MFN_Drz_max_Mo 5000;
BA_ "GenSigTimeoutMsg_TRW_ESP" SG_ 1408 MFN_Drz_max_Mo 1408;
BA_ "GenSigTimeoutTime_Gateway_PQ35_A" SG_ 1408 MFN_Drz_max_Mo 5000;
BA_ "GenSigTimeoutMsg_Gateway_PQ35_A" SG_ 1408 MFN_Drz_max_Mo 1408;
BA_ "GenSigTimeoutTime_Gateway_PQ46_A" SG_ 1408 MFN_Drz_max_Mo 5000;
BA_ "GenSigTimeoutMsg_Gateway_PQ46_A" SG_ 1408 MFN_Drz_max_Mo 1408;
BA_ "GenSigSendType" SG_ 1408 MFN_Drz_max_Mo 0;
BA_ "INIT" SG_ 1408 MFN_Drz_max_Mo "const";
BA_ "GenSigTimeoutTime_EPB" SG_ 1408 MFN_Hubraum 5000;
BA_ "GenSigTimeoutMsg_EPB" SG_ 1408 MFN_Hubraum 1408;
BA_ "GenSigTimeoutTime_Gateway_PQ35_A" SG_ 1408 MFN_Hubraum 5000;
BA_ "GenSigTimeoutMsg_Gateway_PQ35_A" SG_ 1408 MFN_Hubraum 1408;
BA_ "GenSigTimeoutTime_TRW_ESP" SG_ 1408 MFN_Hubraum 5000;
BA_ "GenSigTimeoutMsg_TRW_ESP" SG_ 1408 MFN_Hubraum 1408;
BA_ "GenSigTimeoutTime_Gateway_PQ46_A" SG_ 1408 MFN_Hubraum 5000;
BA_ "GenSigTimeoutMsg_Gateway_PQ46_A" SG_ 1408 MFN_Hubraum 1408;
BA_ "GenSigSendType" SG_ 1408 MFN_Hubraum 0;
BA_ "INIT" SG_ 1408 MFN_Hubraum "const";
BA_ "GenSigTimeoutTime_TRW_ESP" SG_ 1408 MFN_Max_Offset 5000;
BA_ "GenSigTimeoutMsg_TRW_ESP" SG_ 1408 MFN_Max_Offset 1408;
BA_ "GenSigTimeoutTime_Gateway_PQ35_A" SG_ 1408 MFN_Max_Offset 5000;
BA_ "GenSigTimeoutMsg_Gateway_PQ35_A" SG_ 1408 MFN_Max_Offset 1408;
BA_ "GenSigTimeoutTime_Gateway_PQ46_A" SG_ 1408 MFN_Max_Offset 5000;
BA_ "GenSigTimeoutMsg_Gateway_PQ46_A" SG_ 1408 MFN_Max_Offset 1408;
BA_ "GenSigSendType" SG_ 1408 MFN_Max_Offset 0;
BA_ "INIT" SG_ 1408 MFN_Max_Offset "const";
BA_ "GenSigTimeoutTime_TRW_ESP" SG_ 1408 MFN_KurzzeitMW 5000;
BA_ "GenSigTimeoutMsg_TRW_ESP" SG_ 1408 MFN_KurzzeitMW 1408;
BA_ "GenSigTimeoutTime_Gateway_PQ35_A" SG_ 1408 MFN_KurzzeitMW 5000;
BA_ "GenSigTimeoutMsg_Gateway_PQ35_A" SG_ 1408 MFN_KurzzeitMW 1408;
BA_ "GenSigTimeoutTime_Gateway_PQ46_A" SG_ 1408 MFN_KurzzeitMW 5000;
BA_ "GenSigTimeoutMsg_Gateway_PQ46_A" SG_ 1408 MFN_KurzzeitMW 1408;
BA_ "GenSigSendType" SG_ 1408 MFN_KurzzeitMW 0;
BA_ "GenSigTimeoutTime_TRW_ESP" SG_ 1408 MFN_Russindex 5000;
BA_ "GenSigTimeoutMsg_TRW_ESP" SG_ 1408 MFN_Russindex 1408;
BA_ "GenSigTimeoutTime_Gateway_PQ35_A" SG_ 1408 MFN_Russindex 5000;
BA_ "GenSigTimeoutMsg_Gateway_PQ35_A" SG_ 1408 MFN_Russindex 1408;
BA_ "GenSigTimeoutTime_Gateway_PQ46_A" SG_ 1408 MFN_Russindex 5000;
BA_ "GenSigTimeoutMsg_Gateway_PQ46_A" SG_ 1408 MFN_Russindex 1408;
BA_ "GenSigSendType" SG_ 1408 MFN_Russindex 0;
BA_ "GenSigTimeoutTime_DQ" SG_ 1408 MFN_NormedTrip 5000;
BA_ "GenSigTimeoutMsg_DQ" SG_ 1408 MFN_NormedTrip 1408;
BA_ "GenSigTimeoutTime_AG6" SG_ 1408 MFN_NormedTrip 5000;
BA_ "GenSigTimeoutMsg_AG6" SG_ 1408 MFN_NormedTrip 1408;
BA_ "GenSigTimeoutTime_TRW_ESP" SG_ 1408 MFN_NormedTrip 5000;
BA_ "GenSigTimeoutMsg_TRW_ESP" SG_ 1408 MFN_NormedTrip 1408;
BA_ "GenSigTimeoutTime_Gateway_PQ35_A" SG_ 1408 MFN_NormedTrip 5000;
BA_ "GenSigTimeoutMsg_Gateway_PQ35_A" SG_ 1408 MFN_NormedTrip 1408;
BA_ "GenSigTimeoutTime_Gateway_PQ46_A" SG_ 1408 MFN_NormedTrip 5000;
BA_ "GenSigTimeoutMsg_Gateway_PQ46_A" SG_ 1408 MFN_NormedTrip 1408;
BA_ "GenSigSendType" SG_ 1408 MFN_NormedTrip 0;
BA_ "GenSigTimeoutTime_TRW_ESP" SG_ 1408 MFN_Oelstand 5000;
BA_ "GenSigTimeoutMsg_TRW_ESP" SG_ 1408 MFN_Oelstand 1408;
BA_ "GenSigTimeoutTime_Gateway_PQ35_A" SG_ 1408 MFN_Oelstand 5000;
BA_ "GenSigTimeoutMsg_Gateway_PQ35_A" SG_ 1408 MFN_Oelstand 1408;
BA_ "GenSigTimeoutTime_Gateway_PQ46_A" SG_ 1408 MFN_Oelstand 5000;
BA_ "GenSigTimeoutMsg_Gateway_PQ46_A" SG_ 1408 MFN_Oelstand 1408;
BA_ "GenSigSendType" SG_ 1408 MFN_Oelstand 0;
BA_ "GenSigTimeoutTime_TRW_ESP" SG_ 1408 MFN_Zylinder 5000;
BA_ "GenSigTimeoutMsg_TRW_ESP" SG_ 1408 MFN_Zylinder 1408;
BA_ "GenSigTimeoutTime_Gateway_PQ35_A" SG_ 1408 MFN_Zylinder 5000;
BA_ "GenSigTimeoutMsg_Gateway_PQ35_A" SG_ 1408 MFN_Zylinder 1408;
BA_ "GenSigTimeoutTime_Gateway_PQ46_A" SG_ 1408 MFN_Zylinder 5000;
BA_ "GenSigTimeoutMsg_Gateway_PQ46_A" SG_ 1408 MFN_Zylinder 1408;
BA_ "GenSigSendType" SG_ 1408 MFN_Zylinder 0;
BA_ "INIT" SG_ 1408 MFN_Zylinder "const";
BA_ "GenSigTimeoutTime_ACC_Lidar" SG_ 1408 MFN_Zaehler 5000;
BA_ "GenSigTimeoutMsg_ACC_Lidar" SG_ 1408 MFN_Zaehler 1408;
BA_ "GenSigTimeoutTime_EPB" SG_ 1408 MFN_Zaehler 5000;
BA_ "GenSigTimeoutMsg_EPB" SG_ 1408 MFN_Zaehler 1408;
BA_ "GenSigTimeoutTime_Gateway_PQ35_A" SG_ 1408 MFN_Zaehler 5000;
BA_ "GenSigTimeoutMsg_Gateway_PQ35_A" SG_ 1408 MFN_Zaehler 1408;
BA_ "GenSigTimeoutTime_ACC_Radar" SG_ 1408 MFN_Zaehler 5000;
BA_ "GenSigTimeoutMsg_ACC_Radar" SG_ 1408 MFN_Zaehler 1408;
BA_ "GenSigTimeoutTime_TRW_ESP" SG_ 1408 MFN_Zaehler 5000;
BA_ "GenSigTimeoutMsg_TRW_ESP" SG_ 1408 MFN_Zaehler 1408;
BA_ "GenSigTimeoutTime_Gateway_PQ46_A" SG_ 1408 MFN_Zaehler 5000;
BA_ "GenSigTimeoutMsg_Gateway_PQ46_A" SG_ 1408 MFN_Zaehler 1408;
BA_ "GenSigSendType" SG_ 1408 MFN_Zaehler 0;
BA_ "GenSigTimeoutTime_EPB" SG_ 1408 MFN_Verbrenn_Typ 5000;
BA_ "GenSigTimeoutMsg_EPB" SG_ 1408 MFN_Verbrenn_Typ 1408;
BA_ "GenSigTimeoutTime_Gateway_PQ35_A" SG_ 1408 MFN_Verbrenn_Typ 5000;
BA_ "GenSigTimeoutMsg_Gateway_PQ35_A" SG_ 1408 MFN_Verbrenn_Typ 1408;
BA_ "GenSigTimeoutTime_TRW_ESP" SG_ 1408 MFN_Verbrenn_Typ 5000;
BA_ "GenSigTimeoutMsg_TRW_ESP" SG_ 1408 MFN_Verbrenn_Typ 1408;
BA_ "GenSigTimeoutTime_Gateway_PQ46_A" SG_ 1408 MFN_Verbrenn_Typ 5000;
BA_ "GenSigTimeoutMsg_Gateway_PQ46_A" SG_ 1408 MFN_Verbrenn_Typ 1408;
BA_ "GenSigSendType" SG_ 1408 MFN_Verbrenn_Typ 0;
BA_ "INIT" SG_ 1408 MFN_Verbrenn_Typ "const";
BA_ "GenSigTimeoutTime_Hybrid_PWR" SG_ 1408 MFN_Warmup_Cycle 5000;
BA_ "GenSigTimeoutMsg_Hybrid_PWR" SG_ 1408 MFN_Warmup_Cycle 1408;
BA_ "GenSigTimeoutTime_Hybrid_BMS" SG_ 1408 MFN_Warmup_Cycle 5000;
BA_ "GenSigTimeoutMsg_Hybrid_BMS" SG_ 1408 MFN_Warmup_Cycle 1408;
BA_ "GenSigTimeoutTime_DQ" SG_ 1408 MFN_Warmup_Cycle 5000;
BA_ "GenSigTimeoutMsg_DQ" SG_ 1408 MFN_Warmup_Cycle 1408;
BA_ "GenSigTimeoutTime_AG6" SG_ 1408 MFN_Warmup_Cycle 5000;
BA_ "GenSigTimeoutMsg_AG6" SG_ 1408 MFN_Warmup_Cycle 1408;
BA_ "GenSigTimeoutTime_Selespeed" SG_ 1408 MFN_Warmup_Cycle 5000;
BA_ "GenSigTimeoutMsg_Selespeed" SG_ 1408 MFN_Warmup_Cycle 1408;
BA_ "GenSigTimeoutTime_Gateway_PQ35_A" SG_ 1408 MFN_Warmup_Cycle 5000;
BA_ "GenSigTimeoutMsg_Gateway_PQ35_A" SG_ 1408 MFN_Warmup_Cycle 1408;
BA_ "GenSigTimeoutTime_TRW_ESP" SG_ 1408 MFN_Warmup_Cycle 5000;
BA_ "GenSigTimeoutMsg_TRW_ESP" SG_ 1408 MFN_Warmup_Cycle 1408;
BA_ "GenSigTimeoutTime_Gateway_PQ46_A" SG_ 1408 MFN_Warmup_Cycle 5000;
BA_ "GenSigTimeoutMsg_Gateway_PQ46_A" SG_ 1408 MFN_Warmup_Cycle 1408;
BA_ "GenSigSendType" SG_ 1408 MFN_Warmup_Cycle 0;
BA_ "GenSigTimeoutTime_TRW_ESP" SG_ 1408 MFN_Verschl 5000;
BA_ "GenSigTimeoutMsg_TRW_ESP" SG_ 1408 MFN_Verschl 1408;
BA_ "GenSigTimeoutTime_Gateway_PQ35_A" SG_ 1408 MFN_Verschl 5000;
BA_ "GenSigTimeoutMsg_Gateway_PQ35_A" SG_ 1408 MFN_Verschl 1408;
BA_ "GenSigTimeoutTime_Gateway_PQ46_A" SG_ 1408 MFN_Verschl 5000;
BA_ "GenSigTimeoutMsg_Gateway_PQ46_A" SG_ 1408 MFN_Verschl 1408;
BA_ "GenSigSendType" SG_ 1408 MFN_Verschl 0;
BA_ "GenSigTimeoutTime_TRW_ESP" SG_ 1408 MFN_Ventile 5000;
BA_ "GenSigTimeoutMsg_TRW_ESP" SG_ 1408 MFN_Ventile 1408;
BA_ "GenSigTimeoutTime_Gateway_PQ35_A" SG_ 1408 MFN_Ventile 5000;
BA_ "GenSigTimeoutMsg_Gateway_PQ35_A" SG_ 1408 MFN_Ventile 1408;
BA_ "GenSigTimeoutTime_Gateway_PQ46_A" SG_ 1408 MFN_Ventile 5000;
BA_ "GenSigTimeoutMsg_Gateway_PQ46_A" SG_ 1408 MFN_Ventile 1408;
BA_ "GenSigSendType" SG_ 1408 MFN_Ventile 0;
BA_ "INIT" SG_ 1408 MFN_Ventile "const";
BA_ "GenSigTimeoutTime_Hybrid_PWR" SG_ 1408 MFN_Drive_Cycle 5000;
BA_ "GenSigTimeoutMsg_Hybrid_PWR" SG_ 1408 MFN_Drive_Cycle 1408;
BA_ "GenSigTimeoutTime_Hybrid_BMS" SG_ 1408 MFN_Drive_Cycle 5000;
BA_ "GenSigTimeoutMsg_Hybrid_BMS" SG_ 1408 MFN_Drive_Cycle 1408;
BA_ "GenSigTimeoutTime_Selespeed" SG_ 1408 MFN_Drive_Cycle 5000;
BA_ "GenSigTimeoutMsg_Selespeed" SG_ 1408 MFN_Drive_Cycle 1408;
BA_ "GenSigTimeoutTime_DQ" SG_ 1408 MFN_Drive_Cycle 5000;
BA_ "GenSigTimeoutMsg_DQ" SG_ 1408 MFN_Drive_Cycle 1408;
BA_ "GenSigTimeoutTime_AG6" SG_ 1408 MFN_Drive_Cycle 5000;
BA_ "GenSigTimeoutMsg_AG6" SG_ 1408 MFN_Drive_Cycle 1408;
BA_ "GenSigTimeoutTime_TRW_ESP" SG_ 1408 MFN_Drive_Cycle 5000;
BA_ "GenSigTimeoutMsg_TRW_ESP" SG_ 1408 MFN_Drive_Cycle 1408;
BA_ "GenSigTimeoutTime_Gateway_PQ35_A" SG_ 1408 MFN_Drive_Cycle 5000;
BA_ "GenSigTimeoutMsg_Gateway_PQ35_A" SG_ 1408 MFN_Drive_Cycle 1408;
BA_ "GenSigTimeoutTime_Gateway_PQ46_A" SG_ 1408 MFN_Drive_Cycle 5000;
BA_ "GenSigTimeoutMsg_Gateway_PQ46_A" SG_ 1408 MFN_Drive_Cycle 1408;
BA_ "GenSigSendType" SG_ 1408 MFN_Drive_Cycle 0;
BA_ "GenSigTimeoutTime_TRW_ESP" SG_ 1408 MFN_Anz_Mittel 5000;
BA_ "GenSigTimeoutMsg_TRW_ESP" SG_ 1408 MFN_Anz_Mittel 1408;
BA_ "GenSigTimeoutTime_Gateway_PQ35_A" SG_ 1408 MFN_Anz_Mittel 5000;
BA_ "GenSigTimeoutMsg_Gateway_PQ35_A" SG_ 1408 MFN_Anz_Mittel 1408;
BA_ "GenSigTimeoutTime_Gateway_PQ46_A" SG_ 1408 MFN_Anz_Mittel 5000;
BA_ "GenSigTimeoutMsg_Gateway_PQ46_A" SG_ 1408 MFN_Anz_Mittel 1408;
BA_ "GenSigSendType" SG_ 1408 MFN_Anz_Mittel 0;
BA_ "INIT" SG_ 1408 MFN_Anz_Mittel "const";
BA_ "GenSigTimeoutTime_TRW_ESP" SG_ 1408 MFN_Oelwarnung 5000;
BA_ "GenSigTimeoutMsg_TRW_ESP" SG_ 1408 MFN_Oelwarnung 1408;
BA_ "GenSigTimeoutTime_Gateway_PQ35_A" SG_ 1408 MFN_Oelwarnung 5000;
BA_ "GenSigTimeoutMsg_Gateway_PQ35_A" SG_ 1408 MFN_Oelwarnung 1408;
BA_ "GenSigTimeoutTime_Gateway_PQ46_A" SG_ 1408 MFN_Oelwarnung 5000;
BA_ "GenSigTimeoutMsg_Gateway_PQ46_A" SG_ 1408 MFN_Oelwarnung 1408;
BA_ "GenSigSendType" SG_ 1408 MFN_Oelwarnung 0;
BA_ "GenSigTimeoutTime_TRW_ESP" SG_ 1408 MFN_Interv_tmax 5000;
BA_ "GenSigTimeoutMsg_TRW_ESP" SG_ 1408 MFN_Interv_tmax 1408;
BA_ "GenSigTimeoutTime_Gateway_PQ35_A" SG_ 1408 MFN_Interv_tmax 5000;
BA_ "GenSigTimeoutMsg_Gateway_PQ35_A" SG_ 1408 MFN_Interv_tmax 1408;
BA_ "GenSigTimeoutTime_Gateway_PQ46_A" SG_ 1408 MFN_Interv_tmax 5000;
BA_ "GenSigTimeoutMsg_Gateway_PQ46_A" SG_ 1408 MFN_Interv_tmax 1408;
BA_ "GenSigSendType" SG_ 1408 MFN_Interv_tmax 0;
BA_ "INIT" SG_ 1408 MFN_Interv_tmax "const";
BA_ "GenSigTimeoutTime_TRW_ESP" SG_ 1408 MFN_Interv_Wmax 5000;
BA_ "GenSigTimeoutMsg_TRW_ESP" SG_ 1408 MFN_Interv_Wmax 1408;
BA_ "GenSigTimeoutTime_Gateway_PQ35_A" SG_ 1408 MFN_Interv_Wmax 5000;
BA_ "GenSigTimeoutMsg_Gateway_PQ35_A" SG_ 1408 MFN_Interv_Wmax 1408;
BA_ "GenSigTimeoutTime_Gateway_PQ46_A" SG_ 1408 MFN_Interv_Wmax 5000;
BA_ "GenSigTimeoutMsg_Gateway_PQ46_A" SG_ 1408 MFN_Interv_Wmax 1408;
BA_ "GenSigSendType" SG_ 1408 MFN_Interv_Wmax 0;
BA_ "INIT" SG_ 1408 MFN_Interv_Wmax "const";
BA_ "GenSigTimeoutTime_TRW_ESP" SG_ 1408 MFN_Sensorwarn 5000;
BA_ "GenSigTimeoutMsg_TRW_ESP" SG_ 1408 MFN_Sensorwarn 1408;
BA_ "GenSigTimeoutTime_Gateway_PQ35_A" SG_ 1408 MFN_Sensorwarn 5000;
BA_ "GenSigTimeoutMsg_Gateway_PQ35_A" SG_ 1408 MFN_Sensorwarn 1408;
BA_ "GenSigTimeoutTime_Gateway_PQ46_A" SG_ 1408 MFN_Sensorwarn 5000;
BA_ "GenSigTimeoutMsg_Gateway_PQ46_A" SG_ 1408 MFN_Sensorwarn 1408;
BA_ "GenSigSendType" SG_ 1408 MFN_Sensorwarn 0;
BA_ "GenSigTimeoutTime_TRW_ESP" SG_ 1408 MFN_MaxOelst 5000;
BA_ "GenSigTimeoutMsg_TRW_ESP" SG_ 1408 MFN_MaxOelst 1408;
BA_ "GenSigTimeoutTime_Gateway_PQ35_A" SG_ 1408 MFN_MaxOelst 5000;
BA_ "GenSigTimeoutMsg_Gateway_PQ35_A" SG_ 1408 MFN_MaxOelst 1408;
BA_ "GenSigTimeoutTime_Gateway_PQ46_A" SG_ 1408 MFN_MaxOelst 5000;
BA_ "GenSigTimeoutMsg_Gateway_PQ46_A" SG_ 1408 MFN_MaxOelst 1408;
BA_ "GenSigSendType" SG_ 1408 MFN_MaxOelst 0;
BA_ "INIT" SG_ 1408 MFN_MaxOelst "const";
BA_ "GenSigTimeoutTime_TRW_ESP" SG_ 1408 MFN_Interv_Wmin 5000;
BA_ "GenSigTimeoutMsg_TRW_ESP" SG_ 1408 MFN_Interv_Wmin 1408;
BA_ "GenSigTimeoutTime_Gateway_PQ35_A" SG_ 1408 MFN_Interv_Wmin 5000;
BA_ "GenSigTimeoutMsg_Gateway_PQ35_A" SG_ 1408 MFN_Interv_Wmin 1408;
BA_ "GenSigTimeoutTime_Gateway_PQ46_A" SG_ 1408 MFN_Interv_Wmin 5000;
BA_ "GenSigTimeoutMsg_Gateway_PQ46_A" SG_ 1408 MFN_Interv_Wmin 1408;
BA_ "GenSigSendType" SG_ 1408 MFN_Interv_Wmin 0;
BA_ "INIT" SG_ 1408 MFN_Interv_Wmin "const";
BA_ "GenSigTimeoutTime_TRW_ESP" SG_ 1408 MFN_Drz_max_Mo_ 5000;
BA_ "GenSigTimeoutMsg_TRW_ESP" SG_ 1408 MFN_Drz_max_Mo_ 1408;
BA_ "GenSigTimeoutTime_Gateway_PQ35_A" SG_ 1408 MFN_Drz_max_Mo_ 5000;
BA_ "GenSigTimeoutMsg_Gateway_PQ35_A" SG_ 1408 MFN_Drz_max_Mo_ 1408;
BA_ "GenSigTimeoutTime_Gateway_PQ46_A" SG_ 1408 MFN_Drz_max_Mo_ 5000;
BA_ "GenSigTimeoutMsg_Gateway_PQ46_A" SG_ 1408 MFN_Drz_max_Mo_ 1408;
BA_ "GenSigSendType" SG_ 1408 MFN_Drz_max_Mo_ 0;
BA_ "INIT" SG_ 1408 MFN_Drz_max_Mo_ "const";
BA_ "GenSigTimeoutTime_TRW_ESP" SG_ 1408 MFN_Interv_tmin 5000;
BA_ "GenSigTimeoutMsg_TRW_ESP" SG_ 1408 MFN_Interv_tmin 1408;
BA_ "GenSigTimeoutTime_Gateway_PQ35_A" SG_ 1408 MFN_Interv_tmin 5000;
BA_ "GenSigTimeoutMsg_Gateway_PQ35_A" SG_ 1408 MFN_Interv_tmin 1408;
BA_ "GenSigTimeoutTime_Gateway_PQ46_A" SG_ 1408 MFN_Interv_tmin 5000;
BA_ "GenSigTimeoutMsg_Gateway_PQ46_A" SG_ 1408 MFN_Interv_tmin 1408;
BA_ "GenSigSendType" SG_ 1408 MFN_Interv_tmin 0;
BA_ "INIT" SG_ 1408 MFN_Interv_tmin "const";
BA_ "GenSigTimeoutTime_TRW_ESP" SG_ 1408 MFN_Str_Mittel 5000;
BA_ "GenSigTimeoutMsg_TRW_ESP" SG_ 1408 MFN_Str_Mittel 1408;
BA_ "GenSigTimeoutTime_Gateway_PQ35_A" SG_ 1408 MFN_Str_Mittel 5000;
BA_ "GenSigTimeoutMsg_Gateway_PQ35_A" SG_ 1408 MFN_Str_Mittel 1408;
BA_ "GenSigTimeoutTime_Gateway_PQ46_A" SG_ 1408 MFN_Str_Mittel 5000;
BA_ "GenSigTimeoutMsg_Gateway_PQ46_A" SG_ 1408 MFN_Str_Mittel 1408;
BA_ "GenSigSendType" SG_ 1408 MFN_Str_Mittel 0;
BA_ "INIT" SG_ 1408 MFN_Str_Mittel "const";
BA_ "GenSigTimeoutTime_TRW_ESP" SG_ 1408 MFN_Fuell_Erk 5000;
BA_ "GenSigTimeoutMsg_TRW_ESP" SG_ 1408 MFN_Fuell_Erk 1408;
BA_ "GenSigTimeoutTime_Gateway_PQ35_A" SG_ 1408 MFN_Fuell_Erk 5000;
BA_ "GenSigTimeoutMsg_Gateway_PQ35_A" SG_ 1408 MFN_Fuell_Erk 1408;
BA_ "GenSigTimeoutTime_Gateway_PQ46_A" SG_ 1408 MFN_Fuell_Erk 5000;
BA_ "GenSigTimeoutMsg_Gateway_PQ46_A" SG_ 1408 MFN_Fuell_Erk 1408;
BA_ "GenSigSendType" SG_ 1408 MFN_Fuell_Erk 0;
BA_ "INIT" SG_ 1408 MFN_Fuell_Erk "const";
BA_ "GenSigTimeoutTime_EPB" SG_ 1408 MFN_Hubraum_ 5000;
BA_ "GenSigTimeoutMsg_EPB" SG_ 1408 MFN_Hubraum_ 1408;
BA_ "GenSigTimeoutTime_Gateway_PQ35_A" SG_ 1408 MFN_Hubraum_ 5000;
BA_ "GenSigTimeoutMsg_Gateway_PQ35_A" SG_ 1408 MFN_Hubraum_ 1408;
BA_ "GenSigTimeoutTime_TRW_ESP" SG_ 1408 MFN_Hubraum_ 5000;
BA_ "GenSigTimeoutMsg_TRW_ESP" SG_ 1408 MFN_Hubraum_ 1408;
BA_ "GenSigTimeoutTime_Gateway_PQ46_A" SG_ 1408 MFN_Hubraum_ 5000;
BA_ "GenSigTimeoutMsg_Gateway_PQ46_A" SG_ 1408 MFN_Hubraum_ 1408;
BA_ "GenSigSendType" SG_ 1408 MFN_Hubraum_ 0;
BA_ "INIT" SG_ 1408 MFN_Hubraum_ "const";
BA_ "GenSigTimeoutTime_Gateway_PQ35_A" SG_ 1408 MFN_Ansaugsys_ 5000;
BA_ "GenSigTimeoutMsg_Gateway_PQ35_A" SG_ 1408 MFN_Ansaugsys_ 1408;
BA_ "GenSigTimeoutTime_TRW_ESP" SG_ 1408 MFN_Ansaugsys_ 5000;
BA_ "GenSigTimeoutMsg_TRW_ESP" SG_ 1408 MFN_Ansaugsys_ 1408;
BA_ "GenSigTimeoutTime_Gateway_PQ46_A" SG_ 1408 MFN_Ansaugsys_ 5000;
BA_ "GenSigTimeoutMsg_Gateway_PQ46_A" SG_ 1408 MFN_Ansaugsys_ 1408;
BA_ "GenSigSendType" SG_ 1408 MFN_Ansaugsys_ 0;
BA_ "INIT" SG_ 1408 MFN_Ansaugsys_ "const";
BA_ "GenSigTimeoutTime_TRW_ESP" SG_ 1408 MFN_max_Moment_ 5000;
BA_ "GenSigTimeoutMsg_TRW_ESP" SG_ 1408 MFN_max_Moment_ 1408;
BA_ "GenSigTimeoutTime_Gateway_PQ35_A" SG_ 1408 MFN_max_Moment_ 5000;
BA_ "GenSigTimeoutMsg_Gateway_PQ35_A" SG_ 1408 MFN_max_Moment_ 1408;
BA_ "GenSigTimeoutTime_Gateway_PQ46_A" SG_ 1408 MFN_max_Moment_ 5000;
BA_ "GenSigTimeoutMsg_Gateway_PQ46_A" SG_ 1408 MFN_max_Moment_ 1408;
BA_ "GenSigSendType" SG_ 1408 MFN_max_Moment_ 0;
BA_ "INIT" SG_ 1408 MFN_max_Moment_ "const";
BA_ "GenSigTimeoutTime_ACC_Lidar" SG_ 1408 MFN_Motorleistung_ 5000;
BA_ "GenSigTimeoutMsg_ACC_Lidar" SG_ 1408 MFN_Motorleistung_ 1408;
BA_ "GenSigTimeoutTime_EPB" SG_ 1408 MFN_Motorleistung_ 5000;
BA_ "GenSigTimeoutMsg_EPB" SG_ 1408 MFN_Motorleistung_ 1408;
BA_ "GenSigTimeoutTime_Gateway_PQ35_A" SG_ 1408 MFN_Motorleistung_ 5000;
BA_ "GenSigTimeoutMsg_Gateway_PQ35_A" SG_ 1408 MFN_Motorleistung_ 1408;
BA_ "GenSigTimeoutTime_ACC_Radar" SG_ 1408 MFN_Motorleistung_ 5000;
BA_ "GenSigTimeoutMsg_ACC_Radar" SG_ 1408 MFN_Motorleistung_ 1408;
BA_ "GenSigTimeoutTime_TRW_ESP" SG_ 1408 MFN_Motorleistung_ 5000;
BA_ "GenSigTimeoutMsg_TRW_ESP" SG_ 1408 MFN_Motorleistung_ 1408;
BA_ "GenSigTimeoutTime_Gateway_PQ46_A" SG_ 1408 MFN_Motorleistung_ 5000;
BA_ "GenSigTimeoutMsg_Gateway_PQ46_A" SG_ 1408 MFN_Motorleistung_ 1408;
BA_ "GenSigSendType" SG_ 1408 MFN_Motorleistung_ 0;
BA_ "INIT" SG_ 1408 MFN_Motorleistung_ "const";
BA_ "GenSigTimeoutTime_TRW_ESP" SG_ 1408 MFN_Zylinder_ 5000;
BA_ "GenSigTimeoutMsg_TRW_ESP" SG_ 1408 MFN_Zylinder_ 1408;
BA_ "GenSigTimeoutTime_Gateway_PQ35_A" SG_ 1408 MFN_Zylinder_ 5000;
BA_ "GenSigTimeoutMsg_Gateway_PQ35_A" SG_ 1408 MFN_Zylinder_ 1408;
BA_ "GenSigTimeoutTime_Gateway_PQ46_A" SG_ 1408 MFN_Zylinder_ 5000;
BA_ "GenSigTimeoutMsg_Gateway_PQ46_A" SG_ 1408 MFN_Zylinder_ 1408;
BA_ "GenSigSendType" SG_ 1408 MFN_Zylinder_ 0;
BA_ "INIT" SG_ 1408 MFN_Zylinder_ "const";
BA_ "GenSigTimeoutTime_TRW_ESP" SG_ 1408 MFN_Ventile_ 5000;
BA_ "GenSigTimeoutMsg_TRW_ESP" SG_ 1408 MFN_Ventile_ 1408;
BA_ "GenSigTimeoutTime_Gateway_PQ35_A" SG_ 1408 MFN_Ventile_ 5000;
BA_ "GenSigTimeoutMsg_Gateway_PQ35_A" SG_ 1408 MFN_Ventile_ 1408;
BA_ "GenSigTimeoutTime_Gateway_PQ46_A" SG_ 1408 MFN_Ventile_ 5000;
BA_ "GenSigTimeoutMsg_Gateway_PQ46_A" SG_ 1408 MFN_Ventile_ 1408;
BA_ "GenSigSendType" SG_ 1408 MFN_Ventile_ 0;
BA_ "INIT" SG_ 1408 MFN_Ventile_ "const";
BA_ "GenSigTimeoutTime_TRW_ESP" SG_ 1408 MFN_Russindex_ 5000;
BA_ "GenSigTimeoutMsg_TRW_ESP" SG_ 1408 MFN_Russindex_ 1408;
BA_ "GenSigTimeoutTime_Gateway_PQ35_A" SG_ 1408 MFN_Russindex_ 5000;
BA_ "GenSigTimeoutMsg_Gateway_PQ35_A" SG_ 1408 MFN_Russindex_ 1408;
BA_ "GenSigTimeoutTime_Gateway_PQ46_A" SG_ 1408 MFN_Russindex_ 5000;
BA_ "GenSigTimeoutMsg_Gateway_PQ46_A" SG_ 1408 MFN_Russindex_ 1408;
BA_ "GenSigSendType" SG_ 1408 MFN_Russindex_ 0;
BA_ "GenSigTimeoutTime_TRW_ESP" SG_ 1408 MFN_Fuell_Hyst 5000;
BA_ "GenSigTimeoutMsg_TRW_ESP" SG_ 1408 MFN_Fuell_Hyst 1408;
BA_ "GenSigTimeoutTime_Gateway_PQ35_A" SG_ 1408 MFN_Fuell_Hyst 5000;
BA_ "GenSigTimeoutMsg_Gateway_PQ35_A" SG_ 1408 MFN_Fuell_Hyst 1408;
BA_ "GenSigTimeoutTime_Gateway_PQ46_A" SG_ 1408 MFN_Fuell_Hyst 5000;
BA_ "GenSigTimeoutMsg_Gateway_PQ46_A" SG_ 1408 MFN_Fuell_Hyst 1408;
BA_ "GenSigSendType" SG_ 1408 MFN_Fuell_Hyst 0;
BA_ "INIT" SG_ 1408 MFN_Fuell_Hyst "const";
BA_ "GenSigTimeoutTime_EPB" SG_ 1408 MFN_Zaehler_ 5000;
BA_ "GenSigTimeoutMsg_EPB" SG_ 1408 MFN_Zaehler_ 1408;
BA_ "GenSigTimeoutTime_Gateway_PQ35_A" SG_ 1408 MFN_Zaehler_ 5000;
BA_ "GenSigTimeoutMsg_Gateway_PQ35_A" SG_ 1408 MFN_Zaehler_ 1408;
BA_ "GenSigTimeoutTime_TRW_ESP" SG_ 1408 MFN_Zaehler_ 5000;
BA_ "GenSigTimeoutMsg_TRW_ESP" SG_ 1408 MFN_Zaehler_ 1408;
BA_ "GenSigTimeoutTime_Gateway_PQ46_A" SG_ 1408 MFN_Zaehler_ 5000;
BA_ "GenSigTimeoutMsg_Gateway_PQ46_A" SG_ 1408 MFN_Zaehler_ 1408;
BA_ "GenSigSendType" SG_ 1408 MFN_Zaehler_ 0;
BA_ "GenSigTimeoutTime_TRW_ESP" SG_ 1408 MFN_Verschl_ 5000;
BA_ "GenSigTimeoutMsg_TRW_ESP" SG_ 1408 MFN_Verschl_ 1408;
BA_ "GenSigTimeoutTime_Gateway_PQ35_A" SG_ 1408 MFN_Verschl_ 5000;
BA_ "GenSigTimeoutMsg_Gateway_PQ35_A" SG_ 1408 MFN_Verschl_ 1408;
BA_ "GenSigTimeoutTime_Gateway_PQ46_A" SG_ 1408 MFN_Verschl_ 5000;
BA_ "GenSigTimeoutMsg_Gateway_PQ46_A" SG_ 1408 MFN_Verschl_ 1408;
BA_ "GenSigSendType" SG_ 1408 MFN_Verschl_ 0;
BA_ "GenSigTimeoutTime_Hybrid_DQ200" SG_ 1160 MO6_Hoeheninfo 500;
BA_ "GenSigTimeoutMsg_Hybrid_DQ200" SG_ 1160 MO6_Hoeheninfo 1160;
BA_ "GenSigTimeoutTime_DQ" SG_ 1160 MO6_Hoeheninfo 500;
BA_ "GenSigTimeoutMsg_DQ" SG_ 1160 MO6_Hoeheninfo 1160;
BA_ "GenSigSendType" SG_ 1160 MO6_Hoeheninfo 0;
BA_ "GenSigTimeoutTime_Selespeed" SG_ 1160 MO6_SollM_Getr 500;
BA_ "GenSigTimeoutMsg_Selespeed" SG_ 1160 MO6_SollM_Getr 1160;
BA_ "GenSigSendType" SG_ 1160 MO6_SollM_Getr 0;
BA_ "GenSigSendType" SG_ 1160 MO6_Checksum 0;
BA_ "INIT" SG_ 1160 MO6_Checksum "CHK";
BA_ "GenSigTimeoutTime_Hybrid_DQ200" SG_ 1160 MO6_GRA_Soll 500;
BA_ "GenSigTimeoutMsg_Hybrid_DQ200" SG_ 1160 MO6_GRA_Soll 1160;
BA_ "GenSigTimeoutTime_DQ" SG_ 1160 MO6_GRA_Soll 500;
BA_ "GenSigTimeoutMsg_DQ" SG_ 1160 MO6_GRA_Soll 1160;
BA_ "GenSigTimeoutTime_AG6" SG_ 1160 MO6_GRA_Soll 500;
BA_ "GenSigTimeoutMsg_AG6" SG_ 1160 MO6_GRA_Soll 1160;
BA_ "GenSigSendType" SG_ 1160 MO6_GRA_Soll 0;
BA_ "GenSigStartValue" SG_ 1160 MO6_GRA_Soll 166;
BA_ "GenSigTimeoutTime_Hybrid_DQ200" SG_ 1160 MO6_MomIntGeEing 500;
BA_ "GenSigTimeoutMsg_Hybrid_DQ200" SG_ 1160 MO6_MomIntGeEing 1160;
BA_ "GenSigTimeoutTime_DQ" SG_ 1160 MO6_MomIntGeEing 500;
BA_ "GenSigTimeoutMsg_DQ" SG_ 1160 MO6_MomIntGeEing 1160;
BA_ "GenSigSendType" SG_ 1160 MO6_MomIntGeEing 0;
BA_ "GenSigSendType" SG_ 1160 MO6_Freigabe_GRA 0;
BA_ "GenSigSendType" SG_ 1160 MO6_Schutz_Toel 0;
BA_ "GenSigTimeoutTime_Gateway_PQ46_A" SG_ 1160 MO6_Ist_Moment 500;
BA_ "GenSigTimeoutMsg_Gateway_PQ46_A" SG_ 1160 MO6_Ist_Moment 1160;
BA_ "GenSigTimeoutTime_Gateway_PQ35_A" SG_ 1160 MO6_Ist_Moment 500;
BA_ "GenSigTimeoutMsg_Gateway_PQ35_A" SG_ 1160 MO6_Ist_Moment 1160;
BA_ "GenSigTimeoutTime_Selespeed" SG_ 1160 MO6_Ist_Moment 500;
BA_ "GenSigTimeoutMsg_Selespeed" SG_ 1160 MO6_Ist_Moment 1160;
BA_ "GenSigTimeoutTime_Hybrid_DQ200" SG_ 1160 MO6_Ist_Moment 500;
BA_ "GenSigTimeoutMsg_Hybrid_DQ200" SG_ 1160 MO6_Ist_Moment 1160;
BA_ "GenSigTimeoutTime_DQ" SG_ 1160 MO6_Ist_Moment 500;
BA_ "GenSigTimeoutMsg_DQ" SG_ 1160 MO6_Ist_Moment 1160;
BA_ "GenSigTimeoutTime_AG6" SG_ 1160 MO6_Ist_Moment 500;
BA_ "GenSigTimeoutMsg_AG6" SG_ 1160 MO6_Ist_Moment 1160;
BA_ "GenSigSendType" SG_ 1160 MO6_Ist_Moment 0;
BA_ "GenSigTimeoutTime_Hybrid_DQ200" SG_ 1160 MO6_RegPartikel 500;
BA_ "GenSigTimeoutMsg_Hybrid_DQ200" SG_ 1160 MO6_RegPartikel 1160;
BA_ "GenSigTimeoutTime_DQ" SG_ 1160 MO6_RegPartikel 500;
BA_ "GenSigTimeoutMsg_DQ" SG_ 1160 MO6_RegPartikel 1160;
BA_ "GenSigTimeoutTime_AG6" SG_ 1160 MO6_RegPartikel 500;
BA_ "GenSigTimeoutMsg_AG6" SG_ 1160 MO6_RegPartikel 1160;
BA_ "GenSigSendType" SG_ 1160 MO6_RegPartikel 0;
BA_ "GenSigSendType" SG_ 1160 MO6_Luftpfad_akt 0;
BA_ "GenSigTimeoutTime_Hybrid_PWR" SG_ 1160 MO6_FF_Mux00 500;
BA_ "GenSigTimeoutMsg_Hybrid_PWR" SG_ 1160 MO6_FF_Mux00 1160;
BA_ "GenSigTimeoutTime_Selespeed" SG_ 1160 MO6_FF_Mux00 500;
BA_ "GenSigTimeoutMsg_Selespeed" SG_ 1160 MO6_FF_Mux00 1160;
BA_ "GenSigSendType" SG_ 1160 MO6_FF_Mux00 0;
BA_ "GenSigStartValue" SG_ 1160 MO6_FF_Mux00 255;
BA_ "GenSigTimeoutTime_Hybrid_PWR" SG_ 1160 MO6_FF_Mux01 500;
BA_ "GenSigTimeoutMsg_Hybrid_PWR" SG_ 1160 MO6_FF_Mux01 1160;
BA_ "GenSigTimeoutTime_Selespeed" SG_ 1160 MO6_FF_Mux01 500;
BA_ "GenSigTimeoutMsg_Selespeed" SG_ 1160 MO6_FF_Mux01 1160;
BA_ "GenSigSendType" SG_ 1160 MO6_FF_Mux01 0;
BA_ "GenSigStartValue" SG_ 1160 MO6_FF_Mux01 255;
BA_ "GenSigTimeoutTime_Hybrid_PWR" SG_ 1160 MO6_FF_Mux02 500;
BA_ "GenSigTimeoutMsg_Hybrid_PWR" SG_ 1160 MO6_FF_Mux02 1160;
BA_ "GenSigTimeoutTime_Selespeed" SG_ 1160 MO6_FF_Mux02 500;
BA_ "GenSigTimeoutMsg_Selespeed" SG_ 1160 MO6_FF_Mux02 1160;
BA_ "GenSigSendType" SG_ 1160 MO6_FF_Mux02 0;
BA_ "GenSigStartValue" SG_ 1160 MO6_FF_Mux02 255;
BA_ "GenSigTimeoutTime_Hybrid_PWR" SG_ 1160 MO6_FF_Mux03 500;
BA_ "GenSigTimeoutMsg_Hybrid_PWR" SG_ 1160 MO6_FF_Mux03 1160;
BA_ "GenSigTimeoutTime_Selespeed" SG_ 1160 MO6_FF_Mux03 500;
BA_ "GenSigTimeoutMsg_Selespeed" SG_ 1160 MO6_FF_Mux03 1160;
BA_ "GenSigSendType" SG_ 1160 MO6_FF_Mux03 0;
BA_ "GenSigStartValue" SG_ 1160 MO6_FF_Mux03 255;
BA_ "GenSigTimeoutTime_Hybrid_PWR" SG_ 1160 MO6_Zaehler 500;
BA_ "GenSigTimeoutMsg_Hybrid_PWR" SG_ 1160 MO6_Zaehler 1160;
BA_ "GenSigTimeoutTime_Selespeed" SG_ 1160 MO6_Zaehler 500;
BA_ "GenSigTimeoutMsg_Selespeed" SG_ 1160 MO6_Zaehler 1160;
BA_ "GenSigTimeoutTime_Hybrid_DQ200" SG_ 1160 MO6_Zaehler 500;
BA_ "GenSigTimeoutMsg_Hybrid_DQ200" SG_ 1160 MO6_Zaehler 1160;
BA_ "GenSigTimeoutTime_DQ" SG_ 1160 MO6_Zaehler 500;
BA_ "GenSigTimeoutMsg_DQ" SG_ 1160 MO6_Zaehler 1160;
BA_ "GenSigSendType" SG_ 1160 MO6_Zaehler 0;
BA_ "GenSigTimeoutTime_Selespeed" SG_ 1160 MO6_FF_Mux05 500;
BA_ "GenSigTimeoutMsg_Selespeed" SG_ 1160 MO6_FF_Mux05 1160;
BA_ "GenSigSendType" SG_ 1160 MO6_FF_Mux05 0;
BA_ "GenSigStartValue" SG_ 1160 MO6_FF_Mux05 255;
BA_ "GenSigTimeoutTime_Selespeed" SG_ 1160 MO6_FF_Mux06 500;
BA_ "GenSigTimeoutMsg_Selespeed" SG_ 1160 MO6_FF_Mux06 1160;
BA_ "GenSigSendType" SG_ 1160 MO6_FF_Mux06 0;
BA_ "GenSigStartValue" SG_ 1160 MO6_FF_Mux06 255;
BA_ "GenSigTimeoutTime_Hybrid_PWR" SG_ 1160 MO6_FF_Mux04 500;
BA_ "GenSigTimeoutMsg_Hybrid_PWR" SG_ 1160 MO6_FF_Mux04 1160;
BA_ "GenSigTimeoutTime_Selespeed" SG_ 1160 MO6_FF_Mux04 500;
BA_ "GenSigTimeoutMsg_Selespeed" SG_ 1160 MO6_FF_Mux04 1160;
BA_ "GenSigSendType" SG_ 1160 MO6_FF_Mux04 0;
BA_ "GenSigStartValue" SG_ 1160 MO6_FF_Mux04 255;
BA_ "GenSigTimeoutTime_Selespeed" SG_ 1160 MO6_FF_Mux08 500;
BA_ "GenSigTimeoutMsg_Selespeed" SG_ 1160 MO6_FF_Mux08 1160;
BA_ "GenSigSendType" SG_ 1160 MO6_FF_Mux08 0;
BA_ "GenSigStartValue" SG_ 1160 MO6_FF_Mux08 255;
BA_ "GenSigTimeoutTime_Selespeed" SG_ 1160 MO6_FF_Mux07 500;
BA_ "GenSigTimeoutMsg_Selespeed" SG_ 1160 MO6_FF_Mux07 1160;
BA_ "GenSigSendType" SG_ 1160 MO6_FF_Mux07 0;
BA_ "GenSigStartValue" SG_ 1160 MO6_FF_Mux07 255;
BA_ "GenSigTimeoutTime_Selespeed" SG_ 1160 MO6_FF_Mux09 500;
BA_ "GenSigTimeoutMsg_Selespeed" SG_ 1160 MO6_FF_Mux09 1160;
BA_ "GenSigSendType" SG_ 1160 MO6_FF_Mux09 0;
BA_ "GenSigStartValue" SG_ 1160 MO6_FF_Mux09 255;
BA_ "GenSigTimeoutTime_Selespeed" SG_ 1160 MO6_FF_Mux10 500;
BA_ "GenSigTimeoutMsg_Selespeed" SG_ 1160 MO6_FF_Mux10 1160;
BA_ "GenSigSendType" SG_ 1160 MO6_FF_Mux10 0;
BA_ "GenSigStartValue" SG_ 1160 MO6_FF_Mux10 255;
BA_ "GenSigTimeoutTime_Selespeed" SG_ 1160 MO6_FF_Mux11 500;
BA_ "GenSigTimeoutMsg_Selespeed" SG_ 1160 MO6_FF_Mux11 1160;
BA_ "GenSigSendType" SG_ 1160 MO6_FF_Mux11 0;
BA_ "GenSigStartValue" SG_ 1160 MO6_FF_Mux11 255;
BA_ "GenSigTimeoutTime_Selespeed" SG_ 1160 MO6_FF_Mux12 500;
BA_ "GenSigTimeoutMsg_Selespeed" SG_ 1160 MO6_FF_Mux12 1160;
BA_ "GenSigSendType" SG_ 1160 MO6_FF_Mux12 0;
BA_ "GenSigStartValue" SG_ 1160 MO6_FF_Mux12 255;
BA_ "GenSigTimeoutTime_Selespeed" SG_ 1160 MO6_FF_Mux14 500;
BA_ "GenSigTimeoutMsg_Selespeed" SG_ 1160 MO6_FF_Mux14 1160;
BA_ "GenSigSendType" SG_ 1160 MO6_FF_Mux14 0;
BA_ "GenSigStartValue" SG_ 1160 MO6_FF_Mux14 255;
BA_ "GenSigTimeoutTime_Selespeed" SG_ 1160 MO6_FF_Mux13 500;
BA_ "GenSigTimeoutMsg_Selespeed" SG_ 1160 MO6_FF_Mux13 1160;
BA_ "GenSigSendType" SG_ 1160 MO6_FF_Mux13 0;
BA_ "GenSigStartValue" SG_ 1160 MO6_FF_Mux13 255;
BA_ "GenSigTimeoutTime_Selespeed" SG_ 1160 MO6_FF_Mux15 500;
BA_ "GenSigTimeoutMsg_Selespeed" SG_ 1160 MO6_FF_Mux15 1160;
BA_ "GenSigSendType" SG_ 1160 MO6_FF_Mux15 0;
BA_ "GenSigStartValue" SG_ 1160 MO6_FF_Mux15 255;
BA_ "GenSigTimeoutTime_Teves_MK70_MAB" SG_ 1152 MO5_max_Moment 500;
BA_ "GenSigTimeoutMsg_Teves_MK70_MAB" SG_ 1152 MO5_max_Moment 1152;
BA_ "GenSigTimeoutTime_Teves_MK60_ESP" SG_ 1152 MO5_max_Moment 500;
BA_ "GenSigTimeoutMsg_Teves_MK60_ESP" SG_ 1152 MO5_max_Moment 1152;
BA_ "GenSigTimeoutTime_Gateway_PQ35_A" SG_ 1152 MO5_max_Moment 500;
BA_ "GenSigTimeoutMsg_Gateway_PQ35_A" SG_ 1152 MO5_max_Moment 1152;
BA_ "GenSigTimeoutTime_Gateway_PQ46_A" SG_ 1152 MO5_max_Moment 500;
BA_ "GenSigTimeoutMsg_Gateway_PQ46_A" SG_ 1152 MO5_max_Moment 1152;
BA_ "GenSigSendType" SG_ 1152 MO5_max_Moment 0;
BA_ "INIT" SG_ 1152 MO5_max_Moment "const";
BA_ "GenSigTimeoutTime_Teves_MK60_ESP" SG_ 1152 MO5_res_08 500;
BA_ "GenSigTimeoutMsg_Teves_MK60_ESP" SG_ 1152 MO5_res_08 1152;
BA_ "GenSigTimeoutTime_Teves_MK70_MAB" SG_ 1152 MO5_res_08 500;
BA_ "GenSigTimeoutMsg_Teves_MK70_MAB" SG_ 1152 MO5_res_08 1152;
BA_ "GenSigTimeoutTime_Gateway_PQ35_A" SG_ 1152 MO5_res_08 500;
BA_ "GenSigTimeoutMsg_Gateway_PQ35_A" SG_ 1152 MO5_res_08 1152;
BA_ "GenSigTimeoutTime_Gateway_PQ46_A" SG_ 1152 MO5_res_08 500;
BA_ "GenSigTimeoutMsg_Gateway_PQ46_A" SG_ 1152 MO5_res_08 1152;
BA_ "GenSigSendType" SG_ 1152 MO5_res_08 0;
BA_ "GenSigTimeoutTime_Teves_MK70_MAB" SG_ 1152 MO5_Mp_Code 500;
BA_ "GenSigTimeoutMsg_Teves_MK70_MAB" SG_ 1152 MO5_Mp_Code 1152;
BA_ "GenSigTimeoutTime_Gateway_PQ35_A" SG_ 1152 MO5_Mp_Code 500;
BA_ "GenSigTimeoutMsg_Gateway_PQ35_A" SG_ 1152 MO5_Mp_Code 1152;
BA_ "GenSigTimeoutTime_Teves_MK60_ESP" SG_ 1152 MO5_Mp_Code 500;
BA_ "GenSigTimeoutMsg_Teves_MK60_ESP" SG_ 1152 MO5_Mp_Code 1152;
BA_ "GenSigTimeoutTime_Allrad" SG_ 1152 MO5_Mp_Code 500;
BA_ "GenSigTimeoutMsg_Allrad" SG_ 1152 MO5_Mp_Code 1152;
BA_ "GenSigTimeoutTime_Gateway_PQ46_A" SG_ 1152 MO5_Mp_Code 500;
BA_ "GenSigTimeoutMsg_Gateway_PQ46_A" SG_ 1152 MO5_Mp_Code 1152;
BA_ "GenSigSendType" SG_ 1152 MO5_Mp_Code 0;
BA_ "GenSigTimeoutTime_Teves_MK70_MAB" SG_ 1152 MO5_Vorgluehen 500;
BA_ "GenSigTimeoutMsg_Teves_MK70_MAB" SG_ 1152 MO5_Vorgluehen 1152;
BA_ "GenSigTimeoutTime_Teves_MK60_ESP" SG_ 1152 MO5_Vorgluehen 500;
BA_ "GenSigTimeoutMsg_Teves_MK60_ESP" SG_ 1152 MO5_Vorgluehen 1152;
BA_ "GenSigTimeoutTime_Gateway_PQ35_A" SG_ 1152 MO5_Vorgluehen 500;
BA_ "GenSigTimeoutMsg_Gateway_PQ35_A" SG_ 1152 MO5_Vorgluehen 1152;
BA_ "GenSigTimeoutTime_Gateway_PQ46_A" SG_ 1152 MO5_Vorgluehen 500;
BA_ "GenSigTimeoutMsg_Gateway_PQ46_A" SG_ 1152 MO5_Vorgluehen 1152;
BA_ "GenSigSendType" SG_ 1152 MO5_Vorgluehen 0;
BA_ "GenSigTimeoutTime_Teves_MK70_MAB" SG_ 1152 MO5_E_Gas 500;
BA_ "GenSigTimeoutMsg_Teves_MK70_MAB" SG_ 1152 MO5_E_Gas 1152;
BA_ "GenSigTimeoutTime_Teves_MK60_ESP" SG_ 1152 MO5_E_Gas 500;
BA_ "GenSigTimeoutMsg_Teves_MK60_ESP" SG_ 1152 MO5_E_Gas 1152;
BA_ "GenSigTimeoutTime_Gateway_PQ35_A" SG_ 1152 MO5_E_Gas 500;
BA_ "GenSigTimeoutMsg_Gateway_PQ35_A" SG_ 1152 MO5_E_Gas 1152;
BA_ "GenSigTimeoutTime_Gateway_PQ46_A" SG_ 1152 MO5_E_Gas 500;
BA_ "GenSigTimeoutMsg_Gateway_PQ46_A" SG_ 1152 MO5_E_Gas 1152;
BA_ "GenSigSendType" SG_ 1152 MO5_E_Gas 0;
BA_ "GenSigTimeoutTime_Teves_MK70_MAB" SG_ 1152 MO5_OBD_2 500;
BA_ "GenSigTimeoutMsg_Teves_MK70_MAB" SG_ 1152 MO5_OBD_2 1152;
BA_ "GenSigTimeoutTime_Teves_MK60_ESP" SG_ 1152 MO5_OBD_2 500;
BA_ "GenSigTimeoutMsg_Teves_MK60_ESP" SG_ 1152 MO5_OBD_2 1152;
BA_ "GenSigTimeoutTime_Gateway_PQ35_A" SG_ 1152 MO5_OBD_2 500;
BA_ "GenSigTimeoutMsg_Gateway_PQ35_A" SG_ 1152 MO5_OBD_2 1152;
BA_ "GenSigTimeoutTime_Gateway_PQ46_A" SG_ 1152 MO5_OBD_2 500;
BA_ "GenSigTimeoutMsg_Gateway_PQ46_A" SG_ 1152 MO5_OBD_2 1152;
BA_ "GenSigSendType" SG_ 1152 MO5_OBD_2 0;
BA_ "GenSigTimeoutTime_Teves_MK70_MAB" SG_ 1152 MO5_KliKo_Red 500;
BA_ "GenSigTimeoutMsg_Teves_MK70_MAB" SG_ 1152 MO5_KliKo_Red 1152;
BA_ "GenSigTimeoutTime_Teves_MK60_ESP" SG_ 1152 MO5_KliKo_Red 500;
BA_ "GenSigTimeoutMsg_Teves_MK60_ESP" SG_ 1152 MO5_KliKo_Red 1152;
BA_ "GenSigTimeoutTime_Gateway_PQ35_A" SG_ 1152 MO5_KliKo_Red 500;
BA_ "GenSigTimeoutMsg_Gateway_PQ35_A" SG_ 1152 MO5_KliKo_Red 1152;
BA_ "GenSigTimeoutTime_Gateway_PQ46_A" SG_ 1152 MO5_KliKo_Red 500;
BA_ "GenSigTimeoutMsg_Gateway_PQ46_A" SG_ 1152 MO5_KliKo_Red 1152;
BA_ "GenSigSendType" SG_ 1152 MO5_KliKo_Red 0;
BA_ "GenSigTimeoutTime_Teves_MK70_MAB" SG_ 1152 MO5_Heissl 500;
BA_ "GenSigTimeoutMsg_Teves_MK70_MAB" SG_ 1152 MO5_Heissl 1152;
BA_ "GenSigTimeoutTime_Teves_MK60_ESP" SG_ 1152 MO5_Heissl 500;
BA_ "GenSigTimeoutMsg_Teves_MK60_ESP" SG_ 1152 MO5_Heissl 1152;
BA_ "GenSigTimeoutTime_Gateway_PQ35_A" SG_ 1152 MO5_Heissl 500;
BA_ "GenSigTimeoutMsg_Gateway_PQ35_A" SG_ 1152 MO5_Heissl 1152;
BA_ "GenSigTimeoutTime_Gateway_PQ46_A" SG_ 1152 MO5_Heissl 500;
BA_ "GenSigTimeoutMsg_Gateway_PQ46_A" SG_ 1152 MO5_Heissl 1152;
BA_ "GenSigSendType" SG_ 1152 MO5_Heissl 0;
BA_ "GenSigTimeoutTime_EKlimakomp" SG_ 1152 MO5_KlimaKompr 500;
BA_ "GenSigTimeoutMsg_EKlimakomp" SG_ 1152 MO5_KlimaKompr 1152;
BA_ "GenSigTimeoutTime_Teves_MK70_MAB" SG_ 1152 MO5_KlimaKompr 500;
BA_ "GenSigTimeoutMsg_Teves_MK70_MAB" SG_ 1152 MO5_KlimaKompr 1152;
BA_ "GenSigTimeoutTime_Teves_MK60_ESP" SG_ 1152 MO5_KlimaKompr 500;
BA_ "GenSigTimeoutMsg_Teves_MK60_ESP" SG_ 1152 MO5_KlimaKompr 1152;
BA_ "GenSigTimeoutTime_Gateway_PQ35_A" SG_ 1152 MO5_KlimaKompr 500;
BA_ "GenSigTimeoutMsg_Gateway_PQ35_A" SG_ 1152 MO5_KlimaKompr 1152;
BA_ "GenSigTimeoutTime_Gateway_PQ46_A" SG_ 1152 MO5_KlimaKompr 500;
BA_ "GenSigTimeoutMsg_Gateway_PQ46_A" SG_ 1152 MO5_KlimaKompr 1152;
BA_ "GenSigSendType" SG_ 1152 MO5_KlimaKompr 0;
BA_ "GenSigTimeoutTime_Teves_MK70_MAB" SG_ 1152 MO5_Feld_kuehl 500;
BA_ "GenSigTimeoutMsg_Teves_MK70_MAB" SG_ 1152 MO5_Feld_kuehl 1152;
BA_ "GenSigTimeoutTime_Teves_MK60_ESP" SG_ 1152 MO5_Feld_kuehl 500;
BA_ "GenSigTimeoutMsg_Teves_MK60_ESP" SG_ 1152 MO5_Feld_kuehl 1152;
BA_ "GenSigTimeoutTime_Gateway_PQ35_A" SG_ 1152 MO5_Feld_kuehl 500;
BA_ "GenSigTimeoutMsg_Gateway_PQ35_A" SG_ 1152 MO5_Feld_kuehl 1152;
BA_ "GenSigTimeoutTime_Gateway_PQ46_A" SG_ 1152 MO5_Feld_kuehl 500;
BA_ "GenSigTimeoutMsg_Gateway_PQ46_A" SG_ 1152 MO5_Feld_kuehl 1152;
BA_ "GenSigSendType" SG_ 1152 MO5_Feld_kuehl 0;
BA_ "INIT" SG_ 1152 MO5_Feld_kuehl "const";
BA_ "GenSigTimeoutTime_Teves_MK70_MAB" SG_ 1152 MO5_Verbrauch 500;
BA_ "GenSigTimeoutMsg_Teves_MK70_MAB" SG_ 1152 MO5_Verbrauch 1152;
BA_ "GenSigTimeoutTime_Teves_MK60_ESP" SG_ 1152 MO5_Verbrauch 500;
BA_ "GenSigTimeoutMsg_Teves_MK60_ESP" SG_ 1152 MO5_Verbrauch 1152;
BA_ "GenSigTimeoutTime_Gateway_PQ35_A" SG_ 1152 MO5_Verbrauch 500;
BA_ "GenSigTimeoutMsg_Gateway_PQ35_A" SG_ 1152 MO5_Verbrauch 1152;
BA_ "GenSigTimeoutTime_Gateway_PQ46_A" SG_ 1152 MO5_Verbrauch 500;
BA_ "GenSigTimeoutMsg_Gateway_PQ46_A" SG_ 1152 MO5_Verbrauch 1152;
BA_ "GenSigSendType" SG_ 1152 MO5_Verbrauch 0;
BA_ "GenSigTimeoutTime_Teves_MK70_MAB" SG_ 1152 MO5_UeberlVerb 500;
BA_ "GenSigTimeoutMsg_Teves_MK70_MAB" SG_ 1152 MO5_UeberlVerb 1152;
BA_ "GenSigTimeoutTime_Teves_MK60_ESP" SG_ 1152 MO5_UeberlVerb 500;
BA_ "GenSigTimeoutMsg_Teves_MK60_ESP" SG_ 1152 MO5_UeberlVerb 1152;
BA_ "GenSigTimeoutTime_Gateway_PQ35_A" SG_ 1152 MO5_UeberlVerb 500;
BA_ "GenSigTimeoutMsg_Gateway_PQ35_A" SG_ 1152 MO5_UeberlVerb 1152;
BA_ "GenSigTimeoutTime_Gateway_PQ46_A" SG_ 1152 MO5_UeberlVerb 500;
BA_ "GenSigTimeoutMsg_Gateway_PQ46_A" SG_ 1152 MO5_UeberlVerb 1152;
BA_ "GenSigSendType" SG_ 1152 MO5_UeberlVerb 0;
BA_ "GenSigTimeoutTime_DQ" SG_ 1152 MO5_Momente 500;
BA_ "GenSigTimeoutMsg_DQ" SG_ 1152 MO5_Momente 1152;
BA_ "GenSigTimeoutTime_RKA_Plus" SG_ 1152 MO5_Momente 500;
BA_ "GenSigTimeoutMsg_RKA_Plus" SG_ 1152 MO5_Momente 1152;
BA_ "GenSigTimeoutTime_Selespeed" SG_ 1152 MO5_Momente 500;
BA_ "GenSigTimeoutMsg_Selespeed" SG_ 1152 MO5_Momente 1152;
BA_ "GenSigTimeoutTime_Gateway_PQ35_A" SG_ 1152 MO5_Momente 500;
BA_ "GenSigTimeoutMsg_Gateway_PQ35_A" SG_ 1152 MO5_Momente 1152;
BA_ "GenSigTimeoutTime_Teves_MK70_MAB" SG_ 1152 MO5_Momente 500;
BA_ "GenSigTimeoutMsg_Teves_MK70_MAB" SG_ 1152 MO5_Momente 1152;
BA_ "GenSigTimeoutTime_Teves_MK60_ESP" SG_ 1152 MO5_Momente 500;
BA_ "GenSigTimeoutMsg_Teves_MK60_ESP" SG_ 1152 MO5_Momente 1152;
BA_ "GenSigTimeoutTime_Gateway_PQ46_A" SG_ 1152 MO5_Momente 500;
BA_ "GenSigTimeoutMsg_Gateway_PQ46_A" SG_ 1152 MO5_Momente 1152;
BA_ "GenSigTimeoutTime_AG6" SG_ 1152 MO5_Momente 500;
BA_ "GenSigTimeoutMsg_AG6" SG_ 1152 MO5_Momente 1152;
BA_ "GenSigSendType" SG_ 1152 MO5_Momente 0;
BA_ "INIT" SG_ 1152 MO5_Momente "const";
BA_ "GenSigTimeoutTime_DQ" SG_ 1152 MO5_Luefter 500;
BA_ "GenSigTimeoutMsg_DQ" SG_ 1152 MO5_Luefter 1152;
BA_ "GenSigTimeoutTime_Teves_MK70_MAB" SG_ 1152 MO5_Luefter 500;
BA_ "GenSigTimeoutMsg_Teves_MK70_MAB" SG_ 1152 MO5_Luefter 1152;
BA_ "GenSigTimeoutTime_Teves_MK60_ESP" SG_ 1152 MO5_Luefter 500;
BA_ "GenSigTimeoutMsg_Teves_MK60_ESP" SG_ 1152 MO5_Luefter 1152;
BA_ "GenSigTimeoutTime_Gateway_PQ35_A" SG_ 1152 MO5_Luefter 500;
BA_ "GenSigTimeoutMsg_Gateway_PQ35_A" SG_ 1152 MO5_Luefter 1152;
BA_ "GenSigTimeoutTime_Gateway_PQ46_A" SG_ 1152 MO5_Luefter 500;
BA_ "GenSigTimeoutMsg_Gateway_PQ46_A" SG_ 1152 MO5_Luefter 1152;
BA_ "GenSigSendType" SG_ 1152 MO5_Luefter 0;
BA_ "GenSigTimeoutTime_Teves_MK70_MAB" SG_ 1152 MO5_Checksumme 500;
BA_ "GenSigTimeoutMsg_Teves_MK70_MAB" SG_ 1152 MO5_Checksumme 1152;
BA_ "GenSigTimeoutTime_Teves_MK60_ESP" SG_ 1152 MO5_Checksumme 500;
BA_ "GenSigTimeoutMsg_Teves_MK60_ESP" SG_ 1152 MO5_Checksumme 1152;
BA_ "GenSigTimeoutTime_Gateway_PQ35_A" SG_ 1152 MO5_Checksumme 500;
BA_ "GenSigTimeoutMsg_Gateway_PQ35_A" SG_ 1152 MO5_Checksumme 1152;
BA_ "GenSigTimeoutTime_Gateway_PQ46_A" SG_ 1152 MO5_Checksumme 500;
BA_ "GenSigTimeoutMsg_Gateway_PQ46_A" SG_ 1152 MO5_Checksumme 1152;
BA_ "GenSigSendType" SG_ 1152 MO5_Checksumme 0;
BA_ "INIT" SG_ 1152 MO5_Checksumme "CHK";
BA_ "GenSigTimeoutTime_Teves_MK70_MAB" SG_ 1152 MO5_Start 500;
BA_ "GenSigTimeoutMsg_Teves_MK70_MAB" SG_ 1152 MO5_Start 1152;
BA_ "GenSigTimeoutTime_Teves_MK60_ESP" SG_ 1152 MO5_Start 500;
BA_ "GenSigTimeoutMsg_Teves_MK60_ESP" SG_ 1152 MO5_Start 1152;
BA_ "GenSigTimeoutTime_Gateway_PQ35_A" SG_ 1152 MO5_Start 500;
BA_ "GenSigTimeoutMsg_Gateway_PQ35_A" SG_ 1152 MO5_Start 1152;
BA_ "GenSigTimeoutTime_Gateway_PQ46_A" SG_ 1152 MO5_Start 500;
BA_ "GenSigTimeoutMsg_Gateway_PQ46_A" SG_ 1152 MO5_Start 1152;
BA_ "GenSigSendType" SG_ 1152 MO5_Start 0;
BA_ "GenSigTimeoutTime_Teves_MK70_MAB" SG_ 1152 MO5_HLeuchte 500;
BA_ "GenSigTimeoutMsg_Teves_MK70_MAB" SG_ 1152 MO5_HLeuchte 1152;
BA_ "GenSigTimeoutTime_Teves_MK60_ESP" SG_ 1152 MO5_HLeuchte 500;
BA_ "GenSigTimeoutMsg_Teves_MK60_ESP" SG_ 1152 MO5_HLeuchte 1152;
BA_ "GenSigTimeoutTime_Gateway_PQ35_A" SG_ 1152 MO5_HLeuchte 500;
BA_ "GenSigTimeoutMsg_Gateway_PQ35_A" SG_ 1152 MO5_HLeuchte 1152;
BA_ "GenSigTimeoutTime_Gateway_PQ46_A" SG_ 1152 MO5_HLeuchte 500;
BA_ "GenSigTimeoutMsg_Gateway_PQ46_A" SG_ 1152 MO5_HLeuchte 1152;
BA_ "GenSigSendType" SG_ 1152 MO5_HLeuchte 0;
BA_ "GenSigTimeoutTime_Teves_MK70_MAB" SG_ 1152 MO5_Anlasser 500;
BA_ "GenSigTimeoutMsg_Teves_MK70_MAB" SG_ 1152 MO5_Anlasser 1152;
BA_ "GenSigTimeoutTime_Teves_MK60_ESP" SG_ 1152 MO5_Anlasser 500;
BA_ "GenSigTimeoutMsg_Teves_MK60_ESP" SG_ 1152 MO5_Anlasser 1152;
BA_ "GenSigTimeoutTime_Gateway_PQ35_A" SG_ 1152 MO5_Anlasser 500;
BA_ "GenSigTimeoutMsg_Gateway_PQ35_A" SG_ 1152 MO5_Anlasser 1152;
BA_ "GenSigTimeoutTime_Gateway_PQ46_A" SG_ 1152 MO5_Anlasser 500;
BA_ "GenSigTimeoutMsg_Gateway_PQ46_A" SG_ 1152 MO5_Anlasser 1152;
BA_ "GenSigSendType" SG_ 1152 MO5_Anlasser 0;
BA_ "GenSigTimeoutTime_Teves_MK70_MAB" SG_ 1152 MO5_Motortext1 500;
BA_ "GenSigTimeoutMsg_Teves_MK70_MAB" SG_ 1152 MO5_Motortext1 1152;
BA_ "GenSigTimeoutTime_Teves_MK60_ESP" SG_ 1152 MO5_Motortext1 500;
BA_ "GenSigTimeoutMsg_Teves_MK60_ESP" SG_ 1152 MO5_Motortext1 1152;
BA_ "GenSigTimeoutTime_Gateway_PQ35_A" SG_ 1152 MO5_Motortext1 500;
BA_ "GenSigTimeoutMsg_Gateway_PQ35_A" SG_ 1152 MO5_Motortext1 1152;
BA_ "GenSigTimeoutTime_Gateway_PQ46_A" SG_ 1152 MO5_Motortext1 500;
BA_ "GenSigTimeoutMsg_Gateway_PQ46_A" SG_ 1152 MO5_Motortext1 1152;
BA_ "GenSigSendType" SG_ 1152 MO5_Motortext1 0;
BA_ "GenSigTimeoutTime_Teves_MK70_MAB" SG_ 1152 MO5_GRA_Hauptsch 500;
BA_ "GenSigTimeoutMsg_Teves_MK70_MAB" SG_ 1152 MO5_GRA_Hauptsch 1152;
BA_ "GenSigTimeoutTime_Teves_MK60_ESP" SG_ 1152 MO5_GRA_Hauptsch 500;
BA_ "GenSigTimeoutMsg_Teves_MK60_ESP" SG_ 1152 MO5_GRA_Hauptsch 1152;
BA_ "GenSigTimeoutTime_ACC_Lidar" SG_ 1152 MO5_GRA_Hauptsch 500;
BA_ "GenSigTimeoutMsg_ACC_Lidar" SG_ 1152 MO5_GRA_Hauptsch 1152;
BA_ "GenSigTimeoutTime_Gateway_PQ35_A" SG_ 1152 MO5_GRA_Hauptsch 500;
BA_ "GenSigTimeoutMsg_Gateway_PQ35_A" SG_ 1152 MO5_GRA_Hauptsch 1152;
BA_ "GenSigTimeoutTime_ACC_Radar" SG_ 1152 MO5_GRA_Hauptsch 500;
BA_ "GenSigTimeoutMsg_ACC_Radar" SG_ 1152 MO5_GRA_Hauptsch 1152;
BA_ "GenSigTimeoutTime_Gateway_PQ46_A" SG_ 1152 MO5_GRA_Hauptsch 500;
BA_ "GenSigTimeoutMsg_Gateway_PQ46_A" SG_ 1152 MO5_GRA_Hauptsch 1152;
BA_ "GenSigSendType" SG_ 1152 MO5_GRA_Hauptsch 0;
BA_ "GenSigTimeoutTime_Teves_MK70_MAB" SG_ 1152 MO5_Interlock 500;
BA_ "GenSigTimeoutMsg_Teves_MK70_MAB" SG_ 1152 MO5_Interlock 1152;
BA_ "GenSigTimeoutTime_Teves_MK60_ESP" SG_ 1152 MO5_Interlock 500;
BA_ "GenSigTimeoutMsg_Teves_MK60_ESP" SG_ 1152 MO5_Interlock 1152;
BA_ "GenSigTimeoutTime_Gateway_PQ35_A" SG_ 1152 MO5_Interlock 500;
BA_ "GenSigTimeoutMsg_Gateway_PQ35_A" SG_ 1152 MO5_Interlock 1152;
BA_ "GenSigTimeoutTime_Gateway_PQ46_A" SG_ 1152 MO5_Interlock 500;
BA_ "GenSigTimeoutMsg_Gateway_PQ46_A" SG_ 1152 MO5_Interlock 1152;
BA_ "GenSigSendType" SG_ 1152 MO5_Interlock 0;
BA_ "GenSigTimeoutTime_Teves_MK70_MAB" SG_ 1152 MO5_Motortyp 500;
BA_ "GenSigTimeoutMsg_Teves_MK70_MAB" SG_ 1152 MO5_Motortyp 1152;
BA_ "GenSigTimeoutTime_Teves_MK60_ESP" SG_ 1152 MO5_Motortyp 500;
BA_ "GenSigTimeoutMsg_Teves_MK60_ESP" SG_ 1152 MO5_Motortyp 1152;
BA_ "GenSigTimeoutTime_Gateway_PQ35_A" SG_ 1152 MO5_Motortyp 500;
BA_ "GenSigTimeoutMsg_Gateway_PQ35_A" SG_ 1152 MO5_Motortyp 1152;
BA_ "GenSigTimeoutTime_Allrad" SG_ 1152 MO5_Motortyp 500;
BA_ "GenSigTimeoutMsg_Allrad" SG_ 1152 MO5_Motortyp 1152;
BA_ "GenSigTimeoutTime_Gateway_PQ46_A" SG_ 1152 MO5_Motortyp 500;
BA_ "GenSigTimeoutMsg_Gateway_PQ46_A" SG_ 1152 MO5_Motortyp 1152;
BA_ "GenSigSendType" SG_ 1152 MO5_Motortyp 0;
BA_ "INIT" SG_ 1152 MO5_Motortyp "const";
BA_ "GenSigTimeoutTime_Teves_MK60_ESP" SG_ 1152 MO5_Sta_BKU 500;
BA_ "GenSigTimeoutMsg_Teves_MK60_ESP" SG_ 1152 MO5_Sta_BKU 1152;
BA_ "GenSigTimeoutTime_Teves_MK70_MAB" SG_ 1152 MO5_Sta_BKU 500;
BA_ "GenSigTimeoutMsg_Teves_MK70_MAB" SG_ 1152 MO5_Sta_BKU 1152;
BA_ "GenSigTimeoutTime_Gateway_PQ35_A" SG_ 1152 MO5_Sta_BKU 500;
BA_ "GenSigTimeoutMsg_Gateway_PQ35_A" SG_ 1152 MO5_Sta_BKU 1152;
BA_ "GenSigTimeoutTime_Gateway_PQ46_A" SG_ 1152 MO5_Sta_BKU 500;
BA_ "GenSigTimeoutMsg_Gateway_PQ46_A" SG_ 1152 MO5_Sta_BKU 1152;
BA_ "GenSigSendType" SG_ 1152 MO5_Sta_BKU 0;
BA_ "GenSigTimeoutTime_Teves_MK70_MAB" SG_ 1152 MO5_Drehzahl 500;
BA_ "GenSigTimeoutMsg_Teves_MK70_MAB" SG_ 1152 MO5_Drehzahl 1152;
BA_ "GenSigTimeoutTime_Teves_MK60_ESP" SG_ 1152 MO5_Drehzahl 500;
BA_ "GenSigTimeoutMsg_Teves_MK60_ESP" SG_ 1152 MO5_Drehzahl 1152;
BA_ "GenSigTimeoutTime_Gateway_PQ35_A" SG_ 1152 MO5_Drehzahl 500;
BA_ "GenSigTimeoutMsg_Gateway_PQ35_A" SG_ 1152 MO5_Drehzahl 1152;
BA_ "GenSigTimeoutTime_Gateway_PQ46_A" SG_ 1152 MO5_Drehzahl 500;
BA_ "GenSigTimeoutMsg_Gateway_PQ46_A" SG_ 1152 MO5_Drehzahl 1152;
BA_ "GenSigSendType" SG_ 1152 MO5_Drehzahl 0;
BA_ "INIT" SG_ 1152 MO5_Drehzahl "const";
BA_ "GenSigTimeoutTime_Teves_MK70_MAB" SG_ 1152 MO5_TypStartSteu 500;
BA_ "GenSigTimeoutMsg_Teves_MK70_MAB" SG_ 1152 MO5_TypStartSteu 1152;
BA_ "GenSigTimeoutTime_Teves_MK60_ESP" SG_ 1152 MO5_TypStartSteu 500;
BA_ "GenSigTimeoutMsg_Teves_MK60_ESP" SG_ 1152 MO5_TypStartSteu 1152;
BA_ "GenSigTimeoutTime_Gateway_PQ35_A" SG_ 1152 MO5_TypStartSteu 500;
BA_ "GenSigTimeoutMsg_Gateway_PQ35_A" SG_ 1152 MO5_TypStartSteu 1152;
BA_ "GenSigTimeoutTime_Gateway_PQ46_A" SG_ 1152 MO5_TypStartSteu 500;
BA_ "GenSigTimeoutMsg_Gateway_PQ46_A" SG_ 1152 MO5_TypStartSteu 1152;
BA_ "GenSigSendType" SG_ 1152 MO5_TypStartSteu 0;
BA_ "GenSigTimeoutTime_Teves_MK70_MAB" SG_ 1152 MO5_PartikelLamp 500;
BA_ "GenSigTimeoutMsg_Teves_MK70_MAB" SG_ 1152 MO5_PartikelLamp 1152;
BA_ "GenSigTimeoutTime_Teves_MK60_ESP" SG_ 1152 MO5_PartikelLamp 500;
BA_ "GenSigTimeoutMsg_Teves_MK60_ESP" SG_ 1152 MO5_PartikelLamp 1152;
BA_ "GenSigTimeoutTime_Gateway_PQ35_A" SG_ 1152 MO5_PartikelLamp 500;
BA_ "GenSigTimeoutMsg_Gateway_PQ35_A" SG_ 1152 MO5_PartikelLamp 1152;
BA_ "GenSigTimeoutTime_Gateway_PQ46_A" SG_ 1152 MO5_PartikelLamp 500;
BA_ "GenSigTimeoutMsg_Gateway_PQ46_A" SG_ 1152 MO5_PartikelLamp 1152;
BA_ "GenSigSendType" SG_ 1152 MO5_PartikelLamp 0;
BA_ "GenSigTimeoutTime_Teves_MK70_MAB" SG_ 1152 MO5_Motortext4 500;
BA_ "GenSigTimeoutMsg_Teves_MK70_MAB" SG_ 1152 MO5_Motortext4 1152;
BA_ "GenSigTimeoutTime_Teves_MK60_ESP" SG_ 1152 MO5_Motortext4 500;
BA_ "GenSigTimeoutMsg_Teves_MK60_ESP" SG_ 1152 MO5_Motortext4 1152;
BA_ "GenSigTimeoutTime_Gateway_PQ35_A" SG_ 1152 MO5_Motortext4 500;
BA_ "GenSigTimeoutMsg_Gateway_PQ35_A" SG_ 1152 MO5_Motortext4 1152;
BA_ "GenSigTimeoutTime_Gateway_PQ46_A" SG_ 1152 MO5_Motortext4 500;
BA_ "GenSigTimeoutMsg_Gateway_PQ46_A" SG_ 1152 MO5_Motortext4 1152;
BA_ "GenSigSendType" SG_ 1152 MO5_Motortext4 0;
BA_ "GenSigTimeoutTime_Teves_MK70_MAB" SG_ 1152 MO5_TDE_Text 500;
BA_ "GenSigTimeoutMsg_Teves_MK70_MAB" SG_ 1152 MO5_TDE_Text 1152;
BA_ "GenSigTimeoutTime_Teves_MK60_ESP" SG_ 1152 MO5_TDE_Text 500;
BA_ "GenSigTimeoutMsg_Teves_MK60_ESP" SG_ 1152 MO5_TDE_Text 1152;
BA_ "GenSigTimeoutTime_Gateway_PQ35_A" SG_ 1152 MO5_TDE_Text 500;
BA_ "GenSigTimeoutMsg_Gateway_PQ35_A" SG_ 1152 MO5_TDE_Text 1152;
BA_ "GenSigTimeoutTime_Gateway_PQ46_A" SG_ 1152 MO5_TDE_Text 500;
BA_ "GenSigTimeoutMsg_Gateway_PQ46_A" SG_ 1152 MO5_TDE_Text 1152;
BA_ "GenSigSendType" SG_ 1152 MO5_TDE_Text 0;
BA_ "GenSigTimeoutTime_Teves_MK70_MAB" SG_ 1152 MO5_Motortext3 500;
BA_ "GenSigTimeoutMsg_Teves_MK70_MAB" SG_ 1152 MO5_Motortext3 1152;
BA_ "GenSigTimeoutTime_Teves_MK60_ESP" SG_ 1152 MO5_Motortext3 500;
BA_ "GenSigTimeoutMsg_Teves_MK60_ESP" SG_ 1152 MO5_Motortext3 1152;
BA_ "GenSigTimeoutTime_Gateway_PQ35_A" SG_ 1152 MO5_Motortext3 500;
BA_ "GenSigTimeoutMsg_Gateway_PQ35_A" SG_ 1152 MO5_Motortext3 1152;
BA_ "GenSigTimeoutTime_Gateway_PQ46_A" SG_ 1152 MO5_Motortext3 500;
BA_ "GenSigTimeoutMsg_Gateway_PQ46_A" SG_ 1152 MO5_Motortext3 1152;
BA_ "GenSigSendType" SG_ 1152 MO5_Motortext3 0;
BA_ "GenSigTimeoutTime_Teves_MK60_ESP" SG_ 1152 MO5_Motortext2 500;
BA_ "GenSigTimeoutMsg_Teves_MK60_ESP" SG_ 1152 MO5_Motortext2 1152;
BA_ "GenSigTimeoutTime_Teves_MK70_MAB" SG_ 1152 MO5_Motortext2 500;
BA_ "GenSigTimeoutMsg_Teves_MK70_MAB" SG_ 1152 MO5_Motortext2 1152;
BA_ "GenSigTimeoutTime_Gateway_PQ35_A" SG_ 1152 MO5_Motortext2 500;
BA_ "GenSigTimeoutMsg_Gateway_PQ35_A" SG_ 1152 MO5_Motortext2 1152;
BA_ "GenSigTimeoutTime_Gateway_PQ46_A" SG_ 1152 MO5_Motortext2 500;
BA_ "GenSigTimeoutMsg_Gateway_PQ46_A" SG_ 1152 MO5_Motortext2 1152;
BA_ "GenSigSendType" SG_ 1152 MO5_Motortext2 0;
BA_ "GenSigTimeoutTime_Teves_MK70_MAB" SG_ 1152 MO5_Abgastyp2 500;
BA_ "GenSigTimeoutMsg_Teves_MK70_MAB" SG_ 1152 MO5_Abgastyp2 1152;
BA_ "GenSigTimeoutTime_Teves_MK60_ESP" SG_ 1152 MO5_Abgastyp2 500;
BA_ "GenSigTimeoutMsg_Teves_MK60_ESP" SG_ 1152 MO5_Abgastyp2 1152;
BA_ "GenSigTimeoutTime_Gateway_PQ35_A" SG_ 1152 MO5_Abgastyp2 500;
BA_ "GenSigTimeoutMsg_Gateway_PQ35_A" SG_ 1152 MO5_Abgastyp2 1152;
BA_ "GenSigTimeoutTime_Gateway_PQ46_A" SG_ 1152 MO5_Abgastyp2 500;
BA_ "GenSigTimeoutMsg_Gateway_PQ46_A" SG_ 1152 MO5_Abgastyp2 1152;
BA_ "GenSigSendType" SG_ 1152 MO5_Abgastyp2 0;
BA_ "INIT" SG_ 1152 MO5_Abgastyp2 "const";
BA_ "GenSigTimeoutTime_Teves_MK70_MAB" SG_ 1152 MO5_TDE_Lampe 500;
BA_ "GenSigTimeoutMsg_Teves_MK70_MAB" SG_ 1152 MO5_TDE_Lampe 1152;
BA_ "GenSigTimeoutTime_Teves_MK60_ESP" SG_ 1152 MO5_TDE_Lampe 500;
BA_ "GenSigTimeoutMsg_Teves_MK60_ESP" SG_ 1152 MO5_TDE_Lampe 1152;
BA_ "GenSigTimeoutTime_Gateway_PQ35_A" SG_ 1152 MO5_TDE_Lampe 500;
BA_ "GenSigTimeoutMsg_Gateway_PQ35_A" SG_ 1152 MO5_TDE_Lampe 1152;
BA_ "GenSigTimeoutTime_Gateway_PQ46_A" SG_ 1152 MO5_TDE_Lampe 500;
BA_ "GenSigTimeoutMsg_Gateway_PQ46_A" SG_ 1152 MO5_TDE_Lampe 1152;
BA_ "GenSigSendType" SG_ 1152 MO5_TDE_Lampe 0;
BA_ "GenSigTimeoutTime_Gateway_PQ35_A" SG_ 1152 MO5_Abgastyp 500;
BA_ "GenSigTimeoutMsg_Gateway_PQ35_A" SG_ 1152 MO5_Abgastyp 1152;
BA_ "GenSigTimeoutTime_Gateway_PQ46_A" SG_ 1152 MO5_Abgastyp 500;
BA_ "GenSigTimeoutMsg_Gateway_PQ46_A" SG_ 1152 MO5_Abgastyp 1152;
BA_ "GenSigSendType" SG_ 1152 MO5_Abgastyp 0;
BA_ "INIT" SG_ 1152 MO5_Abgastyp "const";
BA_ "GenSigTimeoutTime_Teves_MK70_MAB" SG_ 1152 MO5_DZM_Daempf 500;
BA_ "GenSigTimeoutMsg_Teves_MK70_MAB" SG_ 1152 MO5_DZM_Daempf 1152;
BA_ "GenSigTimeoutTime_Teves_MK60_ESP" SG_ 1152 MO5_DZM_Daempf 500;
BA_ "GenSigTimeoutMsg_Teves_MK60_ESP" SG_ 1152 MO5_DZM_Daempf 1152;
BA_ "GenSigTimeoutTime_Gateway_PQ35_A" SG_ 1152 MO5_DZM_Daempf 500;
BA_ "GenSigTimeoutMsg_Gateway_PQ35_A" SG_ 1152 MO5_DZM_Daempf 1152;
BA_ "GenSigTimeoutTime_Gateway_PQ46_A" SG_ 1152 MO5_DZM_Daempf 500;
BA_ "GenSigTimeoutMsg_Gateway_PQ46_A" SG_ 1152 MO5_DZM_Daempf 1152;
BA_ "GenSigSendType" SG_ 1152 MO5_DZM_Daempf 0;
BA_ "GenSigTimeoutTime_Teves_MK70_MAB" SG_ 1152 MO5_Abgastyp3 500;
BA_ "GenSigTimeoutMsg_Teves_MK70_MAB" SG_ 1152 MO5_Abgastyp3 1152;
BA_ "GenSigTimeoutTime_Teves_MK60_ESP" SG_ 1152 MO5_Abgastyp3 500;
BA_ "GenSigTimeoutMsg_Teves_MK60_ESP" SG_ 1152 MO5_Abgastyp3 1152;
BA_ "GenSigTimeoutTime_Gateway_PQ46_A" SG_ 1152 MO5_Abgastyp3 500;
BA_ "GenSigTimeoutMsg_Gateway_PQ46_A" SG_ 1152 MO5_Abgastyp3 1152;
BA_ "GenSigTimeoutTime_Gateway_PQ35_A" SG_ 1152 MO5_Abgastyp3 500;
BA_ "GenSigTimeoutMsg_Gateway_PQ35_A" SG_ 1152 MO5_Abgastyp3 1152;
BA_ "GenSigSendType" SG_ 1152 MO5_Abgastyp3 0;
BA_ "INIT" SG_ 1152 MO5_Abgastyp3 "const";
BA_ "GenSigTimeoutTime_Teves_MK70_MAB" SG_ 1152 MO5_DPF_reg 500;
BA_ "GenSigTimeoutMsg_Teves_MK70_MAB" SG_ 1152 MO5_DPF_reg 1152;
BA_ "GenSigTimeoutTime_Teves_MK60_ESP" SG_ 1152 MO5_DPF_reg 500;
BA_ "GenSigTimeoutMsg_Teves_MK60_ESP" SG_ 1152 MO5_DPF_reg 1152;
BA_ "GenSigTimeoutTime_Gateway_PQ46_A" SG_ 1152 MO5_DPF_reg 500;
BA_ "GenSigTimeoutMsg_Gateway_PQ46_A" SG_ 1152 MO5_DPF_reg 1152;
BA_ "GenSigTimeoutTime_Gateway_PQ35_A" SG_ 1152 MO5_DPF_reg 500;
BA_ "GenSigTimeoutMsg_Gateway_PQ35_A" SG_ 1152 MO5_DPF_reg 1152;
BA_ "GenSigSendType" SG_ 1152 MO5_DPF_reg 0;
BA_ "GenSigTimeoutTime_Hybrid_DQ200" SG_ 640 MO1_Leergas 500;
BA_ "GenSigTimeoutMsg_Hybrid_DQ200" SG_ 640 MO1_Leergas 640;
BA_ "GenSigTimeoutTime_Gateway_PQ35_A" SG_ 640 MO1_Leergas 500;
BA_ "GenSigTimeoutMsg_Gateway_PQ35_A" SG_ 640 MO1_Leergas 640;
BA_ "GenSigTimeoutTime_TRW_ESP" SG_ 640 MO1_Leergas 500;
BA_ "GenSigTimeoutMsg_TRW_ESP" SG_ 640 MO1_Leergas 640;
BA_ "GenSigTimeoutTime_DQ" SG_ 640 MO1_Leergas 500;
BA_ "GenSigTimeoutMsg_DQ" SG_ 640 MO1_Leergas 640;
BA_ "GenSigTimeoutTime_Teves_MK70_MAB" SG_ 640 MO1_Leergas 500;
BA_ "GenSigTimeoutMsg_Teves_MK70_MAB" SG_ 640 MO1_Leergas 640;
BA_ "GenSigTimeoutTime_Teves_MK60_ESP" SG_ 640 MO1_Leergas 500;
BA_ "GenSigTimeoutMsg_Teves_MK60_ESP" SG_ 640 MO1_Leergas 640;
BA_ "GenSigTimeoutTime_Gateway_PQ46_A" SG_ 640 MO1_Leergas 500;
BA_ "GenSigTimeoutMsg_Gateway_PQ46_A" SG_ 640 MO1_Leergas 640;
BA_ "GenSigTimeoutTime_AG6" SG_ 640 MO1_Leergas 500;
BA_ "GenSigTimeoutMsg_AG6" SG_ 640 MO1_Leergas 640;
BA_ "GenSigSendType" SG_ 640 MO1_Leergas 0;
BA_ "GenSigTimeoutTime_TRW_ESP" SG_ 640 MO1_TiOut_Br 500;
BA_ "GenSigTimeoutMsg_TRW_ESP" SG_ 640 MO1_TiOut_Br 640;
BA_ "GenSigTimeoutTime_Gateway_PQ35_A" SG_ 640 MO1_TiOut_Br 500;
BA_ "GenSigTimeoutMsg_Gateway_PQ35_A" SG_ 640 MO1_TiOut_Br 640;
BA_ "GenSigTimeoutTime_Gateway_PQ46_A" SG_ 640 MO1_TiOut_Br 500;
BA_ "GenSigTimeoutMsg_Gateway_PQ46_A" SG_ 640 MO1_TiOut_Br 640;
BA_ "GenSigSendType" SG_ 640 MO1_TiOut_Br 0;
BA_ "GenSigTimeoutTime_EPB" SG_ 640 MO1_Sta_Bremse 500;
BA_ "GenSigTimeoutMsg_EPB" SG_ 640 MO1_Sta_Bremse 640;
BA_ "GenSigTimeoutTime_Gateway_PQ35_A" SG_ 640 MO1_Sta_Bremse 500;
BA_ "GenSigTimeoutMsg_Gateway_PQ35_A" SG_ 640 MO1_Sta_Bremse 640;
BA_ "GenSigTimeoutTime_TRW_ESP" SG_ 640 MO1_Sta_Bremse 500;
BA_ "GenSigTimeoutMsg_TRW_ESP" SG_ 640 MO1_Sta_Bremse 640;
BA_ "GenSigTimeoutTime_Teves_MK70_MAB" SG_ 640 MO1_Sta_Bremse 500;
BA_ "GenSigTimeoutMsg_Teves_MK70_MAB" SG_ 640 MO1_Sta_Bremse 640;
BA_ "GenSigTimeoutTime_Teves_MK60_ESP" SG_ 640 MO1_Sta_Bremse 500;
BA_ "GenSigTimeoutMsg_Teves_MK60_ESP" SG_ 640 MO1_Sta_Bremse 640;
BA_ "GenSigTimeoutTime_Gateway_PQ46_A" SG_ 640 MO1_Sta_Bremse 500;
BA_ "GenSigTimeoutMsg_Gateway_PQ46_A" SG_ 640 MO1_Sta_Bremse 640;
BA_ "GenSigSendType" SG_ 640 MO1_Sta_Bremse 0;
BA_ "GenSigTimeoutTime_Selespeed" SG_ 640 MO1_Kickdown 500;
BA_ "GenSigTimeoutMsg_Selespeed" SG_ 640 MO1_Kickdown 640;
BA_ "GenSigTimeoutTime_Hybrid_DQ200" SG_ 640 MO1_Kickdown 500;
BA_ "GenSigTimeoutMsg_Hybrid_DQ200" SG_ 640 MO1_Kickdown 640;
BA_ "GenSigTimeoutTime_Gateway_PQ35_A" SG_ 640 MO1_Kickdown 500;
BA_ "GenSigTimeoutMsg_Gateway_PQ35_A" SG_ 640 MO1_Kickdown 640;
BA_ "GenSigTimeoutTime_TRW_ESP" SG_ 640 MO1_Kickdown 500;
BA_ "GenSigTimeoutMsg_TRW_ESP" SG_ 640 MO1_Kickdown 640;
BA_ "GenSigTimeoutTime_DQ" SG_ 640 MO1_Kickdown 500;
BA_ "GenSigTimeoutMsg_DQ" SG_ 640 MO1_Kickdown 640;
BA_ "GenSigTimeoutTime_Gateway_PQ46_A" SG_ 640 MO1_Kickdown 500;
BA_ "GenSigTimeoutMsg_Gateway_PQ46_A" SG_ 640 MO1_Kickdown 640;
BA_ "GenSigTimeoutTime_AG6" SG_ 640 MO1_Kickdown 500;
BA_ "GenSigTimeoutMsg_AG6" SG_ 640 MO1_Kickdown 640;
BA_ "GenSigSendType" SG_ 640 MO1_Kickdown 0;
BA_ "GenSigTimeoutTime_Lenkhilfe_APA" SG_ 640 MO1_Sta_Pedal 500;
BA_ "GenSigTimeoutMsg_Lenkhilfe_APA" SG_ 640 MO1_Sta_Pedal 640;
BA_ "GenSigTimeoutTime_Gateway_PQ35_A" SG_ 640 MO1_Sta_Pedal 500;
BA_ "GenSigTimeoutMsg_Gateway_PQ35_A" SG_ 640 MO1_Sta_Pedal 640;
BA_ "GenSigTimeoutTime_TRW_ESP" SG_ 640 MO1_Sta_Pedal 500;
BA_ "GenSigTimeoutMsg_TRW_ESP" SG_ 640 MO1_Sta_Pedal 640;
BA_ "GenSigTimeoutTime_Teves_MK70_MAB" SG_ 640 MO1_Sta_Pedal 500;
BA_ "GenSigTimeoutMsg_Teves_MK70_MAB" SG_ 640 MO1_Sta_Pedal 640;
BA_ "GenSigTimeoutTime_Teves_MK60_ESP" SG_ 640 MO1_Sta_Pedal 500;
BA_ "GenSigTimeoutMsg_Teves_MK60_ESP" SG_ 640 MO1_Sta_Pedal 640;
BA_ "GenSigTimeoutTime_Gateway_PQ46_A" SG_ 640 MO1_Sta_Pedal 500;
BA_ "GenSigTimeoutMsg_Gateway_PQ46_A" SG_ 640 MO1_Sta_Pedal 640;
BA_ "GenSigTimeoutTime_AG6" SG_ 640 MO1_Sta_Pedal 500;
BA_ "GenSigTimeoutMsg_AG6" SG_ 640 MO1_Sta_Pedal 640;
BA_ "GenSigSendType" SG_ 640 MO1_Sta_Pedal 0;
BA_ "GenSigTimeoutTime_ACC_Lidar" SG_ 640 MO1_Kup_schalt 500;
BA_ "GenSigTimeoutMsg_ACC_Lidar" SG_ 640 MO1_Kup_schalt 640;
BA_ "GenSigTimeoutTime_RKA_Plus" SG_ 640 MO1_Kup_schalt 500;
BA_ "GenSigTimeoutMsg_RKA_Plus" SG_ 640 MO1_Kup_schalt 640;
BA_ "GenSigTimeoutTime_Gateway_PQ35_A" SG_ 640 MO1_Kup_schalt 500;
BA_ "GenSigTimeoutMsg_Gateway_PQ35_A" SG_ 640 MO1_Kup_schalt 640;
BA_ "GenSigTimeoutTime_ACC_Radar" SG_ 640 MO1_Kup_schalt 500;
BA_ "GenSigTimeoutMsg_ACC_Radar" SG_ 640 MO1_Kup_schalt 640;
BA_ "GenSigTimeoutTime_TRW_ESP" SG_ 640 MO1_Kup_schalt 500;
BA_ "GenSigTimeoutMsg_TRW_ESP" SG_ 640 MO1_Kup_schalt 640;
BA_ "GenSigTimeoutTime_EPB" SG_ 640 MO1_Kup_schalt 500;
BA_ "GenSigTimeoutMsg_EPB" SG_ 640 MO1_Kup_schalt 640;
BA_ "GenSigTimeoutTime_Teves_MK70_MAB" SG_ 640 MO1_Kup_schalt 500;
BA_ "GenSigTimeoutMsg_Teves_MK70_MAB" SG_ 640 MO1_Kup_schalt 640;
BA_ "GenSigTimeoutTime_Teves_MK60_ESP" SG_ 640 MO1_Kup_schalt 500;
BA_ "GenSigTimeoutMsg_Teves_MK60_ESP" SG_ 640 MO1_Kup_schalt 640;
BA_ "GenSigTimeoutTime_Allrad" SG_ 640 MO1_Kup_schalt 500;
BA_ "GenSigTimeoutMsg_Allrad" SG_ 640 MO1_Kup_schalt 640;
BA_ "GenSigTimeoutTime_Gateway_PQ46_A" SG_ 640 MO1_Kup_schalt 500;
BA_ "GenSigTimeoutMsg_Gateway_PQ46_A" SG_ 640 MO1_Kup_schalt 640;
BA_ "GenSigSendType" SG_ 640 MO1_Kup_schalt 0;
BA_ "GenSigTimeoutTime_Hybrid_DQ200" SG_ 640 MO1_Sta_Getr 500;
BA_ "GenSigTimeoutMsg_Hybrid_DQ200" SG_ 640 MO1_Sta_Getr 640;
BA_ "GenSigTimeoutTime_Gateway_PQ35_A" SG_ 640 MO1_Sta_Getr 500;
BA_ "GenSigTimeoutMsg_Gateway_PQ35_A" SG_ 640 MO1_Sta_Getr 640;
BA_ "GenSigTimeoutTime_TRW_ESP" SG_ 640 MO1_Sta_Getr 500;
BA_ "GenSigTimeoutMsg_TRW_ESP" SG_ 640 MO1_Sta_Getr 640;
BA_ "GenSigTimeoutTime_DQ" SG_ 640 MO1_Sta_Getr 500;
BA_ "GenSigTimeoutMsg_DQ" SG_ 640 MO1_Sta_Getr 640;
BA_ "GenSigTimeoutTime_Gateway_PQ46_A" SG_ 640 MO1_Sta_Getr 500;
BA_ "GenSigTimeoutMsg_Gateway_PQ46_A" SG_ 640 MO1_Sta_Getr 640;
BA_ "GenSigTimeoutTime_AG6" SG_ 640 MO1_Sta_Getr 500;
BA_ "GenSigTimeoutMsg_AG6" SG_ 640 MO1_Sta_Getr 640;
BA_ "GenSigSendType" SG_ 640 MO1_Sta_Getr 0;
BA_ "GenSigTimeoutTime_Lenkhilfe_ZF_2" SG_ 640 MO1_Pedalwert 500;
BA_ "GenSigTimeoutMsg_Lenkhilfe_ZF_2" SG_ 640 MO1_Pedalwert 640;
BA_ "GenSigTimeoutTime_Lenkhilfe_ZF_3" SG_ 640 MO1_Pedalwert 500;
BA_ "GenSigTimeoutMsg_Lenkhilfe_ZF_3" SG_ 640 MO1_Pedalwert 640;
BA_ "GenSigTimeoutTime_Lenkhilfe_APA" SG_ 640 MO1_Pedalwert 500;
BA_ "GenSigTimeoutMsg_Lenkhilfe_APA" SG_ 640 MO1_Pedalwert 640;
BA_ "GenSigTimeoutTime_ACC_Lidar" SG_ 640 MO1_Pedalwert 500;
BA_ "GenSigTimeoutMsg_ACC_Lidar" SG_ 640 MO1_Pedalwert 640;
BA_ "GenSigTimeoutTime_Selespeed" SG_ 640 MO1_Pedalwert 500;
BA_ "GenSigTimeoutMsg_Selespeed" SG_ 640 MO1_Pedalwert 640;
BA_ "GenSigTimeoutTime_Hybrid_DQ200" SG_ 640 MO1_Pedalwert 500;
BA_ "GenSigTimeoutMsg_Hybrid_DQ200" SG_ 640 MO1_Pedalwert 640;
BA_ "GenSigTimeoutTime_Gateway_PQ35_A" SG_ 640 MO1_Pedalwert 500;
BA_ "GenSigTimeoutMsg_Gateway_PQ35_A" SG_ 640 MO1_Pedalwert 640;
BA_ "GenSigTimeoutTime_AFS" SG_ 640 MO1_Pedalwert 500;
BA_ "GenSigTimeoutMsg_AFS" SG_ 640 MO1_Pedalwert 640;
BA_ "GenSigTimeoutTime_ACC_Radar" SG_ 640 MO1_Pedalwert 500;
BA_ "GenSigTimeoutMsg_ACC_Radar" SG_ 640 MO1_Pedalwert 640;
BA_ "GenSigTimeoutTime_TRW_ESP" SG_ 640 MO1_Pedalwert 500;
BA_ "GenSigTimeoutMsg_TRW_ESP" SG_ 640 MO1_Pedalwert 640;
BA_ "GenSigTimeoutTime_DQ" SG_ 640 MO1_Pedalwert 500;
BA_ "GenSigTimeoutMsg_DQ" SG_ 640 MO1_Pedalwert 640;
BA_ "GenSigTimeoutTime_Teves_MK70_MAB" SG_ 640 MO1_Pedalwert 500;
BA_ "GenSigTimeoutMsg_Teves_MK70_MAB" SG_ 640 MO1_Pedalwert 640;
BA_ "GenSigTimeoutTime_LWR" SG_ 640 MO1_Pedalwert 500;
BA_ "GenSigTimeoutMsg_LWR" SG_ 640 MO1_Pedalwert 640;
BA_ "GenSigTimeoutTime_Teves_MK60_ESP" SG_ 640 MO1_Pedalwert 500;
BA_ "GenSigTimeoutMsg_Teves_MK60_ESP" SG_ 640 MO1_Pedalwert 640;
BA_ "GenSigTimeoutTime_Allrad" SG_ 640 MO1_Pedalwert 500;
BA_ "GenSigTimeoutMsg_Allrad" SG_ 640 MO1_Pedalwert 640;
BA_ "GenSigTimeoutTime_Gateway_PQ46_A" SG_ 640 MO1_Pedalwert 500;
BA_ "GenSigTimeoutMsg_Gateway_PQ46_A" SG_ 640 MO1_Pedalwert 640;
BA_ "GenSigTimeoutTime_AG6" SG_ 640 MO1_Pedalwert 500;
BA_ "GenSigTimeoutMsg_AG6" SG_ 640 MO1_Pedalwert 640;
BA_ "GenSigSendType" SG_ 640 MO1_Pedalwert 0;
BA_ "GenSigTimeoutTime_Selespeed" SG_ 640 MO1_Sta_MotMo 500;
BA_ "GenSigTimeoutMsg_Selespeed" SG_ 640 MO1_Sta_MotMo 640;
BA_ "GenSigTimeoutTime_Hybrid_DQ200" SG_ 640 MO1_Sta_MotMo 500;
BA_ "GenSigTimeoutMsg_Hybrid_DQ200" SG_ 640 MO1_Sta_MotMo 640;
BA_ "GenSigTimeoutTime_RKA_Plus" SG_ 640 MO1_Sta_MotMo 500;
BA_ "GenSigTimeoutMsg_RKA_Plus" SG_ 640 MO1_Sta_MotMo 640;
BA_ "GenSigTimeoutTime_Gateway_PQ35_A" SG_ 640 MO1_Sta_MotMo 500;
BA_ "GenSigTimeoutMsg_Gateway_PQ35_A" SG_ 640 MO1_Sta_MotMo 640;
BA_ "GenSigTimeoutTime_TRW_ESP" SG_ 640 MO1_Sta_MotMo 500;
BA_ "GenSigTimeoutMsg_TRW_ESP" SG_ 640 MO1_Sta_MotMo 640;
BA_ "GenSigTimeoutTime_DQ" SG_ 640 MO1_Sta_MotMo 500;
BA_ "GenSigTimeoutMsg_DQ" SG_ 640 MO1_Sta_MotMo 640;
BA_ "GenSigTimeoutTime_Teves_MK70_MAB" SG_ 640 MO1_Sta_MotMo 500;
BA_ "GenSigTimeoutMsg_Teves_MK70_MAB" SG_ 640 MO1_Sta_MotMo 640;
BA_ "GenSigTimeoutTime_Teves_MK60_ESP" SG_ 640 MO1_Sta_MotMo 500;
BA_ "GenSigTimeoutMsg_Teves_MK60_ESP" SG_ 640 MO1_Sta_MotMo 640;
BA_ "GenSigTimeoutTime_Gateway_PQ46_A" SG_ 640 MO1_Sta_MotMo 500;
BA_ "GenSigTimeoutMsg_Gateway_PQ46_A" SG_ 640 MO1_Sta_MotMo 640;
BA_ "GenSigTimeoutTime_AG6" SG_ 640 MO1_Sta_MotMo 500;
BA_ "GenSigTimeoutMsg_AG6" SG_ 640 MO1_Sta_MotMo 640;
BA_ "GenSigSendType" SG_ 640 MO1_Sta_MotMo 0;
BA_ "GenSigTimeoutTime_Selespeed" SG_ 640 MO1_Mo_m_ex 500;
BA_ "GenSigTimeoutMsg_Selespeed" SG_ 640 MO1_Mo_m_ex 640;
BA_ "GenSigTimeoutTime_Hybrid_DQ200" SG_ 640 MO1_Mo_m_ex 500;
BA_ "GenSigTimeoutMsg_Hybrid_DQ200" SG_ 640 MO1_Mo_m_ex 640;
BA_ "GenSigTimeoutTime_RKA_Plus" SG_ 640 MO1_Mo_m_ex 500;
BA_ "GenSigTimeoutMsg_RKA_Plus" SG_ 640 MO1_Mo_m_ex 640;
BA_ "GenSigTimeoutTime_Magne_Ride" SG_ 640 MO1_Mo_m_ex 500;
BA_ "GenSigTimeoutMsg_Magne_Ride" SG_ 640 MO1_Mo_m_ex 640;
BA_ "GenSigTimeoutTime_Gateway_PQ35_A" SG_ 640 MO1_Mo_m_ex 500;
BA_ "GenSigTimeoutMsg_Gateway_PQ35_A" SG_ 640 MO1_Mo_m_ex 640;
BA_ "GenSigTimeoutTime_TRW_ESP" SG_ 640 MO1_Mo_m_ex 500;
BA_ "GenSigTimeoutMsg_TRW_ESP" SG_ 640 MO1_Mo_m_ex 640;
BA_ "GenSigTimeoutTime_DQ" SG_ 640 MO1_Mo_m_ex 500;
BA_ "GenSigTimeoutMsg_DQ" SG_ 640 MO1_Mo_m_ex 640;
BA_ "GenSigTimeoutTime_Teves_MK70_MAB" SG_ 640 MO1_Mo_m_ex 500;
BA_ "GenSigTimeoutMsg_Teves_MK70_MAB" SG_ 640 MO1_Mo_m_ex 640;
BA_ "GenSigTimeoutTime_Teves_MK60_ESP" SG_ 640 MO1_Mo_m_ex 500;
BA_ "GenSigTimeoutMsg_Teves_MK60_ESP" SG_ 640 MO1_Mo_m_ex 640;
BA_ "GenSigTimeoutTime_Allrad" SG_ 640 MO1_Mo_m_ex 500;
BA_ "GenSigTimeoutMsg_Allrad" SG_ 640 MO1_Mo_m_ex 640;
BA_ "GenSigTimeoutTime_Gateway_PQ46_A" SG_ 640 MO1_Mo_m_ex 500;
BA_ "GenSigTimeoutMsg_Gateway_PQ46_A" SG_ 640 MO1_Mo_m_ex 640;
BA_ "GenSigTimeoutTime_AG6" SG_ 640 MO1_Mo_m_ex 500;
BA_ "GenSigTimeoutMsg_AG6" SG_ 640 MO1_Mo_m_ex 640;
BA_ "GenSigSendType" SG_ 640 MO1_Mo_m_ex 0;
BA_ "GenSigTimeoutTime_Selespeed" SG_ 640 MO1_Verlustmo 500;
BA_ "GenSigTimeoutMsg_Selespeed" SG_ 640 MO1_Verlustmo 640;
BA_ "GenSigTimeoutTime_Hybrid_DQ200" SG_ 640 MO1_Verlustmo 500;
BA_ "GenSigTimeoutMsg_Hybrid_DQ200" SG_ 640 MO1_Verlustmo 640;
BA_ "GenSigTimeoutTime_RKA_Plus" SG_ 640 MO1_Verlustmo 500;
BA_ "GenSigTimeoutMsg_RKA_Plus" SG_ 640 MO1_Verlustmo 640;
BA_ "GenSigTimeoutTime_Magne_Ride" SG_ 640 MO1_Verlustmo 500;
BA_ "GenSigTimeoutMsg_Magne_Ride" SG_ 640 MO1_Verlustmo 640;
BA_ "GenSigTimeoutTime_Gateway_PQ35_A" SG_ 640 MO1_Verlustmo 500;
BA_ "GenSigTimeoutMsg_Gateway_PQ35_A" SG_ 640 MO1_Verlustmo 640;
BA_ "GenSigTimeoutTime_TRW_ESP" SG_ 640 MO1_Verlustmo 500;
BA_ "GenSigTimeoutMsg_TRW_ESP" SG_ 640 MO1_Verlustmo 640;
BA_ "GenSigTimeoutTime_DQ" SG_ 640 MO1_Verlustmo 500;
BA_ "GenSigTimeoutMsg_DQ" SG_ 640 MO1_Verlustmo 640;
BA_ "GenSigTimeoutTime_Teves_MK70_MAB" SG_ 640 MO1_Verlustmo 500;
BA_ "GenSigTimeoutMsg_Teves_MK70_MAB" SG_ 640 MO1_Verlustmo 640;
BA_ "GenSigTimeoutTime_Teves_MK60_ESP" SG_ 640 MO1_Verlustmo 500;
BA_ "GenSigTimeoutMsg_Teves_MK60_ESP" SG_ 640 MO1_Verlustmo 640;
BA_ "GenSigTimeoutTime_Allrad" SG_ 640 MO1_Verlustmo 500;
BA_ "GenSigTimeoutMsg_Allrad" SG_ 640 MO1_Verlustmo 640;
BA_ "GenSigTimeoutTime_Gateway_PQ46_A" SG_ 640 MO1_Verlustmo 500;
BA_ "GenSigTimeoutMsg_Gateway_PQ46_A" SG_ 640 MO1_Verlustmo 640;
BA_ "GenSigTimeoutTime_AG6" SG_ 640 MO1_Verlustmo 500;
BA_ "GenSigTimeoutMsg_AG6" SG_ 640 MO1_Verlustmo 640;
BA_ "GenSigSendType" SG_ 640 MO1_Verlustmo 0;
BA_ "GenSigTimeoutTime_Hybrid_DQ200" SG_ 640 MO1_Mo_o_ex 500;
BA_ "GenSigTimeoutMsg_Hybrid_DQ200" SG_ 640 MO1_Mo_o_ex 640;
BA_ "GenSigTimeoutTime_Gateway_PQ35_A" SG_ 640 MO1_Mo_o_ex 500;
BA_ "GenSigTimeoutMsg_Gateway_PQ35_A" SG_ 640 MO1_Mo_o_ex 640;
BA_ "GenSigTimeoutTime_TRW_ESP" SG_ 640 MO1_Mo_o_ex 500;
BA_ "GenSigTimeoutMsg_TRW_ESP" SG_ 640 MO1_Mo_o_ex 640;
BA_ "GenSigTimeoutTime_DQ" SG_ 640 MO1_Mo_o_ex 500;
BA_ "GenSigTimeoutMsg_DQ" SG_ 640 MO1_Mo_o_ex 640;
BA_ "GenSigTimeoutTime_Teves_MK70_MAB" SG_ 640 MO1_Mo_o_ex 500;
BA_ "GenSigTimeoutMsg_Teves_MK70_MAB" SG_ 640 MO1_Mo_o_ex 640;
BA_ "GenSigTimeoutTime_Teves_MK60_ESP" SG_ 640 MO1_Mo_o_ex 500;
BA_ "GenSigTimeoutMsg_Teves_MK60_ESP" SG_ 640 MO1_Mo_o_ex 640;
BA_ "GenSigTimeoutTime_Gateway_PQ46_A" SG_ 640 MO1_Mo_o_ex 500;
BA_ "GenSigTimeoutMsg_Gateway_PQ46_A" SG_ 640 MO1_Mo_o_ex 640;
BA_ "GenSigTimeoutTime_AG6" SG_ 640 MO1_Mo_o_ex 500;
BA_ "GenSigTimeoutMsg_AG6" SG_ 640 MO1_Mo_o_ex 640;
BA_ "GenSigSendType" SG_ 640 MO1_Mo_o_ex 0;
BA_ "GenSigTimeoutTime_Airbag" SG_ 640 MO1_Drehzahl 500;
BA_ "GenSigTimeoutMsg_Airbag" SG_ 640 MO1_Drehzahl 640;
BA_ "GenSigTimeoutTime_Hybrid_PWR" SG_ 640 MO1_Drehzahl 500;
BA_ "GenSigTimeoutMsg_Hybrid_PWR" SG_ 640 MO1_Drehzahl 640;
BA_ "GenSigTimeoutTime_Lenkhilfe_ZF_3" SG_ 640 MO1_Drehzahl 500;
BA_ "GenSigTimeoutMsg_Lenkhilfe_ZF_3" SG_ 640 MO1_Drehzahl 640;
BA_ "GenSigTimeoutTime_ACC_Lidar" SG_ 640 MO1_Drehzahl 500;
BA_ "GenSigTimeoutMsg_ACC_Lidar" SG_ 640 MO1_Drehzahl 640;
BA_ "GenSigTimeoutTime_Selespeed" SG_ 640 MO1_Drehzahl 500;
BA_ "GenSigTimeoutMsg_Selespeed" SG_ 640 MO1_Drehzahl 640;
BA_ "GenSigTimeoutTime_HCA" SG_ 640 MO1_Drehzahl 500;
BA_ "GenSigTimeoutMsg_HCA" SG_ 640 MO1_Drehzahl 640;
BA_ "GenSigTimeoutTime_Hybrid_DQ200" SG_ 640 MO1_Drehzahl 500;
BA_ "GenSigTimeoutMsg_Hybrid_DQ200" SG_ 640 MO1_Drehzahl 640;
BA_ "GenSigTimeoutTime_Lenkhilfe_APA" SG_ 640 MO1_Drehzahl 500;
BA_ "GenSigTimeoutMsg_Lenkhilfe_APA" SG_ 640 MO1_Drehzahl 640;
BA_ "GenSigTimeoutTime_RKA_Plus" SG_ 640 MO1_Drehzahl 500;
BA_ "GenSigTimeoutMsg_RKA_Plus" SG_ 640 MO1_Drehzahl 640;
BA_ "GenSigTimeoutTime_Magne_Ride" SG_ 640 MO1_Drehzahl 500;
BA_ "GenSigTimeoutMsg_Magne_Ride" SG_ 640 MO1_Drehzahl 640;
BA_ "GenSigTimeoutTime_Gateway_PQ35_A" SG_ 640 MO1_Drehzahl 500;
BA_ "GenSigTimeoutMsg_Gateway_PQ35_A" SG_ 640 MO1_Drehzahl 640;
BA_ "GenSigTimeoutTime_AFS" SG_ 640 MO1_Drehzahl 500;
BA_ "GenSigTimeoutMsg_AFS" SG_ 640 MO1_Drehzahl 640;
BA_ "GenSigTimeoutTime_ACC_Radar" SG_ 640 MO1_Drehzahl 500;
BA_ "GenSigTimeoutMsg_ACC_Radar" SG_ 640 MO1_Drehzahl 640;
BA_ "GenSigTimeoutTime_TRW_ESP" SG_ 640 MO1_Drehzahl 500;
BA_ "GenSigTimeoutMsg_TRW_ESP" SG_ 640 MO1_Drehzahl 640;
BA_ "GenSigTimeoutTime_EPB" SG_ 640 MO1_Drehzahl 500;
BA_ "GenSigTimeoutMsg_EPB" SG_ 640 MO1_Drehzahl 640;
BA_ "GenSigTimeoutTime_DQ" SG_ 640 MO1_Drehzahl 500;
BA_ "GenSigTimeoutMsg_DQ" SG_ 640 MO1_Drehzahl 640;
BA_ "GenSigTimeoutTime_Teves_MK70_MAB" SG_ 640 MO1_Drehzahl 500;
BA_ "GenSigTimeoutMsg_Teves_MK70_MAB" SG_ 640 MO1_Drehzahl 640;
BA_ "GenSigTimeoutTime_LWR" SG_ 640 MO1_Drehzahl 500;
BA_ "GenSigTimeoutMsg_LWR" SG_ 640 MO1_Drehzahl 640;
BA_ "GenSigTimeoutTime_Teves_MK60_ESP" SG_ 640 MO1_Drehzahl 500;
BA_ "GenSigTimeoutMsg_Teves_MK60_ESP" SG_ 640 MO1_Drehzahl 640;
BA_ "GenSigTimeoutTime_Lenkhilfe_ZF_2" SG_ 640 MO1_Drehzahl 500;
BA_ "GenSigTimeoutMsg_Lenkhilfe_ZF_2" SG_ 640 MO1_Drehzahl 640;
BA_ "GenSigTimeoutTime_Allrad" SG_ 640 MO1_Drehzahl 500;
BA_ "GenSigTimeoutMsg_Allrad" SG_ 640 MO1_Drehzahl 640;
BA_ "GenSigTimeoutTime_Gateway_PQ46_A" SG_ 640 MO1_Drehzahl 500;
BA_ "GenSigTimeoutMsg_Gateway_PQ46_A" SG_ 640 MO1_Drehzahl 640;
BA_ "GenSigTimeoutTime_AG6" SG_ 640 MO1_Drehzahl 500;
BA_ "GenSigTimeoutMsg_AG6" SG_ 640 MO1_Drehzahl 640;
BA_ "GenSigSendType" SG_ 640 MO1_Drehzahl 0;
BA_ "GenSigTimeoutTime_Allrad" SG_ 640 MO1_Wunschmo 500;
BA_ "GenSigTimeoutMsg_Allrad" SG_ 640 MO1_Wunschmo 640;
BA_ "GenSigTimeoutTime_Selespeed" SG_ 640 MO1_Wunschmo 500;
BA_ "GenSigTimeoutMsg_Selespeed" SG_ 640 MO1_Wunschmo 640;
BA_ "GenSigTimeoutTime_Hybrid_DQ200" SG_ 640 MO1_Wunschmo 500;
BA_ "GenSigTimeoutMsg_Hybrid_DQ200" SG_ 640 MO1_Wunschmo 640;
BA_ "GenSigTimeoutTime_Daempfer" SG_ 640 MO1_Wunschmo 500;
BA_ "GenSigTimeoutMsg_Daempfer" SG_ 640 MO1_Wunschmo 640;
BA_ "GenSigTimeoutTime_Magne_Ride" SG_ 640 MO1_Wunschmo 500;
BA_ "GenSigTimeoutMsg_Magne_Ride" SG_ 640 MO1_Wunschmo 640;
BA_ "GenSigTimeoutTime_Gateway_PQ35_A" SG_ 640 MO1_Wunschmo 500;
BA_ "GenSigTimeoutMsg_Gateway_PQ35_A" SG_ 640 MO1_Wunschmo 640;
BA_ "GenSigTimeoutTime_TRW_ESP" SG_ 640 MO1_Wunschmo 500;
BA_ "GenSigTimeoutMsg_TRW_ESP" SG_ 640 MO1_Wunschmo 640;
BA_ "GenSigTimeoutTime_DQ" SG_ 640 MO1_Wunschmo 500;
BA_ "GenSigTimeoutMsg_DQ" SG_ 640 MO1_Wunschmo 640;
BA_ "GenSigTimeoutTime_Teves_MK70_MAB" SG_ 640 MO1_Wunschmo 500;
BA_ "GenSigTimeoutMsg_Teves_MK70_MAB" SG_ 640 MO1_Wunschmo 640;
BA_ "GenSigTimeoutTime_Teves_MK60_ESP" SG_ 640 MO1_Wunschmo 500;
BA_ "GenSigTimeoutMsg_Teves_MK60_ESP" SG_ 640 MO1_Wunschmo 640;
BA_ "GenSigTimeoutTime_Gateway_PQ46_A" SG_ 640 MO1_Wunschmo 500;
BA_ "GenSigTimeoutMsg_Gateway_PQ46_A" SG_ 640 MO1_Wunschmo 640;
BA_ "GenSigSendType" SG_ 640 MO1_Wunschmo 0;
BA_ "GenSigTimeoutTime_Hybrid_DQ200" SG_ 1154 MH1_VM_Mom_oE 500;
BA_ "GenSigTimeoutMsg_Hybrid_DQ200" SG_ 1154 MH1_VM_Mom_oE 1154;
BA_ "GenSigSendType" SG_ 1154 MH1_VM_Mom_oE 0;
BA_ "GenSigStartValue" SG_ 1154 MH1_VM_Mom_oE 125;
BA_ "GenSigTimeoutTime_Hybrid_DQ200" SG_ 1154 MH1_IstStatusK0 500;
BA_ "GenSigTimeoutMsg_Hybrid_DQ200" SG_ 1154 MH1_IstStatusK0 1154;
BA_ "GenSigSendType" SG_ 1154 MH1_IstStatusK0 0;
BA_ "GenSigTimeoutTime_Hybrid_DQ200" SG_ 1154 MH1_Startmodus_PQ35 500;
BA_ "GenSigTimeoutMsg_Hybrid_DQ200" SG_ 1154 MH1_Startmodus_PQ35 1154;
BA_ "GenSigSendType" SG_ 1154 MH1_Startmodus_PQ35 0;
BA_ "GenSigTimeoutTime_Hybrid_DQ200" SG_ 1154 MH1_VM_aktiv 500;
BA_ "GenSigTimeoutMsg_Hybrid_DQ200" SG_ 1154 MH1_VM_aktiv 1154;
BA_ "GenSigSendType" SG_ 1154 MH1_VM_aktiv 0;
BA_ "GenSigTimeoutTime_Hybrid_DQ200" SG_ 1154 MH1_Zielzustand_Hybrid 500;
BA_ "GenSigTimeoutMsg_Hybrid_DQ200" SG_ 1154 MH1_Zielzustand_Hybrid 1154;
BA_ "GenSigSendType" SG_ 1154 MH1_Zielzustand_Hybrid 0;
BA_ "GenSigTimeoutTime_Hybrid_DQ200" SG_ 1154 MH1_VerlParam_Msum 500;
BA_ "GenSigTimeoutMsg_Hybrid_DQ200" SG_ 1154 MH1_VerlParam_Msum 1154;
BA_ "GenSigSendType" SG_ 1154 MH1_VerlParam_Msum 0;
BA_ "GenSigTimeoutTime_Hybrid_DQ200" SG_ 1154 MH1_E_Faktor 500;
BA_ "GenSigTimeoutMsg_Hybrid_DQ200" SG_ 1154 MH1_E_Faktor 1154;
BA_ "GenSigSendType" SG_ 1154 MH1_E_Faktor 0;
BA_ "GenSigTimeoutTime_Hybrid_DQ200" SG_ 1154 MH1_Drehzahl_VM 500;
BA_ "GenSigTimeoutMsg_Hybrid_DQ200" SG_ 1154 MH1_Drehzahl_VM 1154;
BA_ "GenSigSendType" SG_ 1154 MH1_Drehzahl_VM 0;
BA_ "GenSigTimeoutTime_Hybrid_DQ200" SG_ 1154 MH1_Schaltverh 500;
BA_ "GenSigTimeoutMsg_Hybrid_DQ200" SG_ 1154 MH1_Schaltverh 1154;
BA_ "GenSigSendType" SG_ 1154 MH1_Schaltverh 0;
BA_ "GenSigSendType" SG_ 1154 MH1_max_ind_VM_Mom 0;
BA_ "GenSigStartValue" SG_ 1154 MH1_max_ind_VM_Mom 254;
BA_ "GenSigSendType" SG_ 1154 MH1_Startmodus_PL71 0;
BA_ "GenSigTimeoutTime_Hybrid_DQ200" SG_ 1154 MH1_ACCGRA_aktiv 500;
BA_ "GenSigTimeoutMsg_Hybrid_DQ200" SG_ 1154 MH1_ACCGRA_aktiv 1154;
BA_ "GenSigSendType" SG_ 1154 MH1_ACCGRA_aktiv 0;
BA_ "GenSigTimeoutTime_Hybrid_DQ200" SG_ 1154 MH1_LowSpeedModus 500;
BA_ "GenSigTimeoutMsg_Hybrid_DQ200" SG_ 1154 MH1_LowSpeedModus 1154;
BA_ "GenSigSendType" SG_ 1154 MH1_LowSpeedModus 0;
BA_ "GenSigSendType" SG_ 1154 MH1_Bremspedalwert 0;
BA_ "GenSigSendType" SG_ 1154 MH1_QB_Bremspedalwert 0;
BA_ "GenSigStartValue" SG_ 1154 MH1_QB_Bremspedalwert 1;
BA_ "GenSigSendType" SG_ 1154 MH1_res_52 0;
BA_ "GenSigTimeoutTime_Hybrid_DQ200" SG_ 1154 MH1_MomVerlauf_EM 500;
BA_ "GenSigTimeoutMsg_Hybrid_DQ200" SG_ 1154 MH1_MomVerlauf_EM 1154;
BA_ "GenSigSendType" SG_ 1154 MH1_MomVerlauf_EM 0;
BA_ "GenSigTimeoutMsg_Gateway_PQ35_A" SG_ 1657 BAP_Data_HYB 1657;
BA_ "GenSigTimeoutMsg_Gateway_PQ46_A" SG_ 1657 BAP_Data_HYB 1657;
BA_ "GenSigTimeoutMsg_Gateway_PQ35_A" SG_ 1657 BAP_var_HYB 1657;
BA_ "GenSigTimeoutMsg_Gateway_PQ46_A" SG_ 1657 BAP_var_HYB 1657;
BA_ "GenSigTimeoutMsg_Gateway_PQ46_A" SG_ 2024 ISO_MO_01_Resp_Data 2024;
BA_ "GenSigTimeoutMsg_Gateway_PQ35_A" SG_ 2024 ISO_MO_01_Resp_Data 2024;
BA_ "GenSigTimeoutTime_Teves_MK60_ESP" SG_ 644 MOB_Bremsstgr 500;
BA_ "GenSigTimeoutMsg_Teves_MK60_ESP" SG_ 644 MOB_Bremsstgr 644;
BA_ "GenSigTimeoutTime_TRW_ESP" SG_ 644 MOB_Bremsstgr 500;
BA_ "GenSigTimeoutMsg_TRW_ESP" SG_ 644 MOB_Bremsstgr 644;
BA_ "GenSigSendType" SG_ 644 MOB_Bremsstgr 0;
BA_ "GenSigTimeoutTime_Teves_MK60_ESP" SG_ 644 MOB_Checksum 500;
BA_ "GenSigTimeoutMsg_Teves_MK60_ESP" SG_ 644 MOB_Checksum 644;
BA_ "GenSigTimeoutTime_TRW_ESP" SG_ 644 MOB_Checksum 500;
BA_ "GenSigTimeoutMsg_TRW_ESP" SG_ 644 MOB_Checksum 644;
BA_ "GenSigSendType" SG_ 644 MOB_Checksum 0;
BA_ "INIT" SG_ 644 MOB_Checksum "CHK";
BA_ "GenSigTimeoutTime_Teves_MK60_ESP" SG_ 644 MOB_Bremsmom 500;
BA_ "GenSigTimeoutMsg_Teves_MK60_ESP" SG_ 644 MOB_Bremsmom 644;
BA_ "GenSigTimeoutTime_TRW_ESP" SG_ 644 MOB_Bremsmom 500;
BA_ "GenSigTimeoutMsg_TRW_ESP" SG_ 644 MOB_Bremsmom 644;
BA_ "GenSigSendType" SG_ 644 MOB_Bremsmom 0;
BA_ "GenSigTimeoutTime_DQ" SG_ 644 MOB_Anhaltewunsch 500;
BA_ "GenSigTimeoutMsg_DQ" SG_ 644 MOB_Anhaltewunsch 644;
BA_ "GenSigTimeoutTime_Teves_MK60_ESP" SG_ 644 MOB_Anhaltewunsch 500;
BA_ "GenSigTimeoutMsg_Teves_MK60_ESP" SG_ 644 MOB_Anhaltewunsch 644;
BA_ "GenSigTimeoutTime_TRW_ESP" SG_ 644 MOB_Anhaltewunsch 500;
BA_ "GenSigTimeoutMsg_TRW_ESP" SG_ 644 MOB_Anhaltewunsch 644;
BA_ "GenSigSendType" SG_ 644 MOB_Anhaltewunsch 0;
BA_ "GenSigTimeoutTime_Teves_MK60_ESP" SG_ 644 MOB_res_15 500;
BA_ "GenSigTimeoutMsg_Teves_MK60_ESP" SG_ 644 MOB_res_15 644;
BA_ "GenSigTimeoutTime_TRW_ESP" SG_ 644 MOB_res_15 500;
BA_ "GenSigTimeoutMsg_TRW_ESP" SG_ 644 MOB_res_15 644;
BA_ "GenSigSendType" SG_ 644 MOB_res_15 0;
BA_ "GenSigTimeoutTime_Teves_MK60_ESP" SG_ 644 MOB_res_40 500;
BA_ "GenSigTimeoutMsg_Teves_MK60_ESP" SG_ 644 MOB_res_40 644;
BA_ "GenSigTimeoutTime_TRW_ESP" SG_ 644 MOB_res_40 500;
BA_ "GenSigTimeoutMsg_TRW_ESP" SG_ 644 MOB_res_40 644;
BA_ "GenSigSendType" SG_ 644 MOB_res_40 0;
BA_ "GenSigTimeoutTime_Teves_MK60_ESP" SG_ 644 MOB_Zaehler 500;
BA_ "GenSigTimeoutMsg_Teves_MK60_ESP" SG_ 644 MOB_Zaehler 644;
BA_ "GenSigTimeoutTime_TRW_ESP" SG_ 644 MOB_Zaehler 500;
BA_ "GenSigTimeoutMsg_TRW_ESP" SG_ 644 MOB_Zaehler 644;
BA_ "GenSigSendType" SG_ 644 MOB_Zaehler 0;
BA_ "GenSigTimeoutTime_Teves_MK60_ESP" SG_ 644 MOB_Freigabe 500;
BA_ "GenSigTimeoutMsg_Teves_MK60_ESP" SG_ 644 MOB_Freigabe 644;
BA_ "GenSigTimeoutTime_Gateway_PQ35_A" SG_ 644 MOB_Freigabe 500;
BA_ "GenSigTimeoutMsg_Gateway_PQ35_A" SG_ 644 MOB_Freigabe 644;
BA_ "GenSigTimeoutTime_TRW_ESP" SG_ 644 MOB_Freigabe 500;
BA_ "GenSigTimeoutMsg_TRW_ESP" SG_ 644 MOB_Freigabe 644;
BA_ "GenSigTimeoutTime_Gateway_PQ46_A" SG_ 644 MOB_Freigabe 500;
BA_ "GenSigTimeoutMsg_Gateway_PQ46_A" SG_ 644 MOB_Freigabe 644;
BA_ "GenSigSendType" SG_ 644 MOB_Freigabe 0;
BA_ "GenSigTimeoutTime_Teves_MK60_ESP" SG_ 644 MOB_Standby 500;
BA_ "GenSigTimeoutMsg_Teves_MK60_ESP" SG_ 644 MOB_Standby 644;
BA_ "GenSigTimeoutTime_TRW_ESP" SG_ 644 MOB_Standby 500;
BA_ "GenSigTimeoutMsg_TRW_ESP" SG_ 644 MOB_Standby 644;
BA_ "GenSigSendType" SG_ 644 MOB_Standby 0;
BA_ "GenSigTimeoutTime_Gateway_PQ35_A" SG_ 1162 MO8_LampeDZBegr 500;
BA_ "GenSigTimeoutMsg_Gateway_PQ35_A" SG_ 1162 MO8_LampeDZBegr 1162;
BA_ "GenSigSendType" SG_ 1162 MO8_LampeDZBegr 0;
BA_ "GenSigTimeoutTime_Magne_Ride" SG_ 1162 MO8_Zaehler 500;
BA_ "GenSigTimeoutMsg_Magne_Ride" SG_ 1162 MO8_Zaehler 1162;
BA_ "GenSigTimeoutTime_Gateway_PQ35_A" SG_ 1162 MO8_Zaehler 500;
BA_ "GenSigTimeoutMsg_Gateway_PQ35_A" SG_ 1162 MO8_Zaehler 1162;
BA_ "GenSigSendType" SG_ 1162 MO8_Zaehler 0;
BA_ "GenSigTimeoutTime_Magne_Ride" SG_ 1162 MO8_Checksumme 500;
BA_ "GenSigTimeoutMsg_Magne_Ride" SG_ 1162 MO8_Checksumme 1162;
BA_ "GenSigTimeoutTime_Gateway_PQ35_A" SG_ 1162 MO8_Checksumme 500;
BA_ "GenSigTimeoutMsg_Gateway_PQ35_A" SG_ 1162 MO8_Checksumme 1162;
BA_ "GenSigSendType" SG_ 1162 MO8_Checksumme 0;
BA_ "INIT" SG_ 1162 MO8_Checksumme "CHK";
BA_ "GenSigTimeoutTime_Gateway_PQ35_A" SG_ 1162 MO8_res_20 500;
BA_ "GenSigTimeoutMsg_Gateway_PQ35_A" SG_ 1162 MO8_res_20 1162;
BA_ "GenSigSendType" SG_ 1162 MO8_res_20 0;
BA_ "GenSigTimeoutTime_Gateway_PQ35_A" SG_ 1162 MO8_Spoiler_ausf 500;
BA_ "GenSigTimeoutMsg_Gateway_PQ35_A" SG_ 1162 MO8_Spoiler_ausf 1162;
BA_ "GenSigSendType" SG_ 1162 MO8_Spoiler_ausf 0;
BA_ "GenSigTimeoutTime_Gateway_PQ35_A" SG_ 1162 MO8_AnzeigeDZ 500;
BA_ "GenSigTimeoutMsg_Gateway_PQ35_A" SG_ 1162 MO8_AnzeigeDZ 1162;
BA_ "GenSigSendType" SG_ 1162 MO8_AnzeigeDZ 0;
BA_ "GenSigTimeoutTime_Gateway_PQ35_A" SG_ 1162 MO8_SGT_Soundakt 500;
BA_ "GenSigTimeoutMsg_Gateway_PQ35_A" SG_ 1162 MO8_SGT_Soundakt 1162;
BA_ "GenSigSendType" SG_ 1162 MO8_SGT_Soundakt 0;
BA_ "GenSigTimeoutTime_Gateway_PQ35_A" SG_ 1162 MO8_Enable_Oeldr_Motor 500;
BA_ "GenSigTimeoutMsg_Gateway_PQ35_A" SG_ 1162 MO8_Enable_Oeldr_Motor 1162;
BA_ "GenSigSendType" SG_ 1162 MO8_Enable_Oeldr_Motor 0;
BA_ "INIT" SG_ 1162 MO8_Enable_Oeldr_Motor "const";
BA_ "GenSigTimeoutTime_Magne_Ride" SG_ 1162 MO8_Sportschalter 500;
BA_ "GenSigTimeoutMsg_Magne_Ride" SG_ 1162 MO8_Sportschalter 1162;
BA_ "GenSigTimeoutTime_Selespeed" SG_ 1162 MO8_Sportschalter 500;
BA_ "GenSigTimeoutMsg_Selespeed" SG_ 1162 MO8_Sportschalter 1162;
BA_ "GenSigTimeoutTime_Gateway_PQ35_A" SG_ 1162 MO8_Sportschalter 500;
BA_ "GenSigTimeoutMsg_Gateway_PQ35_A" SG_ 1162 MO8_Sportschalter 1162;
BA_ "GenSigSendType" SG_ 1162 MO8_Sportschalter 0;
BA_ "GenSigTimeoutTime_Gateway_PQ35_A" SG_ 1162 MO8_res_30 500;
BA_ "GenSigTimeoutMsg_Gateway_PQ35_A" SG_ 1162 MO8_res_30 1162;
BA_ "GenSigSendType" SG_ 1162 MO8_res_30 0;
BA_ "GenSigTimeoutTime_Gateway_PQ35_A" SG_ 1162 MO8_Oeldr_Warn_Motor 500;
BA_ "GenSigTimeoutMsg_Gateway_PQ35_A" SG_ 1162 MO8_Oeldr_Warn_Motor 1162;
BA_ "GenSigSendType" SG_ 1162 MO8_Oeldr_Warn_Motor 0;
BA_ "GenSigTimeoutTime_Gateway_PQ35_A" SG_ 1162 MO8_res_29 500;
BA_ "GenSigTimeoutMsg_Gateway_PQ35_A" SG_ 1162 MO8_res_29 1162;
BA_ "GenSigSendType" SG_ 1162 MO8_res_29 0;
BA_ "GenSigTimeoutTime_Gateway_PQ35_A" SG_ 1162 MO8_GRA_v_Wunsch 500;
BA_ "GenSigTimeoutMsg_Gateway_PQ35_A" SG_ 1162 MO8_GRA_v_Wunsch 1162;
BA_ "GenSigSendType" SG_ 1162 MO8_GRA_v_Wunsch 0;
BA_ "GenSigTimeoutTime_Gateway_PQ35_A" SG_ 1162 MO8_Avus_Motorschutz 500;
BA_ "GenSigTimeoutMsg_Gateway_PQ35_A" SG_ 1162 MO8_Avus_Motorschutz 1162;
BA_ "GenSigSendType" SG_ 1162 MO8_Avus_Motorschutz 0;
BA_ "GenSigTimeoutTime_Gateway_PQ35_A" SG_ 1162 MO8_Nachlauf_ZWP 500;
BA_ "GenSigTimeoutMsg_Gateway_PQ35_A" SG_ 1162 MO8_Nachlauf_ZWP 1162;
BA_ "GenSigSendType" SG_ 1162 MO8_Nachlauf_ZWP 0;
BA_ "GenSigTimeoutTime_Gateway_PQ35_A" SG_ 1162 MO8_res_41 500;
BA_ "GenSigTimeoutMsg_Gateway_PQ35_A" SG_ 1162 MO8_res_41 1162;
BA_ "GenSigSendType" SG_ 1162 MO8_res_41 0;
BA_ "GenSigTimeoutTime_Gateway_PQ35_A" SG_ 1162 MO8_res_31 500;
BA_ "GenSigTimeoutMsg_Gateway_PQ35_A" SG_ 1162 MO8_res_31 1162;
BA_ "GenSigSendType" SG_ 1162 MO8_res_31 0;
BA_ "GenSigTimeoutTime_Gateway_PQ35_A" SG_ 1162 MO8_res_48 500;
BA_ "GenSigTimeoutMsg_Gateway_PQ35_A" SG_ 1162 MO8_res_48 1162;
BA_ "GenSigSendType" SG_ 1162 MO8_res_48 0;
BA_ "GenSigTimeoutTime_Gateway_PQ35_A" SG_ 1162 MO8_res_56 500;
BA_ "GenSigTimeoutMsg_Gateway_PQ35_A" SG_ 1162 MO8_res_56 1162;
BA_ "GenSigSendType" SG_ 1162 MO8_res_56 0;
BA_ "GenSigTimeoutTime_Gateway_PQ35_A" SG_ 1162 MO8_res_58 500;
BA_ "GenSigTimeoutMsg_Gateway_PQ35_A" SG_ 1162 MO8_res_58 1162;
BA_ "GenSigSendType" SG_ 1162 MO8_res_58 0;
BA_ "GenSigTimeoutTime_Gateway_PQ35_A" SG_ 1162 MO8_res_57 500;
BA_ "GenSigTimeoutMsg_Gateway_PQ35_A" SG_ 1162 MO8_res_57 1162;
BA_ "GenSigSendType" SG_ 1162 MO8_res_57 0;
BA_ "GenSigTimeoutTime_Gateway_PQ35_A" SG_ 1162 MO8_res_59 500;
BA_ "GenSigTimeoutMsg_Gateway_PQ35_A" SG_ 1162 MO8_res_59 1162;
BA_ "GenSigSendType" SG_ 1162 MO8_res_59 0;
VAL_ 648 MO2_CAN_Vers 54 "V516a_526_536" 53 "V514a_524_534" 50 "V496a_506" 48 "V494a_504" 47 "V493" 44 "V476c" 41 "V473a" 39 "V466a" 37 "V456" 27 "V503c" 26 "V436" 22 "V424e" 21 "V423d" 19 "V424b" 18 "V423a" 17 "V411c_421b_521_531" ;
VAL_ 648 MO2_Mp_Code 3 "MDI_Max" 2 "Getriebe_Kod" 1 "Motor_Kod" 0 "CAN_Stand" ;
VAL_ 648 MO2_Kuehlm_T 255 "Fehler" 0 "Init" ;
VAL_ 648 MO2_BTS 1 "Bremse_betaetigt" 0 "kein_Bremsen" ;
VAL_ 648 MO2_BLS 1 "Bremse_betaetigt" 0 "kein_Bremsen" ;
VAL_ 648 MO2_Sta_No_Bet 1 "Normalbetrieb" 0 "kein_Normalbetrieb" ;
VAL_ 648 MO2_Sta_Klima 1 "Klima_ein" 0 "Klima_aus" ;
VAL_ 648 MO2_Status_TSK 1 "TSK_verfuegbar" 0 "TSK_nicht_verfuegbar" ;
VAL_ 648 MO2_Sta_GRA 3 "ADR_nicht_freigegeben" 2 "uebersteuert_Lampe_an" 1 "aktiviert_Lampe_an" 0 "ADR_GRA_aus" ;
VAL_ 648 MO2_Sta_Kuehlm 1 "Temperatur_n_iO" 0 "Temperatur_iO" ;
VAL_ 648 MO2_LL_Solldz 255 "Fehler" ;
VAL_ 648 MO2_Sport_Error 1 "Fehler" 0 "kein_Fehler" ;
VAL_ 648 MO2_Mo_ZWR 255 "Fehler" ;
VAL_ 648 MO2_Begr_Mo 255 "Fehler" ;
VAL_ 648 MO2_Getr_Code 15 "Handschalter_konv" 11 "DQ250_DQ200" 10 "AG6_Jatco_ZF_6HP_AISIN" 9 "autom_Kupplung_mit_ASG" 8 "autom_Kupplung" 7 "AG5_Jatco" 6 "AG4_Jatco" 5 "VQ35" 4 "VQ250" 3 "VL300" 2 "AG4" 1 "_5HP24" 0 "_5HP19" ;
VAL_ 648 MO2_Sta_Limiter 3 "Fehler" 2 "Lim_ausgew_passiv" 1 "Lim_ausgew_aktiv" 0 "Lim_nicht_ausgew" ;
VAL_ 648 MO2_RME_Gehalt 7 "Fehler" ;
VAL_ 648 MO2_GRAregelt 1 "ja" 0 "nein" ;
VAL_ 648 MO2_OffRoad 1 "aktiv" 0 "nicht_aktiv" ;
VAL_ 648 MO2_GRA_Soll 255 "Fehler" ;
VAL_ 1416 MO7_Sta_VBegr 1 "aktiv" 0 "inaktiv" ;
VAL_ 1416 MO7_Fehlereintr 1 "Fehlerspeichereintrag" 0 "kein_Fehlerspeichereintrag" ;
VAL_ 1416 MO7_DFM 255 "Fehler" ;
VAL_ 1416 MO7_Fehler_VBegr 1 "V_Begrenzung_moeglich" 0 "V_Begrenzung_nicht_moeglich" ;
VAL_ 1416 MO7_StaOeltemp 1 "n_iO" 0 "iO" ;
VAL_ 1416 MO7_LL_Solldz 1 "LLDZ_hat_Wert_1_Stufe_erreicht" 0 "keine_Anf_einer_erhoehten_LL_DZ" ;
VAL_ 1416 MO7_Gradient_Dz 127 "ist_groessergleich_127_min" ;
VAL_ 1416 MO7_GradientVorz 1 "negativ" 0 "positiv" ;
VAL_ 1416 MO7_Hoeheninfo 255 "Fehler" ;
VAL_ 1416 MO7_RueckLLDz 1 "LLDZ_hat_Wert_2_Stufe_erreicht" 0 "keine_Anf_einer_erhoehten_LL_DZ" ;
VAL_ 1416 MO7_Oeltemp 255 "Fehler" 1 "Init" 0 "nicht_verbaut" ;
VAL_ 1416 MO7_PTC_bereit 0 "kein_3stuf_PTC_verbaut" ;
VAL_ 1416 MO7_Gen_ein 1 "Generator_ein" 0 "Generator_aus" ;
VAL_ 1416 MO7_Lastabwurf 3 "Stufe_3" 2 "Stufe_2" 1 "Stufe_1" 0 "Stufe_0" ;
VAL_ 1416 MO7_StaGluehk 15 "Fehler" ;
VAL_ 1416 MO7_Lastabw_Heiz 1 "Hochleistungsheizsys_aktivierbar" 0 "Hochleistungsheizsys_deaktiviert" ;
VAL_ 1416 MO7_SleepInd 1 "Sleep_bereit" 0 "CAN_wird_benoetigt" ;
VAL_ 1416 MO7_Zus_Kuehl 1 "ja" 0 "nein" ;
VAL_ 1416 MO7_Mot_weckfaehig 1 "Wecken_ACAN_gef" 0 "kein_Wecken_ACAN" ;
VAL_ 1416 MO7_Ladedruckneu 255 "Fehler" ;
VAL_ 1408 MFN_Ansaugsys 1 "Sauger" 0 "Turbo" ;
VAL_ 1408 MFN_KurzzeitMW 255 "Fehler" 0 "kein_Wert" ;
VAL_ 1408 MFN_Russindex 65535 "Fehler" ;
VAL_ 1408 MFN_NormedTrip 1 "erkannt" 0 "nicht_erkannt" ;
VAL_ 1408 MFN_Verbrenn_Typ 1 "Otto" 0 "Diesel" ;
VAL_ 1408 MFN_Warmup_Cycle 1 "erkannt" 0 "nicht_erkannt" ;
VAL_ 1408 MFN_Verschl 65535 "Fehler" ;
VAL_ 1408 MFN_Drive_Cycle 1 "erkannt" 0 "nicht_erkannt" ;
VAL_ 1408 MFN_Anz_Mittel 0 "Fehler" ;
VAL_ 1408 MFN_Oelwarnung 1 "Warnung" 0 "keine_Warnung" ;
VAL_ 1408 MFN_Sensorwarn 1 "Warnung" 0 "keine_Warnung" ;
VAL_ 1408 MFN_Str_Mittel 0 "Fehler" ;
VAL_ 1408 MFN_Fuell_Erk 1 "aktiviert" 0 "deaktiviert" ;
VAL_ 1408 MFN_Ansaugsys_ 1 "Sauger" 0 "Turbo" ;
VAL_ 1408 MFN_Russindex_ 65535 "Fehler" ;
VAL_ 1408 MFN_Verschl_ 65535 "Fehler" ;
VAL_ 1160 MO6_Hoeheninfo 255 "Fehler" ;
VAL_ 1160 MO6_SollM_Getr 255 "Fehler" ;
VAL_ 1160 MO6_GRA_Soll 255 "nicht_erlaubt" 254 "GRA_aus" ;
VAL_ 1160 MO6_MomIntGeEing 255 "volle_Verfuegbarkeit_akt_vorh" 0 "Integral_bis_Limit_gefuellt" ;
VAL_ 1160 MO6_Freigabe_GRA 1 "freigegeben" 0 "nicht_freigegeben" ;
VAL_ 1160 MO6_Schutz_Toel 1 "Schaltanforderung" 0 "keine_Anforderung" ;
VAL_ 1160 MO6_Ist_Moment 255 "Fehler" ;
VAL_ 1160 MO6_RegPartikel 1 "Beeinflussung" 0 "keine_Beeinflussung" ;
VAL_ 1160 MO6_Luftpfad_akt 1 "Eingriff_ueber_Luftpfad" 0 "keinEingriff_od_nur_ueb_Zundpfad" ;
VAL_ 1160 MO6_FF_Mux00 255 "Init" ;
VAL_ 1160 MO6_FF_Mux01 255 "Init" ;
VAL_ 1160 MO6_FF_Mux02 255 "Init" ;
VAL_ 1160 MO6_FF_Mux03 255 "K_Leitung_od_Init" ;
VAL_ 1160 MO6_FF_Mux05 255 "nicht_genutzt" ;
VAL_ 1160 MO6_FF_Mux06 255 "nicht_genutzt" ;
VAL_ 1160 MO6_FF_Mux04 255 "K_Leitung_od_Init" ;
VAL_ 1160 MO6_FF_Mux08 255 "nicht_genutzt" ;
VAL_ 1160 MO6_FF_Mux07 255 "nicht_genutzt" ;
VAL_ 1160 MO6_FF_Mux09 255 "nicht_genutzt" ;
VAL_ 1160 MO6_FF_Mux10 255 "nicht_genutzt" ;
VAL_ 1160 MO6_FF_Mux11 255 "nicht_genutzt" ;
VAL_ 1160 MO6_FF_Mux12 255 "nicht_genutzt" ;
VAL_ 1160 MO6_FF_Mux14 255 "nicht_genutzt" ;
VAL_ 1160 MO6_FF_Mux13 255 "nicht_genutzt" ;
VAL_ 1160 MO6_FF_Mux15 255 "nicht_genutzt" ;
VAL_ 1152 MO5_Mp_Code 3 "Abgastyp_od_norm_Verbrauch" 2 "Motor_Typ" 1 "Drehzahl" 0 "Max_Moment" ;
VAL_ 1152 MO5_Vorgluehen 1 "Lampe_ein" 0 "Lampe_aus" ;
VAL_ 1152 MO5_E_Gas 1 "Lampe_ein" 0 "Lampe_aus" ;
VAL_ 1152 MO5_OBD_2 1 "Lampe_ein" 0 "Lampe_aus" ;
VAL_ 1152 MO5_KliKo_Red 1 "ja" 0 "nein" ;
VAL_ 1152 MO5_Heissl 1 "Lampe_ein" 0 "Lampe_aus" ;
VAL_ 1152 MO5_KlimaKompr 1 "Klimakompr_aus" 0 "keine_Anforderung" ;
VAL_ 1152 MO5_Feld_kuehl 1 "ja" 0 "nein" ;
VAL_ 1152 MO5_UeberlVerb 1 "mindestens_einmal_uebergelaufen" 0 "kein_Ueberlauf" ;
VAL_ 1152 MO5_Momente 1 "Doppelt" 0 "Einfach" ;
VAL_ 1152 MO5_Luefter 255 "Fehler" 0 "keine_Anforderung" ;
VAL_ 1152 MO5_Start 1 "Startfreigabe" 0 "Start_nicht_zulaessig" ;
VAL_ 1152 MO5_HLeuchte 1 "Vorwarnung" 0 "keine_Warnung" ;
VAL_ 1152 MO5_Anlasser 1 "Anlasser_ausspuren" 0 "Motor_laeuft_nicht_stabil" ;
VAL_ 1152 MO5_Motortext1 1 "Text_1" 0 "kein_Text" ;
VAL_ 1152 MO5_GRA_Hauptsch 1 "ein" 0 "aus" ;
VAL_ 1152 MO5_Interlock 1 "Interlock_betaetigt" 0 "Interlock_nicht_betaetigt" ;
VAL_ 1152 MO5_Sta_BKU 1 "n_iO" 0 "iO_oder_nicht_verbaut" ;
VAL_ 1152 MO5_TypStartSteu 1 "Automatikstart" 0 "Start_BSG_Kessy_oder_Fahrer" ;
VAL_ 1152 MO5_PartikelLamp 1 "Lampe_ein" 0 "Lampe_aus" ;
VAL_ 1152 MO5_Motortext4 1 "Text_4" 0 "kein_Text" ;
VAL_ 1152 MO5_TDE_Text 1 "Textanzeige_nach_ISO" 0 "kein_Text" ;
VAL_ 1152 MO5_Motortext3 1 "Text_3" 0 "kein_Text" ;
VAL_ 1152 MO5_Motortext2 1 "Text_2" 0 "kein_Text" ;
VAL_ 1152 MO5_Abgastyp2 1 "OBD" 0 "kein_OBD" ;
VAL_ 1152 MO5_TDE_Lampe 1 "Lampe_ein" 0 "Lampe_aus" ;
VAL_ 1152 MO5_Abgastyp 1 "EOBD" 0 "kein_EOBD" ;
VAL_ 1152 MO5_DZM_Daempf 1 "dynamische_Daempfung" 0 "normale_Daempfung" ;
VAL_ 1152 MO5_Abgastyp3 1 "DPF_verbaut" 0 "kein_DPF_verbaut" ;
VAL_ 1152 MO5_DPF_reg 1 "DPF_regeneriert" 0 "DPF_regeneriert_nicht" ;
VAL_ 640 MO1_Leergas 1 "Leergas" 0 "kein_Leergas" ;
VAL_ 640 MO1_TiOut_Br 1 "Time_Out" 0 "Empfang_iO" ;
VAL_ 640 MO1_Sta_Bremse 1 "statisch_nicht_erfuellbar" 0 "erfuellbar" ;
VAL_ 640 MO1_Kickdown 1 "Kickdown" 0 "kein_Kickdown" ;
VAL_ 640 MO1_Sta_Pedal 1 "Ersatzwert" 0 "Fahrpedal_iO" ;
VAL_ 640 MO1_Kup_schalt 1 "Schalter_sagt_eingekuppelt" 0 "Schalter_sagt_ausgekuppelt" ;
VAL_ 640 MO1_Sta_Getr 1 "dynamisch_nicht_erfuellbar" 0 "erfuellbar" ;
VAL_ 640 MO1_Pedalwert 255 "Fehler" ;
VAL_ 640 MO1_Sta_MotMo 1 "ja" 0 "nein_Werte_iO" ;
VAL_ 640 MO1_Mo_m_ex 255 "Fehler" ;
VAL_ 640 MO1_Verlustmo 255 "Fehler" ;
VAL_ 640 MO1_Mo_o_ex 255 "Fehler" ;
VAL_ 640 MO1_Drehzahl 65280 "Fehler" ;
VAL_ 640 MO1_Wunschmo 255 "Fehler" ;
VAL_ 1154 MH1_VM_Mom_oE 255 "Fehler" ;
VAL_ 1154 MH1_IstStatusK0 3 "Fehler" 2 "zu" 1 "Uebergang" 0 "auf" ;
VAL_ 1154 MH1_Startmodus_PQ35 1 "Direktstart" 0 "Impulsstart" ;
VAL_ 1154 MH1_VM_aktiv 1 "VM_aktiv" 0 "VM_nicht_aktiv" ;
VAL_ 1154 MH1_Zielzustand_Hybrid 7 "Fehler" 5 "Fahrbereit_VM" 4 "Fahrbereit_EM" 3 "EM_Fahren" 2 "hyb_Fahren" 1 "LL_VM" 0 "Init" ;
VAL_ 1154 MH1_VerlParam_Msum 3 "KnickDZ_EM_Kurve" 2 "max_EM_Moment" 1 "KnickDZ_Rekup_Kurve" 0 "max_Rekup_Mom" ;
VAL_ 1154 MH1_E_Faktor 15 "minus1" 14 "minus2" 13 "minus3" 12 "minus4" 11 "minus5" 10 "minus6" 9 "minus7" 8 "minus8" 7 "plus7" 6 "plus6" 5 "plus5" 4 "plus4" 3 "plus3" 2 "plus2" 1 "plus1" 0 "VM_Kennfeld" ;
VAL_ 1154 MH1_Drehzahl_VM 65280 "Fehler" ;
VAL_ 1154 MH1_Schaltverh 1 "Schaltverhinderung" 0 "keine_Schaltverh" ;
VAL_ 1154 MH1_max_ind_VM_Mom 255 "Fehler" 254 "Init" ;
VAL_ 1154 MH1_Startmodus_PL71 7 "Impulsstart" 6 "anger_pwr" 5 "anger_trq" 4 "anger_comf" 3 "slipstart_pwr" 2 "slipstart_trq" 1 "slipstart_comf" 0 "Drag_Start" ;
VAL_ 1154 MH1_ACCGRA_aktiv 1 "GRAACC_aktiv" 0 "GRAACC_nicht_aktiv" ;
VAL_ 1154 MH1_LowSpeedModus 1 "LowSpeed_ohne_LL_DZ" 0 "LowSpeed_mit_LL_DZ" ;
VAL_ 1154 MH1_Bremspedalwert 255 "Fehler" ;
VAL_ 1154 MH1_QB_Bremspedalwert 1 "Ersatz_Init_Fehler" 0 "gueltiger_Wert" ;
VAL_ 644 MOB_Bremsmom 8191 "Fehler" ;
VAL_ 644 MOB_Anhaltewunsch 1 "Fzg_haelt_an" 0 "kein_Haltewunsch" ;
VAL_ 644 MOB_Freigabe 1 "Bremsanf_freigegeben" 0 "Bremsanf_nicht_freigegeb" ;
VAL_ 644 MOB_Standby 1 "Bremse_in_Vorhaltposition_bringe" 0 "Bremse_in_0_Stellung" ;
VAL_ 1162 MO8_LampeDZBegr 1 "Lampe_ein" 0 "Lampe_aus" ;
VAL_ 1162 MO8_Spoiler_ausf 1 "Spoiler_ausfahren" 0 "Spoiler_nicht_ausfahren" ;
VAL_ 1162 MO8_AnzeigeDZ 4095 "Fehler" ;
VAL_ 1162 MO8_SGT_Soundakt 1 "Anf_des_Stellgliedtests" 0 "kein_Stellgliedtest" ;
VAL_ 1162 MO8_Enable_Oeldr_Motor 1 "Oeldruckausw_Motor" 0 "Oeldruckausw_Kombi" ;
VAL_ 1162 MO8_Sportschalter 1 "Sportschalter_aktiv" 0 "Sportschalter_nicht_aktiv" ;
VAL_ 1162 MO8_Oeldr_Warn_Motor 1 "Lampe_ein" 0 "Lampe_aus" ;
VAL_ 1162 MO8_Avus_Motorschutz 3 "DZwarnung_3" 2 "DZwarnung_2" 1 "DZwarnung_1" 0 "keine_Warnung" ;
VAL_ 1162 MO8_Nachlauf_ZWP 0 "INIT" ;
